VERSION ""

NS_ :

BS_:

BU_: IDCM ARC ARHUD WHUD VSP FSE_M CGW

BO_ 763 TBOX_FD_8: 32 CGW
 SG_ TBOX_FD_8_Checksum1 : 0|8@1+ (1,0) [0|255] ""  IDCM,ARC,WHUD
 SG_ TBOX_FD_8_RollingCounter1 : 8|4@1+ (1,0) [0|15] ""  IDCM,ARC,WHUD
 SG_ TBOX_V2XOutofControl_Distance : 16|8@1+ (1,0) [0|254] ""  IDCM,ARC,WHUD
 SG_ TBOX_V2XOutofControl_St : 24|2@1+ (1,0) [0|3] ""  IDCM,ARC,WHUD
 SG_ TBOX_V2XOutofControl_AlarmLevel : 26|2@1+ (1,0) [0|3] ""  IDCM,ARC,WHUD
 SG_ TBOX_V2XOutofControl_Angle : 28|10@1+ (1,0) [0|359] "°"  IDCM,ARC,WHUD
 SG_ TBOX_FD_8_Checksum2 : 64|8@1+ (1,0) [0|255] ""  IDCM,ARC,WHUD
 SG_ TBOX_FD_8_RollingCounter2 : 72|4@1+ (1,0) [0|15] ""  IDCM,ARC,WHUD
 SG_ TBOX_V2XBlindSpotorLaneChangeWarn_Type : 80|4@1+ (1,0) [0|15] ""  IDCM,ARC,WHUD
 SG_ TBOX_V2XBlindSpotorLaneChangeWarn_St : 84|2@1+ (1,0) [0|3] ""  IDCM,ARC,WHUD
 SG_ TBOX_V2XBlindSpotorLaneChangeWarn_AlarmLevel : 86|2@1+ (1,0) [0|3] ""  IDCM,ARC,WHUD
 SG_ TBOX_V2XBlindSpotorLaneChangeWarn_Distance : 88|8@1+ (1,0) [0|254] "m"  IDCM,ARC,WHUD
 SG_ TBOX_V2XBlindSpotorLaneChangeWarn_Direction : 96|4@1+ (1,0) [0|15] ""  IDCM,ARC,WHUD
 SG_ TBOX_FD_8_Checksum3 : 128|8@1+ (1,0) [0|255] ""  IDCM,ARC,WHUD
 SG_ TBOX_FD_8_RollingCounter3 : 136|4@1+ (1,0) [0|15] ""  IDCM,ARC,WHUD
 SG_ TBOX_V2XEmergencyVehicleWarn_Distance : 144|8@1+ (1,0) [0|254] "m"  IDCM,ARC,WHUD
 SG_ TBOX_V2XEmergencyVehicleWarn_St : 152|2@1+ (1,0) [0|3] ""  IDCM,ARC,WHUD
 SG_ TBOX_V2XEmergencyVehicleWarn_AlarmLevel : 154|2@1+ (1,0) [0|3] ""  IDCM,ARC,WHUD
 SG_ TBOX_V2XEmergencyVehicleWarn_Type : 156|3@1+ (1,0) [0|7] ""  IDCM,ARC,WHUD
 SG_ TBOX_V2XEmergencyVehicleWarn_Angle : 160|10@1+ (1,0) [0|359] "°"  IDCM,ARC,WHUD

BO_ 764 TBOX_FD_9: 32 CGW
 SG_ TBOX_FD_9_Checksum1 : 0|8@1+ (1,0) [0|255] ""  IDCM,ARC,WHUD
 SG_ TBOX_FD_9_RollingCounter1 : 8|4@1+ (1,0) [0|15] ""  IDCM,ARC,WHUD
 SG_ TBOX_V2XVulnerableTrafficParticipantsWarn_Distance : 16|8@1+ (1,0) [0|254] "m"  IDCM,ARC,WHUD
 SG_ TBOX_V2XVulnerableTrafficParticipantsWarn_St : 24|2@1+ (1,0) [0|3] ""  IDCM,ARC,WHUD
 SG_ TBOX_V2XVulnerableTrafficParticipantsWarn_AlarmLevel : 26|2@1+ (1,0) [0|3] ""  IDCM,ARC,WHUD
 SG_ TBOX_V2XVulnerableTrafficParticipantsWarn_Participant : 28|3@1+ (1,0) [0|7] ""  IDCM,ARC,WHUD
 SG_ TBOX_V2XVulnerableTrafficParticipantsWarn_Angle : 32|10@1+ (1,0) [0|359] "°"  IDCM,ARC,WHUD
 SG_ TBOX_FD_9_Checksum2 : 64|8@1+ (1,0) [0|255] ""  IDCM,ARC,WHUD
 SG_ TBOX_FD_9_RollingCounter2 : 72|4@1+ (1,0) [0|15] ""  IDCM,ARC,WHUD
 SG_ TBOX_V2XInVehicleSignage_Direction : 80|4@1+ (1,0) [0|15] ""  IDCM,ARC,WHUD
 SG_ TBOX_V2XInVehicleSignage_Type : 84|4@1+ (1,0) [0|15] ""  IDCM,ARC,WHUD
 SG_ TBOX_V2XInVehicleSignage_Distance : 88|8@1+ (1,0) [0|254] "m"  IDCM,ARC,WHUD
 SG_ TBOX_V2XInVehicleSignage_St : 96|2@1+ (1,0) [0|3] ""  IDCM,ARC,WHUD
 SG_ TBOX_V2XInVehicleSignage_AlarmLevel : 98|2@1+ (1,0) [0|3] ""  IDCM,ARC,WHUD
 SG_ TBOX_V2XRoadHazardWarn_St : 100|2@1+ (1,0) [0|3] ""  IDCM,ARC,WHUD
 SG_ TBOX_V2XRoadHazardWarn_AlarmLevel : 102|2@1+ (1,0) [0|3] ""  IDCM,ARC,WHUD
 SG_ TBOX_V2XRoadHazardWarn_Distance : 104|8@1+ (1,0) [0|254] "m"  IDCM,ARC,WHUD
 SG_ TBOX_V2XRoadHazardWarn_Direction : 112|4@1+ (1,0) [0|15] ""  IDCM,ARC,WHUD
 SG_ TBOX_V2XRoadHazardWarn_DangerTypes : 116|4@1+ (1,0) [0|15] ""  IDCM,ARC,WHUD
 SG_ TBOX_FD_9_Checksum3 : 128|8@1+ (1,0) [0|255] ""  IDCM,ARC,WHUD
 SG_ TBOX_FD_9_RollingCounter3 : 136|4@1+ (1,0) [0|15] ""  IDCM,ARC,WHUD
 SG_ TBOX_V2XGreenWaveSpeedGuidance_Distance : 144|8@1+ (1,0) [0|254] "m"  IDCM,ARC,WHUD
 SG_ TBOX_V2XGreenWaveSpeedGuidance_Countdown : 152|8@1+ (1,0) [0|254] "s"  IDCM,ARC,WHUD
 SG_ TBOX_V2XGreenWaveSpeedGuidance_MinSpeed : 160|8@1+ (1,0) [0|120] "km/h"  IDCM,ARC,WHUD
 SG_ TBOX_V2XGreenWaveSpeedGuidance_MaxSpeed : 168|8@1+ (1,0) [0|120] "km/h"  IDCM,ARC,WHUD
 SG_ TBOX_V2XGreenWaveSpeedGuidance_TrafficLightPoint : 176|4@1+ (1,0) [0|15] ""  IDCM,ARC,WHUD
 SG_ TBOX_V2XGreenWaveSpeedGuidance_TrafficLightSt : 180|3@1+ (1,0) [0|7] ""  IDCM,ARC,WHUD
 SG_ TBOX_V2XGreenWaveSpeedGuidance_St : 184|2@1+ (1,0) [0|3] ""  IDCM,ARC,WHUD

BO_ 765 TBOX_FD_10: 32 CGW
 SG_ TBOX_FD_10_Checksum1 : 0|8@1+ (1,0) [0|255] ""  IDCM,ARC,WHUD
 SG_ TBOX_FD_10_RollingCounter1 : 8|4@1+ (1,0) [0|15] ""  IDCM,ARC,WHUD
 SG_ TBOX_V2XRealtimeTrafficInformation_St : 16|2@1+ (1,0) [0|3] ""  IDCM,ARC,WHUD
 SG_ TBOX_V2XRealtimeTrafficInformation_Direction : 18|4@1+ (1,0) [0|15] ""  IDCM,ARC,WHUD
 SG_ TBOX_V2XRealtimeTrafficInformation_AlarmLevel : 22|2@1+ (1,0) [0|3] ""  IDCM,ARC,WHUD
 SG_ TBOX_V2XRealtimeTrafficInformation_Distance : 24|8@1+ (1,0) [0|254] "m"  IDCM,ARC,WHUD
 SG_ TBOX_V2XRealtimeTrafficInformation_Type : 32|4@1+ (1,0) [0|15] ""  IDCM,ARC,WHUD
 SG_ TBOX_V2XRealtimeTrafficInformation_Severity : 36|4@1+ (1,0) [0|15] ""  IDCM,ARC,WHUD
 SG_ TBOX_V2XRushRedLightWarn_Distance : 40|8@1+ (1,0) [0|254] "m"  IDCM,ARC,WHUD
 SG_ TBOX_V2XRushRedLightWarn_St : 48|2@1+ (1,0) [0|3] ""  IDCM,ARC,WHUD
 SG_ TBOX_V2XRushRedLightWarn_AlarmLevel : 50|2@1+ (1,0) [0|3] ""  IDCM,ARC,WHUD
 SG_ TBOX_V2XSpeedLimitWarn_St : 52|2@1+ (1,0) [0|3] ""  IDCM,ARC,WHUD
 SG_ TBOX_V2XSpeedLimitWarn_AlarmLevel : 54|2@1+ (1,0) [0|3] ""  IDCM,ARC,WHUD
 SG_ TBOX_V2XSpeedLimitWarn_Speed : 56|8@1+ (1,0) [0|120] "km/h"  IDCM,ARC,WHUD
 SG_ TBOX_FD_10_Checksum2 : 64|8@1+ (1,0) [0|255] ""  IDCM
 SG_ TBOX_FD_10_RollingCounter2 : 72|4@1+ (1,0) [0|15] ""  IDCM
 SG_ TBOX_V2X_St : 80|2@1+ (1,0) [0|3] ""  IDCM

BO_ 887 TBOX_FD_18: 32 CGW
 SG_ TBOX_AccountIDByte1 : 0|8@1+ (1,0) [0|255] ""  IDCM
 SG_ TBOX_AccountIDByte2 : 8|8@1+ (1,0) [0|255] ""  IDCM
 SG_ TBOX_AccountIDByte3 : 16|8@1+ (1,0) [0|255] ""  IDCM
 SG_ TBOX_AccountIDByte4 : 24|8@1+ (1,0) [0|255] ""  IDCM
 SG_ TBOX_AccountIDByte5 : 32|8@1+ (1,0) [0|255] ""  IDCM
 SG_ TBOX_AccountIDByte6 : 40|8@1+ (1,0) [0|255] ""  IDCM
 SG_ TBOX_AccountIDByte7 : 48|8@1+ (1,0) [0|255] ""  IDCM
 SG_ TBOX_AccountIDByte8 : 56|8@1+ (1,0) [0|255] ""  IDCM
 SG_ TBOX_AccountIDByte9 : 64|8@1+ (1,0) [0|255] ""  IDCM
 SG_ TBOX_AccountIDByte10 : 72|8@1+ (1,0) [0|255] ""  IDCM
 SG_ TBOX_AccountIDByte11 : 80|8@1+ (1,0) [0|255] ""  IDCM
 SG_ TBOX_AccountIDByte12 : 88|8@1+ (1,0) [0|255] ""  IDCM
 SG_ TBOX_AccountIDByte13 : 96|8@1+ (1,0) [0|255] ""  IDCM
 SG_ TBOX_AccountIDByte14 : 104|8@1+ (1,0) [0|255] ""  IDCM
 SG_ TBOX_AccountIDByte15 : 112|8@1+ (1,0) [0|255] ""  IDCM
 SG_ TBOX_AccountIDByte16 : 120|8@1+ (1,0) [0|255] ""  IDCM
 SG_ TBOX_AccountIDByte17 : 128|8@1+ (1,0) [0|255] ""  IDCM
 SG_ TBOX_AccountIDByte18 : 136|8@1+ (1,0) [0|255] ""  IDCM
 SG_ TBOX_AccountIDByte19 : 144|8@1+ (1,0) [0|255] ""  IDCM
 SG_ TBOX_AccountIDByte20 : 152|8@1+ (1,0) [0|255] ""  IDCM
 SG_ TBOX_AccountIDByte21 : 160|8@1+ (1,0) [0|255] ""  IDCM
 SG_ TBOX_AccountIDByte22 : 168|8@1+ (1,0) [0|255] ""  IDCM
 SG_ TBOX_AccountIDByte23 : 176|8@1+ (1,0) [0|255] ""  IDCM
 SG_ TBOX_AccountIDByte24 : 184|8@1+ (1,0) [0|255] ""  IDCM
 SG_ TBOX_AccountIDByte25 : 192|8@1+ (1,0) [0|255] ""  IDCM
 SG_ TBOX_AccountIDByte26 : 200|8@1+ (1,0) [0|255] ""  IDCM
 SG_ TBOX_AccountIDByte27 : 208|8@1+ (1,0) [0|255] ""  IDCM
 SG_ TBOX_AccountIDByte28 : 216|8@1+ (1,0) [0|255] ""  IDCM
 SG_ TBOX_AccountIDByte29 : 224|8@1+ (1,0) [0|255] ""  IDCM
 SG_ TBOX_AccountIDByte30 : 232|8@1+ (1,0) [0|255] ""  IDCM
 SG_ TBOX_AccountIDByte31 : 240|8@1+ (1,0) [0|255] ""  IDCM
 SG_ TBOX_AccountIDByte32 : 248|8@1+ (1,0) [0|255] ""  IDCM

BO_ 882 TBOX_FD_19: 32 CGW
 SG_ TBOX_XCALLIDByte0 : 0|8@1+ (1,0) [0|255] ""  IDCM
 SG_ TBOX_XCALLIDByte1 : 8|8@1+ (1,0) [0|255] ""  IDCM
 SG_ TBOX_XCALLIDByte2 : 16|8@1+ (1,0) [0|255] ""  IDCM
 SG_ TBOX_XCALLIDByte3 : 24|8@1+ (1,0) [0|255] ""  IDCM
 SG_ TBOX_XCALLIDByte4 : 32|8@1+ (1,0) [0|255] ""  IDCM
 SG_ TBOX_XCALLIDByte5 : 40|8@1+ (1,0) [0|255] ""  IDCM
 SG_ TBOX_XCALLIDByte6 : 48|8@1+ (1,0) [0|255] ""  IDCM
 SG_ TBOX_XCALLIDByte7 : 56|8@1+ (1,0) [0|255] ""  IDCM
 SG_ TBOX_XCALLIDByte8 : 64|8@1+ (1,0) [0|255] ""  IDCM
 SG_ TBOX_XCALLIDByte9 : 72|8@1+ (1,0) [0|255] ""  IDCM

BO_ 503 ADCM_FD_2: 32 CGW
 SG_ ADCM_FD2_Checksum1 : 0|8@1+ (1,0) [0|255] ""  IDCM,ARC,WHUD
 SG_ ADCM_FD2_RollingCounter1 : 8|4@1+ (1,0) [0|15] ""  IDCM,ARC,WHUD
 SG_ ADCM_LKS_TakeoverReq : 12|1@1+ (1,0) [0|1] ""  IDCM
 SG_ ADCM_LKS_St : 13|3@1+ (1,0) [0|7] ""  IDCM,ARC,WHUD
 SG_ ADCM_LKS_Type_Set : 16|2@1+ (1,0) [0|3] ""  IDCM,ARC,WHUD
 SG_ ADCM_LKS_Left_Active_St : 18|3@1+ (1,0) [0|7] ""  IDCM,ARC,WHUD
 SG_ ADCM_LKS_Right_Active_St : 21|3@1+ (1,0) [0|7] ""  IDCM,ARC,WHUD
 SG_ ADCM_LKS_Sensitivity_Set : 24|2@1+ (1,0) [0|3] ""  IDCM
 SG_ ADCM_ELK_St : 26|3@1+ (1,0) [0|7] ""  IDCM,ARC,WHUD
 SG_ ADCM_ELK_Left_Active_St : 29|3@1+ (1,0) [0|7] ""  IDCM,ARC,WHUD
 SG_ ADCM_ELK_Right_Active_St : 32|3@1+ (1,0) [0|7] ""  IDCM,ARC,WHUD
 SG_ ADCM_RCW_St : 35|3@1+ (1,0) [0|7] ""  IDCM,ARC,WHUD
 SG_ ADCM_RCW_Warn_St : 38|2@1+ (1,0) [0|3] ""  IDCM,ARC,WHUD
 SG_ ADCM_LCA_St : 40|3@1+ (1,0) [0|7] ""  IDCM,ARC,WHUD
 SG_ ADCM_LCA_Right_Warn_St : 43|2@1+ (1,0) [0|3] ""  IDCM,ARC,WHUD
 SG_ ADCM_LCA_Left_Warn_St : 45|2@1+ (1,0) [0|3] ""  IDCM,ARC,WHUD
 SG_ ADCM_RCTA_St : 48|3@1+ (1,0) [0|7] ""  IDCM
 SG_ ADCM_RCTA_Right_Warn_St : 51|2@1+ (1,0) [0|3] ""  IDCM
 SG_ ADCM_RCTA_Left_Warn_St : 53|2@1+ (1,0) [0|3] ""  IDCM
 SG_ ADCM_AHB_St : 56|3@1+ (1,0) [0|7] ""  IDCM
 SG_ ADCM_AHB_Ctrl_St : 59|2@1+ (1,0) [0|3] ""  IDCM
 SG_ ADCM_FD2_Checksum2 : 64|8@1+ (1,0) [0|255] ""  IDCM,ARC,WHUD
 SG_ ADCM_FD2_RollingCounter2 : 72|4@1+ (1,0) [0|15] ""  IDCM,ARC,WHUD
 SG_ ADCM_ACC_UnavailableReason : 76|4@1+ (1,0) [0|15] ""  IDCM
 SG_ ADCM_ACC_St : 80|3@1+ (1,0) [0|7] ""  IDCM,ARC,WHUD
 SG_ ADCM_ACC_Warn_St : 83|3@1+ (1,0) [0|7] ""  IDCM
 SG_ ADCM_ACC_TimeGap : 86|2@1+ (1,0) [0|3] ""  IDCM
 SG_ ADCM_ACC_TargetSpeed : 88|7@1+ (1,30) [30|150] "kph"  IDCM,ARC,WHUD
 SG_ ADCM_ACC_GoNotifier : 95|1@1+ (1,0) [0|1] ""  IDCM
 SG_ ADCM_ISA_St : 96|3@1+ (1,0) [0|7] ""  IDCM,ARC,WHUD
 SG_ ADCM_ISA_LimitSpeed : 99|5@1+ (1,0) [0|31] ""  IDCM,ARC,WHUD
 SG_ ADCM_ISA_Operating_St : 104|3@1+ (1,0) [0|7] ""  IDCM
 SG_ ADCM_ISA_Warn_St : 107|1@1+ (1,0) [0|1] "-"  IDCM,ARC,WHUD
 SG_ ADCM_ISA_SpeedLimitype : 108|2@1+ (1,0) [0|3] "-"  IDCM
 SG_ ADCM_ISA_SpeedLimitUnit : 110|2@1+ (1,0) [0|3] ""  IDCM
 SG_ ADCM_ISA_WarningOffset_Set : 112|3@1+ (1,0) [0|7] ""  IDCM
 SG_ ADCM_ValetMode_AccDisable_St : 115|2@1+ (1,0) [0|3] ""  IDCM
 SG_ ADCM_FD2_Checksum3 : 128|8@1+ (1,0) [0|255] ""  IDCM,ARC,WHUD
 SG_ ADCM_FD2_RollingCounter3 : 136|4@1+ (1,0) [0|15] ""  IDCM,ARC,WHUD
 SG_ ADCM_FCS_TargetType : 140|4@1+ (1,0) [0|15] ""  IDCM,ARC,WHUD
 SG_ ADCM_FCS_St : 144|3@1+ (1,0) [0|7] ""  IDCM,ARC,WHUD
 SG_ ADCM_FCS_Active_St : 147|3@1+ (1,0) [0|7] ""  IDCM,ARC,WHUD
 SG_ ADCM_FCTA_Left_TargetType : 152|4@1+ (1,0) [0|15] ""  IDCM
 SG_ ADCM_FCTA_Right_TargetType : 156|4@1+ (1,0) [0|15] ""  IDCM
 SG_ ADCM_FCTA_Left_Active_St : 160|3@1+ (1,0) [0|7] ""  IDCM,ARC,WHUD
 SG_ ADCM_FCTA_Right_Active_St : 163|3@1+ (1,0) [0|7] ""  IDCM,ARC,WHUD
 SG_ ADCM_FCTA_St : 168|3@1+ (1,0) [0|7] ""  IDCM,ARC,WHUD
 SG_ ADCM_DetecCloseObjectFunctionRsp : 171|2@1+ (1,0) [0|3] ""  IDCM
 SG_ ADCM_DOW_St : 173|3@1+ (1,0) [0|7] ""  IDCM
 SG_ ADCM_DOW_FL_Warn_St : 176|2@1+ (1,0) [0|3] ""  IDCM
 SG_ ADCM_DOW_RL_Warn_St : 178|2@1+ (1,0) [0|3] ""  IDCM
 SG_ ADCM_DOW_FR_Warn_St : 180|2@1+ (1,0) [0|3] ""  IDCM
 SG_ ADCM_DOW_RR_Warn_St : 182|2@1+ (1,0) [0|3] ""  IDCM
 SG_ ADCM_FRCloseObjectWarn : 184|2@1+ (1,0) [0|3] ""  IDCM
 SG_ ADCM_RLCloseObjectWarn : 186|2@1+ (1,0) [0|3] ""  IDCM
 SG_ ADCM_RRCloseObjectWarn : 188|2@1+ (1,0) [0|3] ""  IDCM
 SG_ ADCM_FLCloseObjectWarn : 190|2@1+ (1,0) [0|3] ""  IDCM

BO_ 505 ADCM_FD_3: 32 CGW
 SG_ ADCM_FD3_Checksum1 : 0|8@1+ (1,0) [0|255] ""  IDCM,ARC,WHUD
 SG_ ADCM_FD3_RollingCounter1 : 8|4@1+ (1,0) [0|15] ""  IDCM,ARC,WHUD
 SG_ ADCM_Pilot_Warn_St : 12|4@1+ (1,0) [0|15] ""  IDCM,ARC,WHUD
 SG_ ADCM_Pilot_Type : 16|3@1+ (1,0) [0|3] ""  IDCM,ARC,WHUD
 SG_ ADCM_Pilot_Available_St : 19|3@1+ (1,0) [0|3] ""  IDCM,ARC,WHUD
 SG_ ADCM_PilotLateral_St : 24|3@1+ (1,0) [0|7] ""  IDCM,ARC,WHUD
 SG_ ADCM_FD3_Checksum2 : 64|8@1+ (1,0) [0|255] ""  IDCM
 SG_ ADCM_FD3_RollingCounter2 : 72|4@1+ (1,0) [0|15] ""  IDCM
 SG_ ADCM_HWA_ILC_Left_St : 76|4@1+ (1,0) [0|15] ""  IDCM
 SG_ ADCM_HWA_ILC_Right_St : 80|4@1+ (1,0) [0|15] ""  IDCM
 SG_ ADCM_HWA_ILC_Set : 84|2@1+ (1,0) [0|3] ""  IDCM
 SG_ ADCM_HWA_ILC_TurnLampReq : 86|2@1+ (1,0) [0|3] ""  IDCM
 SG_ ADCM_HWA_ILC_AbortReason : 88|4@1+ (1,0) [0|15] ""  IDCM
 SG_ ADCM_HWA_ILC_Left_Warn : 92|1@1+ (1,0) [0|1] ""  IDCM
 SG_ ADCM_HWA_ILC_Right_Warn : 93|1@1+ (1,0) [0|1] ""  IDCM
 SG_ ADCM_HWA_ILC_HandsonReq : 94|1@1+ (1,0) [0|1] ""  IDCM,ARC,WHUD

BO_ 576 ADCM_FD_4: 32 CGW
 SG_ ADCM_ACC_TrackTarget0_LateralPosition : 0|10@1+ (0.1,-51.2) [-51.2|51] "m"  IDCM,ARC,WHUD
 SG_ ADCM_ACC_TrackTarget0_ObjectType : 10|4@1+ (1,0) [0|15] ""  IDCM,ARC,WHUD
 SG_ ADCM_ACC_TrackTarget0_St : 14|1@1+ (1,0) [0|1] ""  IDCM,ARC,WHUD
 SG_ ADCM_ACC_TrackTarget0_LongitudinalPosition : 16|8@1+ (1,0) [0|254] "m"  IDCM,ARC,WHUD
 SG_ ADCM_ACC_TrackTarget1_LateralPosition : 32|10@1+ (0.1,-51.2) [-51.2|51] "m"  IDCM,ARC,WHUD
 SG_ ADCM_ACC_TrackTarget1_ObjectType : 42|4@1+ (1,0) [0|15] ""  IDCM,ARC,WHUD
 SG_ ADCM_ACC_TrackTarget1_St : 46|1@1+ (1,0) [0|1] ""  IDCM,ARC,WHUD
 SG_ ADCM_ACC_TrackTarget1_LongitudinalPosition : 48|8@1+ (1,0) [0|254] "m"  IDCM,ARC,WHUD
 SG_ ADCM_ACC_TrackTarget2_LateralPosition : 64|10@1+ (0.1,-51.2) [-51.2|51] "m"  IDCM,ARC,WHUD
 SG_ ADCM_ACC_TrackTarget2_ObjectType : 74|4@1+ (1,0) [0|15] ""  IDCM,ARC,WHUD
 SG_ ADCM_ACC_TrackTarget2_St : 78|1@1+ (1,0) [0|1] ""  IDCM,ARC,WHUD
 SG_ ADCM_ACC_TrackTarget2_LongitudinalPosition : 80|8@1+ (1,0) [0|254] "m"  IDCM,ARC,WHUD
 SG_ ADCM_ACC_TrackTarget3_LateralPosition : 96|10@1+ (0.1,-51.2) [-51.2|51] "m"  IDCM,ARC,WHUD
 SG_ ADCM_ACC_TrackTarget3_ObjectType : 106|4@1+ (1,0) [0|15] ""  IDCM,ARC,WHUD
 SG_ ADCM_ACC_TrackTarget3_St : 110|1@1+ (1,0) [0|1] ""  IDCM,ARC,WHUD
 SG_ ADCM_ACC_TrackTarget3_LongitudinalPosition : 112|8@1+ (1,0) [0|254] "m"  IDCM,ARC,WHUD

BO_ 578 ADCM_FD_5: 32 CGW
 SG_ ADCM_Line_1_Display : 0|2@1+ (1,0) [0|3] ""  IDCM,ARC,WHUD
 SG_ ADCM_Line_1_Type : 2|4@1+ (1,0) [0|15] ""  IDCM,ARC,WHUD
 SG_ ADCM_Line_1_A0 : 8|11@1+ (0.01,-10.23) [-10.23|10.23] "m"  IDCM,ARC,WHUD
 SG_ ADCM_Line_1_A1 : 20|11@1+ (0.001,-1.023) [-1.023|1.023] "rad"  IDCM,ARC,WHUD
 SG_ ADCM_Line_1_A2 : 32|11@1+ (0.00001,-0.01023) [-0.01023|0.01023] "1/m"  IDCM,ARC,WHUD
 SG_ ADCM_Line_1_A3 : 48|16@1+ (0.00000001,-0.00032768) [-0.00032768|0.00032767] "1/m2"  IDCM,ARC,WHUD
 SG_ ADCM_Line_2_Display : 64|2@1+ (1,0) [0|3] ""  IDCM,ARC,WHUD
 SG_ ADCM_Line_2_Type : 66|4@1+ (1,0) [0|15] ""  IDCM,ARC,WHUD
 SG_ ADCM_Line_2_A0 : 72|11@1+ (0.01,-10.23) [-10.23|10.23] "m"  IDCM,ARC,WHUD
 SG_ ADCM_Line_2_A1 : 84|11@1+ (0.001,-1.023) [-1.023|1.023] "rad"  IDCM,ARC,WHUD
 SG_ ADCM_Line_2_A2 : 96|11@1+ (0.00001,-0.01023) [-0.01023|0.01023] "1/m"  IDCM,ARC,WHUD
 SG_ ADCM_FD5_Reserved8 : 107|5@1+ (1,0) [0|0] ""  IDCM,ARC,WHUD
 SG_ ADCM_Line_2_A3 : 112|16@1+ (0.00000001,-0.00032768) [-0.00032768|0.00032767] "1/m2"  IDCM,ARC,WHUD

BO_ 580 ADCM_FD_6: 32 CGW
 SG_ ADCM_Line_3_Display : 0|2@1+ (1,0) [0|3] ""  IDCM,ARC,WHUD
 SG_ ADCM_Line_3_Type : 2|4@1+ (1,0) [0|15] ""  IDCM,ARC,WHUD
 SG_ ADCM_Line_3_A0 : 8|11@1+ (0.01,-10.23) [-10.23|10.23] "m"  IDCM,ARC,WHUD
 SG_ ADCM_Line_3_A1 : 20|11@1+ (0.001,-1.023) [-1.023|1.023] "rad"  IDCM,ARC,WHUD
 SG_ ADCM_Line_3_A2 : 32|11@1+ (0.00001,-0.01023) [-0.01023|0.01023] "1/m"  IDCM,ARC,WHUD
 SG_ ADCM_Line_3_A3 : 48|16@1+ (0.00000001,-0.00032768) [-0.00032768|0.00032767] "1/m2"  IDCM,ARC,WHUD
 SG_ ADCM_Line_4_Display : 64|2@1+ (1,0) [0|3] ""  IDCM,ARC,WHUD
 SG_ ADCM_Line_4_Type : 66|4@1+ (1,0) [0|15] ""  IDCM,ARC,WHUD
 SG_ ADCM_Line_4_A0 : 72|11@1+ (0.01,-10.23) [-10.23|10.23] "m"  IDCM,ARC,WHUD
 SG_ ADCM_Line_4_A1 : 84|11@1+ (0.001,-1.023) [-1.023|1.023] "rad"  IDCM,ARC,WHUD
 SG_ ADCM_Line_4_A2 : 96|11@1+ (0.00001,-0.01023) [-0.01023|0.01023] "1/m"  IDCM,ARC,WHUD
 SG_ ADCM_Line_4_A3 : 112|16@1+ (0.00000001,-0.00032768) [-0.00032768|0.00032767] "1/m2"  IDCM,ARC,WHUD

BO_ 582 ADCM_FD_7: 32 CGW
 SG_ ADCM_SystemSt : 0|3@1+ (1,0) [0|7] ""  IDCM
 SG_ ADCM_FMRRSensorBloc_St : 64|1@1+ (1,0) [0|1] ""  IDCM
 SG_ ADCM_FCamSensorBloc_St : 65|1@1+ (1,0) [0|1] ""  IDCM
 SG_ ADCM_ReserveSensorBloc_St : 66|1@1+ (1,0) [0|1] ""  IDCM
 SG_ ADCM_LFSRRSensorBloc_St : 67|1@1+ (1,0) [0|1] ""  IDCM
 SG_ ADCM_LRSRRSensorBloc_St : 68|1@1+ (1,0) [0|1] ""  IDCM
 SG_ ADCM_RRSRRSensorBloc_St : 69|1@1+ (1,0) [0|1] ""  IDCM
 SG_ ADCM_RFSRRSensorBloc_St : 70|1@1+ (1,0) [0|1] ""  IDCM
 SG_ ADCM_FMRRSensorCali_St : 96|1@1+ (1,0) [0|1] ""  IDCM
 SG_ ADCM_FCamSensorCali_St : 97|1@1+ (1,0) [0|1] ""  IDCM
 SG_ ADCM_ReserveSensorCali_St : 98|1@1+ (1,0) [0|1] ""  IDCM
 SG_ ADCM_LFSRRSensorCali_St : 99|1@1+ (1,0) [0|1] ""  IDCM
 SG_ ADCM_LRSRRSensorCali_St : 100|1@1+ (1,0) [0|1] ""  IDCM
 SG_ ADCM_RRSRRSensorCali_St : 101|1@1+ (1,0) [0|1] ""  IDCM
 SG_ ADCM_RFSRRSensorCali_St : 102|1@1+ (1,0) [0|1] ""  IDCM
 SG_ ADCM_FMRRSensorFail_St : 128|1@1+ (1,0) [0|1] ""  IDCM
 SG_ ADCM_FCamSensorFail_St : 129|1@1+ (1,0) [0|1] ""  IDCM
 SG_ ADCM_ReserveSensorFail_St : 130|1@1+ (1,0) [0|1] ""  IDCM
 SG_ ADCM_LFSRRSensorFail_St : 131|1@1+ (1,0) [0|1] ""  IDCM
 SG_ ADCM_LRSRRSensorFail_St : 132|1@1+ (1,0) [0|1] ""  IDCM
 SG_ ADCM_RRSRRSensorFail_St : 133|1@1+ (1,0) [0|1] ""  IDCM
 SG_ ADCM_RFSRRSensorFail_St : 134|1@1+ (1,0) [0|1] ""  IDCM

BO_ 405 APA_FD_2: 32 CGW
 SG_ APA_FD2_Checksum1 : 0|8@1+ (1,0) [0|255] ""  IDCM
 SG_ APA_FD2_RollingCounter1 : 8|4@1+ (1,0) [0|15] ""  IDCM
 SG_ APA_ParkingState : 12|4@1+ (1,0) [0|15] ""  IDCM
 SG_ APA_ButtonPress_St_Reserved : 16|2@1+ (1,0) [0|3] ""  IDCM
 SG_ APA_QuitReason_Ind : 18|6@1+ (1,0) [0|63] ""  IDCM
 SG_ APA_Recover_Ind : 24|3@1+ (1,0) [0|7] ""  IDCM
 SG_ APA_DriverOperate_Ind : 27|5@1+ (1,0) [0|31] ""  IDCM
 SG_ APA_ActiveSubFun : 32|4@1+ (1,0) [0|15] ""  IDCM
 SG_ APA_SelectParkSide_Ind : 36|2@1+ (1,0) [0|3] ""  IDCM
 SG_ APA_SelectParkTypeInd_Reserved : 38|2@1+ (1,0) [0|3] ""  IDCM
 SG_ APA_Left1stParkSlotType : 40|3@1+ (1,0) [0|7] ""  IDCM
 SG_ APA_Left2cdParkSlotType : 43|3@1+ (1,0) [0|7] ""  IDCM
 SG_ APA_APAAvaliable : 46|1@1+ (1,0) [0|1] ""  IDCM
 SG_ APA_RPAAvaliable : 47|1@1+ (1,0) [0|1] ""  IDCM
 SG_ APA_Left3rdParkSlotType : 48|3@1+ (1,0) [0|7] ""  IDCM
 SG_ APA_Right1stParkSlotType : 51|3@1+ (1,0) [0|7] ""  IDCM
 SG_ APA_Right2cdParkSlotType : 56|3@1+ (1,0) [0|7] ""  IDCM
 SG_ APA_Right3rdParkSlotType : 59|3@1+ (1,0) [0|7] ""  IDCM
 SG_ APA_FD2_Checksum2 : 64|8@1+ (1,0) [0|255] ""  IDCM
 SG_ APA_FD2_RollingCounter2 : 72|4@1+ (1,0) [0|15] ""  IDCM
 SG_ APA_IDCM_SVSIntelligentViewChangeSwitch_St : 80|2@1+ (1,0) [0|3] ""  IDCM
 SG_ APA_IDCM_SVSdefaulttopviewSwitch_St : 82|2@1+ (1,0) [0|3] ""  IDCM
 SG_ APA_IDCM_SVSdefaultnormalviewSwitch_St : 84|2@1+ (1,0) [0|3] ""  IDCM
 SG_ APA_IDCM_SVSBootAnimationswitch_St : 86|2@1+ (1,0) [0|3] ""  IDCM
 SG_ APA_ParkingProgressBar_Ind : 88|7@1+ (1,0) [0|100] "%"  IDCM
 SG_ APA_SVC_FrontCamera_St : 96|2@1+ (1,0) [0|3] ""  IDCM
 SG_ APA_SVC_LeftCamera_St : 98|2@1+ (1,0) [0|3] ""  IDCM
 SG_ APA_SVC_RightCamera_St : 100|2@1+ (1,0) [0|3] ""  IDCM
 SG_ APA_SVC_RearCamera_St : 102|2@1+ (1,0) [0|3] ""  IDCM
 SG_ APA_SVS_System_St : 104|1@1+ (1,0) [0|1] ""  IDCM
 SG_ APA_SVS_Active_St : 105|1@1+ (1,0) [0|1] ""  IDCM
 SG_ APA_SVS_SystemUnavailableReson : 106|4@1+ (1,0) [0|15] ""  IDCM
 SG_ APA_IDCM_PASAcousticWarn_St : 110|2@1+ (1,0) [0|3] ""  IDCM
 SG_ APA_SVS_CurrentView : 112|5@1+ (1,0) [0|31] ""  IDCM
 SG_ APA_IDCM_ObjectOverlay_St : 117|2@1+ (1,0) [0|3] ""  IDCM
 SG_ APA_SVS_BasPlateTex_St : 120|2@1+ (1,0) [0|3] ""  IDCM
 SG_ APA_IDCM_SVSTrajectoryOverlay_St : 122|2@1+ (1,0) [0|3] ""  IDCM
 SG_ APA_SVSMODE_FD : 124|2@1+ (1,0) [0|3] ""  IDCM
 SG_ APA_FrontPMAEB_St : 140|4@1+ (1,0) [0|15] ""  IDCM
 SG_ APA_RearPMAEB_St : 144|4@1+ (1,0) [0|15] ""  IDCM
 SG_ APA_PMAEB_Setting_St : 148|3@1+ (1,0) [0|7] ""  IDCM

BO_ 584 APA_FD_3: 32 CGW
 SG_ APA_FD3_Checksum1 : 0|8@1+ (1,0) [0|255] ""  IDCM
 SG_ APA_FD3_RollingCounter1 : 8|4@1+ (1,0) [0|15] ""  IDCM
 SG_ APA_PAS_SwFdbkIDCMPAS_Reserved : 16|1@1+ (1,0) [0|1] ""  IDCM
 SG_ APA_PAS_WorkingMode : 17|4@1+ (1,0) [0|15] ""  IDCM
 SG_ APA_PAS_BuzzerWarning : 21|3@1+ (1,0) [0|7] ""  IDCM
 SG_ APA_DefaultAeraObstacleWarning_Reserved : 24|2@1+ (1,0) [0|3] ""  IDCM
 SG_ APA_PASFLDistance : 32|8@1+ (1,0) [0|250] "cm"  IDCM
 SG_ APA_PASFMLDistance : 40|8@1+ (1,0) [0|250] "cm"  IDCM
 SG_ APA_PASFMRDistance : 48|8@1+ (1,0) [0|250] "cm"  IDCM
 SG_ APA_PASFRDistance : 56|8@1+ (1,0) [0|250] "cm"  IDCM
 SG_ APA_FD3_Checksum2 : 64|8@1+ (1,0) [0|255] ""  IDCM
 SG_ APA_FD3_RollingCounter2 : 72|4@1+ (1,0) [0|15] ""  IDCM
 SG_ APA_PASRLDistance : 80|8@1+ (1,0) [0|250] "cm"  IDCM
 SG_ APA_PASRRDistance : 88|8@1+ (1,0) [0|250] "cm"  IDCM
 SG_ APA_PASRMLDistance : 96|8@1+ (1,0) [0|250] "cm"  IDCM
 SG_ APA_PASRMRDistance : 104|8@1+ (1,0) [0|250] "cm"  IDCM
 SG_ APA_FSideAreaScand : 112|1@1+ (1,0) [0|1] ""  IDCM
 SG_ APA_FMSideAreaScand : 113|1@1+ (1,0) [0|1] ""  IDCM
 SG_ APA_RSideAreaScand : 114|1@1+ (1,0) [0|1] ""  IDCM
 SG_ APA_RMSideAreaScand : 115|1@1+ (1,0) [0|1] ""  IDCM
 SG_ APA_FD3_Checksum3 : 128|8@1+ (1,0) [0|255] ""  IDCM
 SG_ APA_FD3_RollingCounter3 : 136|4@1+ (1,0) [0|15] ""  IDCM
 SG_ APA_SDW_FLSideDistance : 144|8@1+ (1,0) [0|250] "cm"  IDCM
 SG_ APA_SDW_FRSideDistance : 152|8@1+ (1,0) [0|250] "cm"  IDCM
 SG_ APA_SDW_RLSideDistance : 160|8@1+ (1,0) [0|250] "cm"  IDCM
 SG_ APA_SDW_RRSideDistance : 168|8@1+ (1,0) [0|250] "cm"  IDCM
 SG_ APA_SDW_FMLSideDistance : 176|8@1+ (1,0) [0|250] "cm"  IDCM
 SG_ APA_SDW_FMRSideDistance : 184|8@1+ (1,0) [0|250] "cm"  IDCM
 SG_ APA_FD3_Checksum4 : 192|8@1+ (1,0) [0|255] ""  IDCM
 SG_ APA_FD3_RollingCounter4 : 200|4@1+ (1,0) [0|15] ""  IDCM
 SG_ APA_SDW_RMLSideDistance : 208|8@1+ (1,0) [0|250] "cm"  IDCM
 SG_ APA_SDW_RMRSideDistance : 216|8@1+ (1,0) [0|250] "cm"  IDCM

BO_ 586 APA_FD_4: 32 CGW
 SG_ APA_L1SlotEdge1LateralPosition : 0|16@1+ (0.01,-327.67) [-327.67|327.67] "m"  IDCM
 SG_ APA_L1SlotEdge1LongitudinalPosition : 16|16@1+ (0.01,-327.67) [-327.67|327.67] "m"  IDCM
 SG_ APA_L1SlotEdge2LateralPosition : 32|16@1+ (0.01,-327.67) [-327.67|327.67] "m"  IDCM
 SG_ APA_L1SlotEdge2LongitudinalPosition : 48|16@1+ (0.01,-327.67) [-327.67|327.67] "m"  IDCM
 SG_ APA_L1SlotEdge3LateralPosition_Reserved : 64|16@1+ (0.01,-327.67) [-327.67|327.67] "m"  IDCM
 SG_ APA_L1SlotEdge3LongitudinalPosition_Reserved : 80|16@1+ (0.01,-327.67) [-327.67|327.67] "m"  IDCM
 SG_ APA_L1SlotEdge4LateralPosition_Reserved : 96|16@1+ (0.01,-327.67) [-327.67|327.67] "m"  IDCM
 SG_ APA_L1SlotEdge4LongitudinalPosition_Reserved : 112|16@1+ (0.01,-327.67) [-327.67|327.67] "m"  IDCM
 SG_ APA_L2SlotEdge1LateralPosition : 128|16@1+ (0.01,-327.67) [-327.67|327.67] "m"  IDCM
 SG_ APA_L2SlotEdge1LongitudinalPosition : 144|16@1+ (0.01,-327.67) [-327.67|327.67] "m"  IDCM
 SG_ APA_L2SlotEdge2LateralPosition : 160|16@1+ (0.01,-327.67) [-327.67|327.67] "m"  IDCM
 SG_ APA_L2SlotEdge2LongitudinalPosition : 176|16@1+ (0.01,-327.67) [-327.67|327.67] "m"  IDCM
 SG_ APA_L2SlotEdge3LateralPosition_Reserved : 192|16@1+ (0.01,-327.67) [-327.67|327.67] "m"  IDCM
 SG_ APA_L2SlotEdge3LongitudinalPosition_Reserved : 208|16@1+ (0.01,-327.67) [-327.67|327.67] "m"  IDCM
 SG_ APA_L2SlotEdge4LateralPosition_Reserved : 224|16@1+ (0.01,-327.67) [-327.67|327.67] "m"  IDCM
 SG_ APA_L2SlotEdge4LongitudinalPosition_Reserved : 240|16@1+ (0.01,-327.67) [-327.67|327.67] "m"  IDCM

BO_ 588 APA_FD_5: 32 CGW
 SG_ APA_L3SlotEdge1LateralPosition : 0|16@1+ (0.01,-327.67) [-327.67|327.67] "m"  IDCM
 SG_ APA_L3SlotEdge1LongitudinalPosition : 16|16@1+ (0.01,-327.67) [-327.67|327.67] "m"  IDCM
 SG_ APA_L3SlotEdge2LateralPosition : 32|16@1+ (0.01,-327.67) [-327.67|327.67] "m"  IDCM
 SG_ APA_L3SlotEdge2LongitudinalPosition : 48|16@1+ (0.01,-327.67) [-327.67|327.67] "m"  IDCM
 SG_ APA_L3SlotEdge3LateralPosition_Reserved : 64|16@1+ (0.01,-327.67) [-327.67|327.67] "m"  IDCM
 SG_ APA_L3SlotEdge3LongitudinalPosition_Reserved : 80|16@1+ (0.01,-327.67) [-327.67|327.67] "m"  IDCM
 SG_ APA_L3SlotEdge4LateralPosition_Reserved : 96|16@1+ (0.01,-327.67) [-327.67|327.67] "m"  IDCM
 SG_ APA_L3SlotEdge4LongitudinalPosition_Reserved : 112|16@1+ (0.01,-327.67) [-327.67|327.67] "m"  IDCM
 SG_ APA_R1SlotEdge1LateralPosition : 128|16@1+ (0.01,-327.67) [-327.67|327.67] "m"  IDCM
 SG_ APA_R1SlotEdge1LongitudinalPosition : 144|16@1+ (0.01,-327.67) [-327.67|327.67] "m"  IDCM
 SG_ APA_R1SlotEdge2LateralPosition : 160|16@1+ (0.01,-327.67) [-327.67|327.67] "m"  IDCM
 SG_ APA_R1SlotEdge2LongitudinalPosition : 176|16@1+ (0.01,-327.67) [-327.67|327.67] "m"  IDCM
 SG_ APA_R1SlotEdge3LateralPosition_Reserved : 192|16@1+ (0.01,-327.67) [-327.67|327.67] "m"  IDCM
 SG_ APA_R1SlotEdge3LongitudinalPosition_Reserved : 208|16@1+ (0.01,-327.67) [-327.67|327.67] "m"  IDCM
 SG_ APA_R1SlotEdge4LateralPosition_Reserved : 224|16@1+ (0.01,-327.67) [-327.67|327.67] "m"  IDCM
 SG_ APA_R1SlotEdge4LongitudinalPosition_Reserved : 240|16@1+ (0.01,-327.67) [-327.67|327.67] "m"  IDCM

BO_ 590 APA_FD_6: 32 CGW
 SG_ APA_R2SlotEdge1LateralPosition : 0|16@1+ (0.01,-327.67) [-327.67|327.67] "m"  IDCM
 SG_ APA_R2SlotEdge1LongitudinalPosition : 16|16@1+ (0.01,-327.67) [-327.67|327.67] "m"  IDCM
 SG_ APA_R2SlotEdge2LateralPosition : 32|16@1+ (0.01,-327.67) [-327.67|327.67] "m"  IDCM
 SG_ APA_R2SlotEdge2LongitudinalPosition : 48|16@1+ (0.01,-327.67) [-327.67|327.67] "m"  IDCM
 SG_ APA_R2SlotEdge3LateralPosition_Reserved : 64|16@1+ (0.01,-327.67) [-327.67|327.67] "m"  IDCM
 SG_ APA_R2SlotEdge3LongitudinalPosition_Reserved : 80|16@1+ (0.01,-327.67) [-327.67|327.67] "m"  IDCM
 SG_ APA_R2SlotEdge4LateralPosition_Reserved : 96|16@1+ (0.01,-327.67) [-327.67|327.67] "m"  IDCM
 SG_ APA_R2SlotEdge4LongitudinalPosition_Reserved : 112|16@1+ (0.01,-327.67) [-327.67|327.67] "m"  IDCM
 SG_ APA_R3SlotEdge1LateralPosition : 128|16@1+ (0.01,-327.67) [-327.67|327.67] "m"  IDCM
 SG_ APA_R3SlotEdge1LongitudinalPosition : 144|16@1+ (0.01,-327.67) [-327.67|327.67] "m"  IDCM
 SG_ APA_R3SlotEdge2LateralPosition : 160|16@1+ (0.01,-327.67) [-327.67|327.67] "m"  IDCM
 SG_ APA_R3SlotEdge2LongitudinalPosition : 176|16@1+ (0.01,-327.67) [-327.67|327.67] "m"  IDCM
 SG_ APA_R3SlotEdge3LateralPosition_Reserved : 192|16@1+ (0.01,-327.67) [-327.67|327.67] "m"  IDCM
 SG_ APA_R3SlotEdge3LongitudinalPosition_Reserved : 208|16@1+ (0.01,-327.67) [-327.67|327.67] "m"  IDCM
 SG_ APA_R3SlotEdge4LateralPosition_Reserved : 224|16@1+ (0.01,-327.67) [-327.67|327.67] "m"  IDCM
 SG_ APA_R3SlotEdge4LongitudinalPosition_Reserved : 240|16@1+ (0.01,-327.67) [-327.67|327.67] "m"  IDCM

BO_ 596 DSM_FD_1: 32 CGW
 SG_ DSM_FD2_Checksum1 : 0|8@1+ (1,0) [0|255] ""  IDCM,ARC
 SG_ DSM_FD2_RollingCounter1 : 8|4@1+ (1,0) [0|15] ""  IDCM,ARC
 SG_ DSM_DriverWatchRegion : 12|4@1+ (1,0) [0|15] ""  IDCM
 SG_ DSM_SystemError_St : 16|3@1+ (1,0) [0|7] ""  IDCM
 SG_ DSM_DriverDetect_St : 19|3@1+ (1,0) [0|7] ""  IDCM
 SG_ DSM_FatigueFunction_St : 22|2@1+ (1,0) [0|3] ""  IDCM
 SG_ DSM_FatigueWarn_St : 24|3@1+ (1,0) [0|7] ""  IDCM
 SG_ DSM_L3DriverFatigue_St : 27|3@1+ (1,0) [0|7] ""  IDCM
 SG_ DSM_L3DriverDistraction_St : 32|3@1+ (1,0) [0|7] ""  IDCM
 SG_ DSM_FD2_Checksum2 : 64|8@1+ (1,0) [0|255] ""  IDCM
 SG_ DSM_FD2_RollingCounter2 : 72|4@1+ (1,0) [0|15] ""  IDCM
 SG_ DSM_Response_RecognitionFaceStatus : 76|3@1+ (1,0) [0|7] ""  IDCM
 SG_ DSM_Response_UserID : 80|8@1+ (1,0) [0|255] ""  IDCM
 SG_ DSM_UserID_SourceCode : 96|32@1+ (1,0) [0|0] ""  IDCM
 SG_ DSM_HeadPositionX : 128|16@1+ (0.0305,-1000) [-1000|998.8175] "mm"  IDCM,ARC
 SG_ DSM_HeadPositionY : 144|16@1+ (0.0305,-1000) [-1000|998.8175] "mm"  IDCM,ARC
 SG_ DSM_HeadPositionZ : 160|16@1+ (0.0305,-1000) [-1000|998.8175] "mm"  IDCM,ARC
 SG_ DSM_HeadAngleX : 176|16@1+ (0.0031,-100) [-100|103.1585] "degree"  IDCM,ARC
 SG_ DSM_HeadAngleY : 192|16@1+ (0.0031,-100) [-100|103.1585] "degree"  IDCM,ARC

BO_ 385 ACU_FD_1: 32 CGW
 SG_ ACU_1_Checksum1 : 0|8@1+ (1,0) [0|255] ""  IDCM
 SG_ ACU_1_RollingCounter1 : 8|4@1+ (1,0) [0|15] ""  IDCM
 SG_ ACU_FrontCrashOutput_St : 16|1@1+ (1,0) [0|1] ""  IDCM
 SG_ ACU_DriverSideCrashOutput_St : 17|1@1+ (1,0) [0|1] ""  IDCM
 SG_ ACU_PassengerSideCrashOutput_St : 18|1@1+ (1,0) [0|1] ""  IDCM
 SG_ ACU_RearSideCrashOutput_St : 19|1@1+ (1,0) [0|1] ""  IDCM
 SG_ ACU_WarnLampSt : 20|2@1+ (1,0) [0|3] ""  IDCM
 SG_ ACU_PassengerAirbagSt : 22|1@1+ (1,0) [0|1] ""  IDCM
 SG_ ACU_1_Checksum2 : 64|8@1+ (1,0) [0|255] ""  IDCM,VSP
 SG_ ACU_1_RollingCounter2 : 72|4@1+ (1,0) [0|15] ""  IDCM,VSP
 SG_ ACU_DriverSeatBelt_St : 80|1@1+ (1,0) [0|1] ""  IDCM,VSP
 SG_ ACU_DriverSeatBelt_Valid : 81|1@1+ (1,0) [0|1] ""  IDCM,VSP
 SG_ ACU_DriverSBR_St : 82|2@1+ (1,0) [0|3] ""  IDCM
 SG_ ACU_PassengerSBR_St : 84|2@1+ (1,0) [0|3] ""  IDCM
 SG_ ACU_SRLSBR_St : 86|2@1+ (1,0) [0|3] ""  IDCM
 SG_ ACU_SRRSBR_St : 88|2@1+ (1,0) [0|3] ""  IDCM
 SG_ ACU_SeatBeltSoundReminder_St : 90|1@1+ (1,0) [0|1] ""  IDCM

BO_ 386 ACU_FD_2: 32 CGW
 SG_ ACU_2_Checksum1 : 0|8@1+ (1,0) [0|255] ""  IDCM,ARC
 SG_ ACU_2_RollingCounter1 : 8|4@1+ (1,0) [0|15] ""  IDCM,ARC
 SG_ ACU_LongitudeAcceleration : 16|16@1+ (0.0002,-6) [-6|6] "g"  IDCM,ARC
 SG_ ACU_LongitudeAccelerationSensor_St : 48|1@1+ (1,0) [0|1] ""  IDCM,ARC
 SG_ ACU_2_Checksum2 : 64|8@1+ (1,0) [0|255] ""  IDCM,ARC
 SG_ ACU_2_RollingCounter2 : 72|4@1+ (1,0) [0|15] ""  IDCM,ARC
 SG_ ACU_LateralAcceleration : 80|16@1+ (0.0002,-6) [-6|6] "g"  IDCM,ARC
 SG_ ACU_LateralAccelerationSensor_St : 112|1@1+ (1,0) [0|1] ""  IDCM,ARC

BO_ 417 ESC_FD_2: 32 CGW
 SG_ ESC_FD2_Checksum3 : 96|8@1+ (1,0) [0|255] ""  IDCM
 SG_ ESC_FD2_RollingCounter3 : 104|4@1+ (1,0) [0|15] ""  IDCM
 SG_ ESC_Intervention : 108|1@1+ (1,0) [0|1] ""  IDCM
 SG_ ESC_ESCError : 109|1@1+ (1,0) [0|1] ""  IDCM
 SG_ ESC_TCSIntervention : 110|1@1+ (1,0) [0|1] ""  IDCM
 SG_ ESC_VDCIntervention : 112|1@1+ (1,0) [0|1] ""  IDCM
 SG_ ESC_ABSIntervention : 114|1@1+ (1,0) [0|1] ""  IDCM
 SG_ ESC_ABSError : 115|1@1+ (1,0) [0|1] ""  IDCM
 SG_ ESC_EBDIntervention : 116|1@1+ (1,0) [0|1] ""  IDCM
 SG_ ESC_EBDError : 117|1@1+ (1,0) [0|1] ""  IDCM
 SG_ ESC_FD2_Checksum4 : 120|8@1+ (1,0) [0|255] ""  IDCM
 SG_ ESC_FD2_RollingCounter4 : 128|4@1+ (1,0) [0|15] ""  IDCM
 SG_ ESC_BraBoostwarning : 132|2@1+ (1,0) [0|3] ""  IDCM
 SG_ ESC_VehicleStandstill_St : 136|1@1+ (1,0) [0|1] ""  IDCM
 SG_ ESC_VehicleStandstillSt_Valid : 137|1@1+ (1,0) [0|1] ""  IDCM
 SG_ ESC_AVHSt : 138|2@1+ (1,0) [0|3] ""  IDCM
 SG_ ESC_AVHAvailable : 140|1@1+ (1,0) [0|1] ""  IDCM
 SG_ ESC_HHCSt : 141|1@1+ (1,0) [0|1] ""  IDCM
 SG_ ESC_HHCAvailable : 142|1@1+ (1,0) [0|1] ""  IDCM
 SG_ ESC_HDCAvailable : 143|1@1+ (1,0) [0|1] ""  IDCM
 SG_ ESC_HDC_St : 144|2@1+ (1,0) [0|3] ""  IDCM
 SG_ ESC_HBB_St : 146|2@1+ (1,0) [0|3] ""  IDCM
 SG_ ESC_HBBActive : 148|1@1+ (1,0) [0|1] ""  IDCM
 SG_ ESC_CDP_St : 149|1@1+ (1,0) [0|1] ""  IDCM
 SG_ ESC_CDPAvailable : 150|1@1+ (1,0) [0|1] ""  IDCM
 SG_ ESC_CruiseControlShutDown : 151|1@1+ (1,0) [0|1] ""  IDCM
 SG_ ESC_PataLamp : 152|1@1+ (1,0) [0|1] ""  IDCM
 SG_ ESC_BrakeLight_Req : 153|1@1+ (1,0) [0|1] ""  IDCM
 SG_ ESC_EmergencyBrakeLight_Req : 154|1@1+ (1,0) [0|1] ""  IDCM
 SG_ ESC_EPB_St : 155|3@1+ (1,0) [0|7] ""  IDCM
 SG_ ESC_EPBFunctionLamp : 158|2@1+ (1,0) [0|3] ""  IDCM
 SG_ ESC_EPBFailLamp : 160|2@1+ (1,0) [0|3] ""  IDCM
 SG_ ESC_EPBWarnMessage : 162|2@1+ (1,0) [0|3] ""  IDCM
 SG_ ESC_EPBSwitch_St : 164|2@1+ (1,0) [0|3] ""  IDCM
 SG_ ESC_EPBTipInfo : 166|2@1+ (1,0) [0|3] ""  IDCM
 SG_ ESC_EPBError : 168|1@1+ (1,0) [0|1] ""  IDCM
 SG_ ESC_HBAActive : 169|1@1+ (1,0) [0|1] ""  IDCM
 SG_ ESC_HBAAvailable : 170|1@1+ (1,0) [0|1] ""  IDCM
 SG_ ESC_EPBSwitchSt_Valid : 171|1@1+ (1,0) [0|1] ""  IDCM
 SG_ ESC_BrakePedalApplied_OnlyForIV2 : 172|1@1+ (1,0) [0|1] ""  IDCM
 SG_ ESC_BrakePedalApplied_St_OnlyForIV2 : 173|2@1+ (1,0) [0|3] ""  IDCM
 SG_ ESC_AVH_DriverAbsentWarn : 175|1@1+ (1,0) [0|1] ""  IDCM
 SG_ ESC_FD2_Checksum5 : 176|8@1+ (1,0) [0|255] ""  IDCM,ARC,ARHUD,WHUD,VSP
 SG_ ESC_FD2_RollingCounter5 : 184|4@1+ (1,0) [0|15] ""  IDCM,ARC,ARHUD,WHUD,VSP
 SG_ ESC_VehicleSpeed : 192|13@1+ (0.05625,0) [0|300] "km/h"  IDCM,ARC,ARHUD,WHUD,VSP
 SG_ ESC_VehicleSpeed_Valid : 205|1@1+ (1,0) [0|1] ""  IDCM,ARC,ARHUD,WHUD,VSP

BO_ 199 ESC_FD_6: 32 CGW
 SG_ ESC_FD6_Checksum1 : 0|8@1+ (1,0) [0|255] ""  IDCM
 SG_ ESC_FD6_RollingCounter1 : 8|4@1+ (1,0) [0|15] ""  IDCM
 SG_ ESC_CampingMode_Rsp : 12|1@1+ (1,0) [0|1] ""  IDCM
 SG_ ESC_CampingModeWarning : 13|1@1+ (1,0) [0|1] ""  IDCM
 SG_ ESC_WorkMode : 16|4@1+ (1,0) [0|15] ""  IDCM
 SG_ ESC_ModeChangeEnable : 20|1@1+ (1,0) [0|1] ""  IDCM

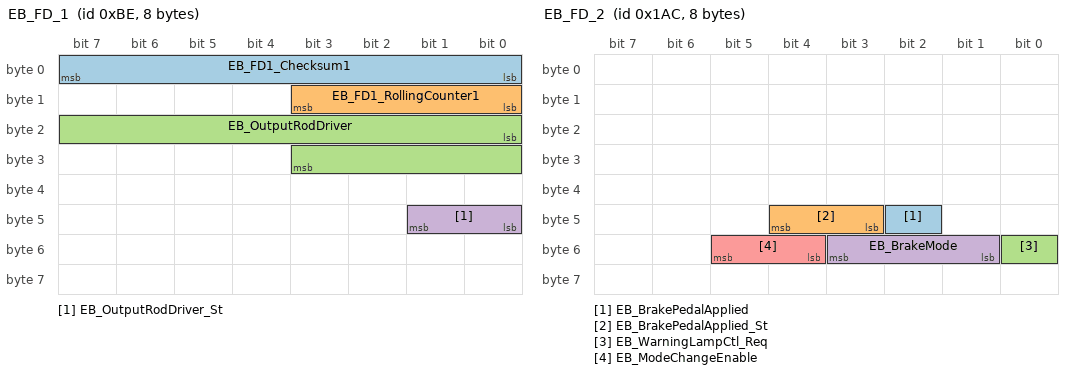
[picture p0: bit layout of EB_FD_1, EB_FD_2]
BO_ 190 EB_FD_1: 8 CGW
 SG_ EB_FD1_Checksum1 : 0|8@1+ (1,0) [0|255] ""  IDCM
 SG_ EB_FD1_RollingCounter1 : 8|4@1+ (1,0) [0|15] ""  IDCM
 SG_ EB_OutputRodDriver : 16|12@1+ (0.015625,-5) [-5|47] "mm"  IDCM,ARC
 SG_ EB_OutputRodDriver_St : 40|2@1+ (1,0) [0|3] ""  IDCM,ARC

BO_ 428 EB_FD_2: 8 CGW
 SG_ EB_BrakePedalApplied : 42|1@1+ (1,0) [0|1] ""  IDCM
 SG_ EB_BrakePedalApplied_St : 43|2@1+ (1,0) [0|3] ""  IDCM
 SG_ EB_WarningLampCtl_Req : 48|1@1+ (1,0) [0|1] ""  IDCM
 SG_ EB_BrakeMode : 49|3@1+ (1,0) [0|7] ""  IDCM
 SG_ EB_ModeChangeEnable : 52|2@1+ (1,0) [0|3] ""  IDCM

BO_ 429 EPS_FD_2: 32 CGW
 SG_ EPS_FD2_Checksum1 : 0|8@1+ (1,0) [0|255] ""  IDCM
 SG_ EPS_FD2_RollingCounter1 : 8|4@1+ (1,0) [0|15] ""  IDCM
 SG_ EPS_Failure_St : 22|2@1+ (1,0) [0|3] ""  IDCM
 SG_ EPS_WorkMode : 64|3@1+ (1,0) [0|7] ""  IDCM
 SG_ EPS_ModeChangeEnable : 67|1@1+ (1,0) [0|1] ""  IDCM
 SG_ EPS_HADError_RequestHADState : 72|1@1+ (1,0) [0|1] ""  IDCM
 SG_ EPS_HADError_RequestRackPosition : 73|1@1+ (1,0) [0|1] ""  IDCM
 SG_ EPS_HADError_ExternalMasterReq : 74|1@1+ (1,0) [0|1] ""  IDCM
 SG_ EPS_HADError_ECUState : 75|1@1+ (1,0) [0|1] ""  IDCM
 SG_ EPS_HADError_ErrorFlagFromRemoteECU : 76|1@1+ (1,0) [0|1] ""  IDCM
 SG_ EPS_HADError_HADStateMachineMonitorFault : 77|1@1+ (1,0) [0|1] ""  IDCM
 SG_ EPS_HADError_Reserved : 78|10@1+ (1,0) [0|0] ""  IDCM
 SG_ EPS_HADOff_RackPositionSync : 88|1@1+ (1,0) [0|1] ""  IDCM
 SG_ EPS_HADOff_VehicleSpeedLimitation : 89|1@1+ (1,0) [0|1] ""  IDCM
 SG_ EPS_HADOff_ErrorFromRemote : 90|1@1+ (1,0) [0|1] ""  IDCM
 SG_ EPS_HADOff_EmergencyTakeOver : 91|1@1+ (1,0) [0|1] ""  IDCM
 SG_ EPS_HADOff_SafetyDriver_TBT : 92|1@1+ (1,0) [0|1] ""  IDCM
 SG_ EPS_HADOff_SafetyDriver_RackSpeed : 93|1@1+ (1,0) [0|1] ""  IDCM
 SG_ EPS_HADOff_IPCStatus : 94|1@1+ (1,0) [0|1] ""  IDCM
 SG_ EPS_HADOff_StayInInitialState : 95|1@1+ (1,0) [0|1] ""  IDCM
 SG_ EPS_HADOff_TorqueReduction : 96|1@1+ (1,0) [0|1] ""  IDCM
 SG_ EPS_HADOff_WaterSensor : 97|1@1+ (1,0) [0|1] ""  IDCM
 SG_ EPS_HADOff_MinVehicleSpeed : 98|1@1+ (1,0) [0|1] ""  IDCM
 SG_ EPS_HADOff_GroundConnection : 99|1@1+ (1,0) [0|1] ""  IDCM
 SG_ EPS_HADOff_FunctionCoordinator : 100|1@1+ (1,0) [0|1] ""  IDCM
 SG_ EPS_HADOff_StickSlipWarning : 101|1@1+ (1,0) [0|1] ""  IDCM
 SG_ EPS_HADOff_TBTStatus : 102|1@1+ (1,0) [0|1] ""  IDCM
 SG_ EPS_HADOff_RPCTorqueValue : 103|1@1+ (1,0) [0|1] ""  IDCM
 SG_ EPS_HADOff_DoubleDiagnosisState : 104|1@1+ (1,0) [0|1] ""  IDCM
 SG_ EPS_HADOff_FADERMonitor : 105|1@1+ (1,0) [0|1] ""  IDCM
 SG_ EPS_HADOff_SupplyVoltageReduce : 106|1@1+ (1,0) [0|1] ""  IDCM
 SG_ EPS_HADOff_Reserved : 107|13@1+ (1,0) [0|0] ""  IDCM

BO_ 184 RWS_FD_1: 32 CGW
 SG_ RWS_FD1_Checksum1 : 0|8@1+ (1,0) [0|255] ""  IDCM
 SG_ RWS_FD1_RollingCounter1 : 8|4@1+ (1,0) [0|15] ""  IDCM
 SG_ RWS_Status : 12|2@1+ (1,0) [0|3] ""  IDCM
 SG_ RWS_Travel_valid : 14|1@1+ (1,0) [0|1] ""  IDCM
 SG_ RWS_Travel : 16|16@1+ (0.001,-23) [-23|23] "mm"  IDCM
 SG_ RWS_WarningLamp : 32|2@1+ (1,0) [0|3] ""  IDCM

BO_ 425 AIRS_FD_1: 32 CGW
 SG_ AIRS_FD1_Checksum1 : 0|8@1+ (1,0) [0|255] ""  IDCM
 SG_ AIRS_FD1_RollingCounter1 : 8|4@1+ (1,0) [0|15] ""  IDCM
 SG_ AIRS_WorkMode : 12|3@1+ (1,0) [0|7] ""  IDCM
 SG_ AIRS_ModeChangeEnable : 15|1@1+ (1,0) [0|1] ""  IDCM
 SG_ AIRS_CDCWorkMode : 16|3@1+ (1,0) [0|7] ""  IDCM
 SG_ AIRS_CDCModeChangeEnable : 19|1@1+ (1,0) [0|1] ""  IDCM
 SG_ AIRS_EasyloadModeIndicated : 20|1@1+ (1,0) [0|1] ""  IDCM
 SG_ AIRS_EasyloadAvailability : 21|1@1+ (1,0) [0|1] ""  IDCM
 SG_ AIRS_VehicleSpeedDependentLevelSwitchSt : 22|1@1+ (1,0) [0|1] ""  IDCM
 SG_ AIRS_VehicleSpeedDependentLevelSwitchAvaliability : 23|1@1+ (1,0) [0|1] ""  IDCM
 SG_ AIRS_LiftModeAvailability : 24|1@1+ (1,0) [0|1] ""  IDCM
 SG_ AIRS_LiftModeIndicated : 25|1@1+ (1,0) [0|1] ""  IDCM
 SG_ AIRS_LevelCalibrationComplete : 26|1@1+ (1,0) [0|1] ""  IDCM
 SG_ AIRS_ErrorLampRequest : 27|2@1+ (1,0) [0|3] ""  IDCM
 SG_ AIRS_DampingError : 29|1@1+ (1,0) [0|1] ""  IDCM
 SG_ AIRS_ErrorStatus : 30|1@1+ (1,0) [0|1] ""  IDCM
 SG_ AIRS_SystemTemporaryNotAvailable : 32|8@1+ (1,0) [0|255] ""  IDCM
 SG_ AIRS_ActionState : 40|8@1+ (1,0) [0|255] ""  IDCM
 SG_ AirS_OffRoadAvaliability : 48|1@1+ (1,0) [0|1] ""  IDCM
 SG_ AirS_OffRoadExitCommand : 49|1@1+ (1,0) [0|1] ""  IDCM
 SG_ AIRS_FD1_Checksum2 : 56|8@1+ (1,0) [0|255] ""  IDCM
 SG_ AIRS_FD1_RollingCounter2 : 64|4@1+ (1,0) [0|15] ""  IDCM
 SG_ AIRS_FD1_Checksum3 : 104|8@1+ (1,0) [0|255] ""  IDCM
 SG_ AIRS_FD1_RollingCounter3 : 112|4@1+ (1,0) [0|15] ""  IDCM
 SG_ AIRS_TargetHeightIndication : 117|3@1+ (1,0) [0|7] ""  IDCM
 SG_ AIRS_Height_FL : 120|8@1+ (1,-127) [-127|127] "mm"  IDCM,ARC
 SG_ AIRS_Height_FR : 128|8@1+ (1,-127) [-127|127] "mm"  IDCM,ARC
 SG_ AIRS_Height_RL : 136|8@1+ (1,-127) [-127|127] "mm"  IDCM,ARC
 SG_ AIRS_Height_RR : 144|8@1+ (1,-127) [-127|127] "mm"  IDCM,ARC

CM_ BO_ 763 "V2X信号";
CM_ BO_ 764 "V2X信号";
CM_ BO_ 765 "V2X信号";
CM_ BO_ 887 "Account ID";
CM_ BO_ 882 "XCALL ID";
CM_ BO_ 503 "LKS/ELKRCW/LCA/RCTA/AHB/ACC/ISA/FCS/FCTA/DOW功能";
CM_ BO_ 505 "Pilot功能状态及HWA拨杆变道功能状态";
CM_ BO_ 576 "跟踪目标类型及位置";
CM_ BO_ 578 "车道线类型及相关参数";
CM_ BO_ 580 "车道线类型及相关参数";
CM_ BO_ 582 "ADCM系统及传感器故障/标定/遮挡状态";
CM_ BO_ 405 "泊车提示/全景显示/PMAEB功能";
CM_ BO_ 584 "12区雷达距离信号";
CM_ BO_ 586 "车位角点坐标";
CM_ BO_ 588 "车位角点坐标";
CM_ BO_ 590 "车位角点坐标";
CM_ BO_ 596 "疲劳侦测/人脸识别/驾驶员头部位置";
CM_ BO_ 385 "ACU碰撞及安全带信号";
CM_ BO_ 386 "ACU六轴加速度信号";
CM_ BO_ 417 "扭矩控制、ESC子功能及车速信号";
CM_ BO_ 199 "驾驶模式及VMC扭矩接口";
CM_ BO_ 190 "EBtoESC_Information_10ms";
CM_ BO_ 428 "EBtoESC_Information_20ms";
CM_ BO_ 429 "APA转向扭矩信号及驾驶模式信号";
CM_ BO_ 184 "RWS状态信号";
CM_ BO_ 425 "Airs状态信号";
CM_ SG_ 763 TBOX_FD_8_Checksum1 "E2E Signal Group Checksum
Checksum is the actual value after calculation. See the 'ChecksumAlgorithm' sheet for the specific algorithm.
E2E信号组校验和
Checksum为计算后实际值，具体算法参见“ChecksumAlgorithm”页";
CM_ SG_ 763 TBOX_FD_8_RollingCounter1 "E2E Signal Group Counter
Counter value is automatically accumulated, added from 0 to 14 and then looped to the initial value of 0. Every time a message is sent, counter adds 1.
E2E信号组计数器
Counter值为自动累加，从0加到14，然后循环至初始值0，每次报文发送，Counter加1";
CM_ SG_ 763 TBOX_V2XOutofControl_Distance "V2X Out of Control Distance
V2X-车辆失控预警－距离";
CM_ SG_ 763 TBOX_V2XOutofControl_St "V2X Out of Control Status
V2X-车辆失控预警－状态";
CM_ SG_ 763 TBOX_V2XOutofControl_AlarmLevel "V2X Out of Control Alarm Level
V2X-车辆失控预警－告警等级";
CM_ SG_ 763 TBOX_V2XOutofControl_Angle "V2X Out of Control Angle
V2X-车辆失控预警－角度";
CM_ SG_ 763 TBOX_FD_8_Checksum2 "E2E Signal Group Checksum
Checksum is the actual value after calculation. See the 'ChecksumAlgorithm' sheet for the specific algorithm.
E2E信号组校验和
Checksum为计算后实际值，具体算法参见“ChecksumAlgorithm”页";
CM_ SG_ 763 TBOX_FD_8_RollingCounter2 "E2E Signal Group Counter
Counter value is automatically accumulated, added from 0 to 14 and then looped to the initial value of 0. Every time a message is sent, counter adds 1.
E2E信号组计数器
Counter值为自动累加，从0加到14，然后循环至初始值0，每次报文发送，Counter加1";
CM_ SG_ 763 TBOX_V2XBlindSpotorLaneChangeWarn_Type "V2X Blind Spot or Lane Change Warn Type
V2X-盲区/变道预警－类型";
CM_ SG_ 763 TBOX_V2XBlindSpotorLaneChangeWarn_St "V2X Blind Spot or Lane Change Warn Status
V2X-盲区/变道预警－状态";
CM_ SG_ 763 TBOX_V2XBlindSpotorLaneChangeWarn_AlarmLevel "V2X Blind Spot or Lane Change Warn Alarm Level
V2X-盲区/变道预警－告警等级";
CM_ SG_ 763 TBOX_V2XBlindSpotorLaneChangeWarn_Distance "V2X Blind Spot or Lane Change Warn Distance
V2X--盲区/变道预警－距离";
CM_ SG_ 763 TBOX_V2XBlindSpotorLaneChangeWarn_Direction "V2X Blind Spot or Lane Change Warn Direction
V2X-盲区/变道预警－方位";
CM_ SG_ 763 TBOX_FD_8_Checksum3 "E2E Signal Group Checksum
Checksum is the actual value after calculation. See the 'ChecksumAlgorithm' sheet for the specific algorithm.
E2E信号组校验和
Checksum为计算后实际值，具体算法参见“ChecksumAlgorithm”页";
CM_ SG_ 763 TBOX_FD_8_RollingCounter3 "E2E Signal Group Counter
Counter value is automatically accumulated, added from 0 to 14 and then looped to the initial value of 0. Every time a message is sent, counter adds 1.
E2E信号组计数器
Counter值为自动累加，从0加到14，然后循环至初始值0，每次报文发送，Counter加1";
CM_ SG_ 763 TBOX_V2XEmergencyVehicleWarn_Distance "V2X Emergency Vehicle Warn Distance
V2X-紧急车辆提醒－距离";
CM_ SG_ 763 TBOX_V2XEmergencyVehicleWarn_St "V2X Emergency Vehicle Warn Status
V2X-紧急车辆提醒－状态";
CM_ SG_ 763 TBOX_V2XEmergencyVehicleWarn_AlarmLevel "V2X Emergency Vehicle Warn Alarm Level
V2X-紧急车辆提醒－告警等级";
CM_ SG_ 763 TBOX_V2XEmergencyVehicleWarn_Type "V2X Emergency Vehicle Warn Type
V2X-紧急车辆提醒－紧急车辆类型";
CM_ SG_ 763 TBOX_V2XEmergencyVehicleWarn_Angle "V2X Emergency Vehicle Warn Angle
V2X-紧急车辆提醒－角度";
CM_ SG_ 764 TBOX_FD_9_Checksum1 "E2E Signal Group Checksum
Checksum is the actual value after calculation. See the 'ChecksumAlgorithm' sheet for the specific algorithm.
E2E信号组校验和
Checksum为计算后实际值，具体算法参见“ChecksumAlgorithm”页";
CM_ SG_ 764 TBOX_FD_9_RollingCounter1 "E2E Signal Group Counter
Counter value is automatically accumulated, added from 0 to 14 and then looped to the initial value of 0. Every time a message is sent, counter adds 1.
E2E信号组计数器
Counter值为自动累加，从0加到14，然后循环至初始值0，每次报文发送，Counter加1";
CM_ SG_ 764 TBOX_V2XVulnerableTrafficParticipantsWarn_Distance "V2X Vulnerable Traffic Participants Warn Distance
V2X-弱势交通参与者预警－距离";
CM_ SG_ 764 TBOX_V2XVulnerableTrafficParticipantsWarn_St "V2X Vulnerable Traffic Participants Warn Status
V2X-弱势交通参与者预警－状态";
CM_ SG_ 764 TBOX_V2XVulnerableTrafficParticipantsWarn_AlarmLevel "V2X Vulnerable Traffic Participants Warn Alarm Level
V2X-弱势交通参与者预警－告警等级";
CM_ SG_ 764 TBOX_V2XVulnerableTrafficParticipantsWarn_Participant "V2X Vulnerable Traffic Participants Warn Participant
V2X-弱势交通参与者预警－参与者";
CM_ SG_ 764 TBOX_V2XVulnerableTrafficParticipantsWarn_Angle "V2X Vulnerable Traffic Participants Warn Angle
V2X-弱势交通参与者预警－角度";
CM_ SG_ 764 TBOX_FD_9_Checksum2 "E2E Signal Group Checksum
Checksum is the actual value after calculation. See the 'ChecksumAlgorithm' sheet for the specific algorithm.
E2E信号组校验和
Checksum为计算后实际值，具体算法参见“ChecksumAlgorithm”页";
CM_ SG_ 764 TBOX_FD_9_RollingCounter2 "E2E Signal Group Counter
Counter value is automatically accumulated, added from 0 to 14 and then looped to the initial value of 0. Every time a message is sent, counter adds 1.
E2E信号组计数器
Counter值为自动累加，从0加到14，然后循环至初始值0，每次报文发送，Counter加1";
CM_ SG_ 764 TBOX_V2XInVehicleSignage_Direction "V2X In Vehicle Signage Direction
V2X-车内标牌－方位";
CM_ SG_ 764 TBOX_V2XInVehicleSignage_Type "V2X In Vehicle Signage Type
V2X-车内标牌－标牌类型";
CM_ SG_ 764 TBOX_V2XInVehicleSignage_Distance "V2X In Vehicle Signage Distance
V2X-车内标牌－距离";
CM_ SG_ 764 TBOX_V2XInVehicleSignage_St "V2X In Vehicle Signage Status
V2X-车内标牌－状态";
CM_ SG_ 764 TBOX_V2XInVehicleSignage_AlarmLevel "V2X In Vehicle Signage Alarm Level
V2X-车内标牌－告警等级";
CM_ SG_ 764 TBOX_V2XRoadHazardWarn_St "V2X Road Hazard Warn Status
V2X-道路危险状况提示－状态";
CM_ SG_ 764 TBOX_V2XRoadHazardWarn_AlarmLevel "V2X Road Hazard Warn Alarm Level
V2X-道路危险状况提示－告警等级";
CM_ SG_ 764 TBOX_V2XRoadHazardWarn_Distance "V2X Road Hazard Warn Distance
V2X-道路危险状况提示－距离";
CM_ SG_ 764 TBOX_V2XRoadHazardWarn_Direction "V2X Road Hazard Warn Direction
V2X-道路危险状况提示－方位";
CM_ SG_ 764 TBOX_V2XRoadHazardWarn_DangerTypes "V2X Road Hazard Warn Danger Types
V2X-道路危险状况提示－危险类型";
CM_ SG_ 764 TBOX_FD_9_Checksum3 "E2E Signal Group Checksum
Checksum is the actual value after calculation. See the 'ChecksumAlgorithm' sheet for the specific algorithm.
E2E信号组校验和
Checksum为计算后实际值，具体算法参见“ChecksumAlgorithm”页";
CM_ SG_ 764 TBOX_FD_9_RollingCounter3 "E2E Signal Group Counter
Counter value is automatically accumulated, added from 0 to 14 and then looped to the initial value of 0. Every time a message is sent, counter adds 1.
E2E信号组计数器
Counter值为自动累加，从0加到14，然后循环至初始值0，每次报文发送，Counter加1";
CM_ SG_ 764 TBOX_V2XGreenWaveSpeedGuidance_Distance "V2X Green Wave Speed Guidance Distance
V2X-绿波车速引导－距离";
CM_ SG_ 764 TBOX_V2XGreenWaveSpeedGuidance_Countdown "V2X Green Wave Speed Guidance Countdown
V2X-绿波车速引导－倒计时";
CM_ SG_ 764 TBOX_V2XGreenWaveSpeedGuidance_MinSpeed "V2X Green Wave Speed Guidance Min Speed
V2X-绿波车速引导－最小车速";
CM_ SG_ 764 TBOX_V2XGreenWaveSpeedGuidance_MaxSpeed "V2X Green Wave Speed Guidance Max Speed
V2X-绿波车速引导－最大车速";
CM_ SG_ 764 TBOX_V2XGreenWaveSpeedGuidance_TrafficLightPoint "V2X Green Wave Speed Guidance Traffic Light Point
V2X-绿波车速引导－信号灯指向";
CM_ SG_ 764 TBOX_V2XGreenWaveSpeedGuidance_TrafficLightSt "V2X Green Wave Speed Guidance Traffic Light Status
V2X-绿波车速引导－信号灯状态";
CM_ SG_ 764 TBOX_V2XGreenWaveSpeedGuidance_St "V2X Green Wave Speed Guidance Status
V2X-绿波车速引导－状态";
CM_ SG_ 765 TBOX_FD_10_Checksum1 "E2E Signal Group Checksum
Checksum is the actual value after calculation. See the 'ChecksumAlgorithm' sheet for the specific algorithm.
E2E信号组校验和
Checksum为计算后实际值，具体算法参见“ChecksumAlgorithm”页";
CM_ SG_ 765 TBOX_FD_10_RollingCounter1 "E2E Signal Group Counter
Counter value is automatically accumulated, added from 0 to 14 and then looped to the initial value of 0. Every time a message is sent, counter adds 1.
E2E信号组计数器
Counter值为自动累加，从0加到14，然后循环至初始值0，每次报文发送，Counter加1";
CM_ SG_ 765 TBOX_V2XRealtimeTrafficInformation_St "V2X Realtime Traffic Information Status
V2X-前方道路实时交通信息－状态";
CM_ SG_ 765 TBOX_V2XRealtimeTrafficInformation_Direction "V2X Realtime Traffic Information Direction
V2X-前方道路实时交通信息－方位";
CM_ SG_ 765 TBOX_V2XRealtimeTrafficInformation_AlarmLevel "V2X Realtime Traffic Information Alarm Level
V2X-前方道路实时交通信息－告警等级";
CM_ SG_ 765 TBOX_V2XRealtimeTrafficInformation_Distance "V2X Realtime Traffic Information Distance
V2X-前方道路实时交通信息－距离";
CM_ SG_ 765 TBOX_V2XRealtimeTrafficInformation_Type "V2X Realtime Traffic Information Type
V2X-前方道路实时交通信息－信息类型";
CM_ SG_ 765 TBOX_V2XRealtimeTrafficInformation_Severity "V2X Realtime Traffic Information Severity
V2X-前方道路实时交通信息－严重程度";
CM_ SG_ 765 TBOX_V2XRushRedLightWarn_Distance "V2X Rush Red Light Warn Distance
V2X-闯红灯预警－距离";
CM_ SG_ 765 TBOX_V2XRushRedLightWarn_St "V2X Rush Red Light Warn Status
V2X-闯红灯预警－状态";
CM_ SG_ 765 TBOX_V2XRushRedLightWarn_AlarmLevel "V2X Rush Red Light Warn Alarm Level
V2X-闯红灯预警－告警等级";
CM_ SG_ 765 TBOX_V2XSpeedLimitWarn_St "V2X Speed Limit Warn Status
V2X-限速预警－状态";
CM_ SG_ 765 TBOX_V2XSpeedLimitWarn_AlarmLevel "V2X Speed Limit Warn Alarm Level
V2X-限速预警－告警等级";
CM_ SG_ 765 TBOX_V2XSpeedLimitWarn_Speed "V2X Speed Limit Warn Alarm Speed
V2X-限速预警－车速";
CM_ SG_ 765 TBOX_FD_10_Checksum2 "E2E Signal Group Checksum
Checksum is the actual value after calculation. See the 'ChecksumAlgorithm' sheet for the specific algorithm.
E2E信号组校验和
Checksum为计算后实际值，具体算法参见“ChecksumAlgorithm”页";
CM_ SG_ 765 TBOX_FD_10_RollingCounter2 "E2E Signal Group Counter
Counter value is automatically accumulated, added from 0 to 14 and then looped to the initial value of 0. Every time a message is sent, counter adds 1.
E2E信号组计数器
Counter值为自动累加，从0加到14，然后循环至初始值0，每次报文发送，Counter加1";
CM_ SG_ 765 TBOX_V2X_St "TBOX V2X Status
V2X功能状态信号";
CM_ SG_ 887 TBOX_AccountIDByte1 "Account ID - Byte1
账户ID - Byte1";
CM_ SG_ 887 TBOX_AccountIDByte2 "Account ID - Byte2
账户ID - Byte2";
CM_ SG_ 887 TBOX_AccountIDByte3 "Account ID - Byte3
账户ID - Byte3";
CM_ SG_ 887 TBOX_AccountIDByte4 "Account ID - Byte4
账户ID - Byte4";
CM_ SG_ 887 TBOX_AccountIDByte5 "Account ID - Byte5
账户ID - Byte5";
CM_ SG_ 887 TBOX_AccountIDByte6 "Account ID - Byte6
账户ID - Byte6";
CM_ SG_ 887 TBOX_AccountIDByte7 "Account ID - Byte7
账户ID - Byte7";
CM_ SG_ 887 TBOX_AccountIDByte8 "Account ID - Byte8
账户ID - Byte8";
CM_ SG_ 887 TBOX_AccountIDByte9 "Account ID - Byte9
账户ID - Byte9";
CM_ SG_ 887 TBOX_AccountIDByte10 "Account ID - Byte10
账户ID - Byte10";
CM_ SG_ 887 TBOX_AccountIDByte11 "Account ID - Byte11
账户ID - Byte11";
CM_ SG_ 887 TBOX_AccountIDByte12 "Account ID - Byte12
账户ID - Byte12";
CM_ SG_ 887 TBOX_AccountIDByte13 "Account ID - Byte13
账户ID - Byte13";
CM_ SG_ 887 TBOX_AccountIDByte14 "Account ID - Byte14
账户ID - Byte14";
CM_ SG_ 887 TBOX_AccountIDByte15 "Account ID - Byte15
账户ID - Byte15";
CM_ SG_ 887 TBOX_AccountIDByte16 "Account ID - Byte16
账户ID - Byte16";
CM_ SG_ 887 TBOX_AccountIDByte17 "Account ID - Byte17
账户ID - Byte17";
CM_ SG_ 887 TBOX_AccountIDByte18 "Account ID - Byte18
账户ID - Byte18";
CM_ SG_ 887 TBOX_AccountIDByte19 "Account ID - Byte19
账户ID - Byte19";
CM_ SG_ 887 TBOX_AccountIDByte20 "Account ID - Byte20
账户ID - Byte20";
CM_ SG_ 887 TBOX_AccountIDByte21 "Account ID - Byte21
账户ID - Byte21";
CM_ SG_ 887 TBOX_AccountIDByte22 "Account ID - Byte22
账户ID - Byte22";
CM_ SG_ 887 TBOX_AccountIDByte23 "Account ID - Byte23
账户ID - Byte23";
CM_ SG_ 887 TBOX_AccountIDByte24 "Account ID - Byte24
账户ID - Byte24";
CM_ SG_ 887 TBOX_AccountIDByte25 "Account ID - Byte25
账户ID - Byte25";
CM_ SG_ 887 TBOX_AccountIDByte26 "Account ID - Byte26
账户ID - Byte26";
CM_ SG_ 887 TBOX_AccountIDByte27 "Account ID - Byte27
账户ID - Byte27";
CM_ SG_ 887 TBOX_AccountIDByte28 "Account ID - Byte28
账户ID - Byte28";
CM_ SG_ 887 TBOX_AccountIDByte29 "Account ID - Byte29
账户ID - Byte29";
CM_ SG_ 887 TBOX_AccountIDByte30 "Account ID - Byte30
账户ID - Byte30";
CM_ SG_ 887 TBOX_AccountIDByte31 "Account ID - Byte31
账户ID - Byte31";
CM_ SG_ 887 TBOX_AccountIDByte32 "Account ID - Byte32
账户ID - Byte32";
CM_ SG_ 882 TBOX_XCALLIDByte0 "XCALL ID-Byte0
XCALL ID - 字节0";
CM_ SG_ 882 TBOX_XCALLIDByte1 "XCALL ID-Byte1
XCALL ID - 字节1";
CM_ SG_ 882 TBOX_XCALLIDByte2 "XCALL ID-Byte2
XCALL ID - 字节2";
CM_ SG_ 882 TBOX_XCALLIDByte3 "XCALL ID-Byte3
XCALL ID - 字节3";
CM_ SG_ 882 TBOX_XCALLIDByte4 "XCALL ID-Byte4
XCALL ID - 字节4";
CM_ SG_ 882 TBOX_XCALLIDByte5 "XCALL ID-Byte5
XCALL ID - 字节5";
CM_ SG_ 882 TBOX_XCALLIDByte6 "XCALL ID-Byte6
XCALL ID - 字节6";
CM_ SG_ 882 TBOX_XCALLIDByte7 "XCALL ID-Byte7
XCALL ID - 字节7";
CM_ SG_ 882 TBOX_XCALLIDByte8 "XCALL ID-Byte8
XCALL ID - 字节8";
CM_ SG_ 882 TBOX_XCALLIDByte9 "XCALL ID-Byte9
XCALL ID - 字节9";
CM_ SG_ 503 ADCM_FD2_Checksum1 "E2E Signal Group Checksum
Checksum is the actual value after calculation. See the 'ChecksumAlgorithm' sheet for the specific algorithm.
E2E信号组校验和Checksum为计算后实际值，具体算法参见“ChecksumAlgorithm”页";
CM_ SG_ 503 ADCM_FD2_RollingCounter1 "E2E Signal Group Counter
Counter value is automatically accumulated, added from 0 to 14 and then looped to the initial value of 0. Every time a message is sent, counter adds 1.
E2E信号组计数器Counter值为自动累加，从0加到14，然后循环至初始值0，每次报文发送，Counter加1";
CM_ SG_ 503 ADCM_LKS_TakeoverReq "Take over request to driver
驾驶员接管报警请求";
CM_ SG_ 503 ADCM_LKS_St "LKS（LDW and LKA） status
LKS(车道偏离预警和车道保持辅助)状态
LDW(Lane Departure Warning )
LKS(Lane Keeping Assist)";
CM_ SG_ 503 ADCM_LKS_Type_Set "LKS operate mode set feedback
LKS操作模式反馈";
CM_ SG_ 503 ADCM_LKS_Left_Active_St "LKS Left Active Status 
LKS左侧激活报警干预状态";
CM_ SG_ 503 ADCM_LKS_Right_Active_St "LKS Right Active Status 
LKS右侧激活报警干预状态";
CM_ SG_ 503 ADCM_LKS_Sensitivity_Set "LKS Sensitivity set feedback
LKS(LDW and LKA)敏感度反馈";
CM_ SG_ 503 ADCM_ELK_St "ELK (Emergency Lane Keeping )feature status
ELK(紧急车道保持)功能状态";
CM_ SG_ 503 ADCM_ELK_Left_Active_St "ELK Left Active Status 
ELK左侧报警干预状态";
CM_ SG_ 503 ADCM_ELK_Right_Active_St "ELK Right Active Status 
ELK右侧报警干预状态";
CM_ SG_ 503 ADCM_RCW_St "RCW(rear collision warning ) feature status
RCW（后碰撞预警）功能状态";
CM_ SG_ 503 ADCM_RCW_Warn_St "RCW warning  level
RCW报警等级";
CM_ SG_ 503 ADCM_LCA_St "LCA (Lane Change Assist) Function status
LCA (变道辅助) 功能状态";
CM_ SG_ 503 ADCM_LCA_Right_Warn_St "LCA right warning level
LCA右侧报警等级";
CM_ SG_ 503 ADCM_LCA_Left_Warn_St "LCA left warning level
LCA左侧报警等级";
CM_ SG_ 503 ADCM_RCTA_St "RCTA(Rear Crossing Traffic Assist) Function status
RCTA（倒车横向辅助）功能状态";
CM_ SG_ 503 ADCM_RCTA_Right_Warn_St "RCTA right warning Level
RCTA右侧报警等级";
CM_ SG_ 503 ADCM_RCTA_Left_Warn_St "RCTA left warning Level
RCTA左侧报警等级";
CM_ SG_ 503 ADCM_AHB_St "AHB (Automatic High Beam) status
AHB (自动远近光灯切换) 功能状态";
CM_ SG_ 503 ADCM_AHB_Ctrl_St "AHB Control status
AHB控制状态";
CM_ SG_ 503 ADCM_FD2_Checksum2 "E2E Signal Group Checksum
Checksum is the actual value after calculation. See the 'ChecksumAlgorithm' sheet for the specific algorithm.
E2E信号组校验和Checksum为计算后实际值，具体算法参见“ChecksumAlgorithm”页";
CM_ SG_ 503 ADCM_FD2_RollingCounter2 "E2E Signal Group Counter
Counter value is automatically accumulated, added from 0 to 14 and then looped to the initial value of 0. Every time a message is sent, counter adds 1.
E2E信号组计数器Counter值为自动累加，从0加到14，然后循环至初始值0，每次报文发送，Counter加1";
CM_ SG_ 503 ADCM_ACC_UnavailableReason "ACC unavailable reason for driver
ACC不可用原因";
CM_ SG_ 503 ADCM_ACC_St "This signal indicates ACC(Adaptive cruise control )status
ACC （自适应巡航）状态信号";
CM_ SG_ 503 ADCM_ACC_Warn_St "ACC Warning Status
ACC报警状态";
CM_ SG_ 503 ADCM_ACC_TimeGap "ACC function set timeGap.
ACC功能设定跟车时距";
CM_ SG_ 503 ADCM_ACC_TargetSpeed "ACC target set speed
ACC功能设定车速";
CM_ SG_ 503 ADCM_ACC_GoNotifier "ACC stop to go notifier
ACC起步提醒";
CM_ SG_ 503 ADCM_ISA_St "ISA (Intelligent Speed Alert) function status
ISA (智能限速提醒) 功能状态";
CM_ SG_ 503 ADCM_ISA_LimitSpeed "ISA limit speed
ISA限制车速";
CM_ SG_ 503 ADCM_ISA_Operating_St "Operation status of traffic sign functions
交通标识功能的模式状态";
CM_ SG_ 503 ADCM_ISA_Warn_St "ISA warning status
ISA报警状态";
CM_ SG_ 503 ADCM_ISA_SpeedLimitype "ISA specific speed limit type
ISA限速类型";
CM_ SG_ 503 ADCM_ISA_SpeedLimitUnit "ISA(intelligent speed assist) speed limit unit
ISA限速单位";
CM_ SG_ 503 ADCM_ISA_WarningOffset_Set "ISA warning offset set feedback
ISA报警偏差值反馈";
CM_ SG_ 503 ADCM_ValetMode_AccDisable_St "Valet Mode disable ACC status
代驾模式禁用ACC状态信号";
CM_ SG_ 503 ADCM_FD2_Checksum3 "E2E Signal Group Checksum
Checksum is the actual value after calculation. See the 'ChecksumAlgorithm' sheet for the specific algorithm.
E2E信号组校验和Checksum为计算后实际值，具体算法参见“ChecksumAlgorithm”页";
CM_ SG_ 503 ADCM_FD2_RollingCounter3 "E2E Signal Group Counter
Counter value is automatically accumulated, added from 0 to 14 and then looped to the initial value of 0. Every time a message is sent, counter adds 1.
E2E信号组计数器Counter值为自动累加，从0加到14，然后循环至初始值0，每次报文发送，Counter加1";
CM_ SG_ 503 ADCM_FCS_TargetType "FCS（FCW and AEB）warning target type（CIPV_MPC）
FCS报警目标类型
(最可能碰撞的车和最可能碰撞的人)";
CM_ SG_ 503 ADCM_FCS_St "FCS（FCW and AEB）function status
FCS (前碰撞预警和主动紧急制动)功能状态
FCW(Forward Collision Warning)
AEB(Automatic Emergency Braking)";
CM_ SG_ 503 ADCM_FCS_Active_St "FCS（FCW and AEB） Active Braking Status 
FCS激活报警制动状态";
CM_ SG_ 503 ADCM_FCTA_Left_TargetType "FCTA Left warning target type（CIPV_MPC）
FCTA左侧报警目标类型";
CM_ SG_ 503 ADCM_FCTA_Right_TargetType "FCTA Right warning target type（CIPV_MPC）
FCTA右侧报警目标类型";
CM_ SG_ 503 ADCM_FCTA_Left_Active_St "FCTA Left Active Braking Status 
FCTA左侧激活报警制动状态";
CM_ SG_ 503 ADCM_FCTA_Right_Active_St "FCTA Right Active Braking Status 
FCTA右侧激活报警制动状态";
CM_ SG_ 503 ADCM_FCTA_St "FCTA (Front Crossing Traffic Assist)  function status
FCTA (前向目标横穿辅助）功能状态";
CM_ SG_ 503 ADCM_DetecCloseObjectFunctionRsp "Dectec Closing Object Function Response
探测接近车辆四角物体报警功能反馈";
CM_ SG_ 503 ADCM_DOW_St "DOW (Door Open Warning) Function status
开门预警功能状态";
CM_ SG_ 503 ADCM_DOW_FL_Warn_St "Front Left door warning status
左前门开门报警状态";
CM_ SG_ 503 ADCM_DOW_RL_Warn_St "Rear Left door warning status
左后门开门报警状态";
CM_ SG_ 503 ADCM_DOW_FR_Warn_St "Front right door warning status
右前门开门报警状态";
CM_ SG_ 503 ADCM_DOW_RR_Warn_St "Rear right door warning status
右后门开门报警状态";
CM_ SG_ 503 ADCM_FRCloseObjectWarn "FrontRight Close Object Warning
右前方靠近目标报警";
CM_ SG_ 503 ADCM_RLCloseObjectWarn "RearLeft Close Object Warning
左后方靠近目标报警";
CM_ SG_ 503 ADCM_RRCloseObjectWarn "RearRight Close Object Warning
右后方靠近目标报警";
CM_ SG_ 503 ADCM_FLCloseObjectWarn "FrontLeft Close Object Warning
左前方靠近目标报警";
CM_ SG_ 505 ADCM_FD3_Checksum1 "E2E Signal Group Checksum
Checksum is the actual value after calculation. See the 'ChecksumAlgorithm' sheet for the specific algorithm.
E2E信号组校验和Checksum为计算后实际值，具体算法参见“ChecksumAlgorithm”页";
CM_ SG_ 505 ADCM_FD3_RollingCounter1 "E2E Signal Group Counter
Counter value is automatically accumulated, added from 0 to 14 and then looped to the initial value of 0. Every time a message is sent, counter adds 1.
E2E信号组计数器Counter值为自动累加，从0加到14，然后循环至初始值0，每次报文发送，Counter加1";
CM_ SG_ 505 ADCM_Pilot_Warn_St "Pilot warning status
Pilot功能报警状态";
CM_ SG_ 505 ADCM_Pilot_Type "Pilot Type
Pilot功能类型";
CM_ SG_ 505 ADCM_Pilot_Available_St "Pilot Available status
Pilot功能可用状态";
CM_ SG_ 505 ADCM_PilotLateral_St "Pilot Lateral function status
Pilot功能横向功能状态";
CM_ SG_ 505 ADCM_FD3_Checksum2 "E2E Signal Group Checksum
Checksum is the actual value after calculation. See the 'ChecksumAlgorithm' sheet for the specific algorithm.
E2E信号组校验和Checksum为计算后实际值，具体算法参见“ChecksumAlgorithm”页";
CM_ SG_ 505 ADCM_FD3_RollingCounter2 "E2E Signal Group Counter
Counter value is automatically accumulated, added from 0 to 14 and then looped to the initial value of 0. Every time a message is sent, counter adds 1.
E2E信号组计数器Counter值为自动累加，从0加到14，然后循环至初始值0，每次报文发送，Counter加1";
CM_ SG_ 505 ADCM_HWA_ILC_Left_St "HWA indication lane change left side status
HWA拨杆变道左侧状态";
CM_ SG_ 505 ADCM_HWA_ILC_Right_St "HWA indication lane change right side status
HWA拨杆变道右侧状态";
CM_ SG_ 505 ADCM_HWA_ILC_Set "HWA indicator lane change on/off status
HWA表明拨杆变道开关状态";
CM_ SG_ 505 ADCM_HWA_ILC_TurnLampReq "HWA  indication lane change turn lamp request
HWA拨杆变道转向灯点亮请求";
CM_ SG_ 505 ADCM_HWA_ILC_AbortReason "HWA  indication lane change abort reason
HWA拨杆变道退出原因";
CM_ SG_ 505 ADCM_HWA_ILC_Left_Warn "HWA indication lane change left side warning status
HWA拨杆变道左侧报警状态";
CM_ SG_ 505 ADCM_HWA_ILC_Right_Warn "HWA  indication lane change right side warning status
HWA拨杆变道右侧报警状态";
CM_ SG_ 505 ADCM_HWA_ILC_HandsonReq "HWA indicator lane change hands on request
HWA拨杆变道手握方向盘请求";
CM_ SG_ 576 ADCM_ACC_TrackTarget0_LateralPosition "Track Target 0（Closest Same Lane）Lateral Position
Positive value means target is on the left
跟踪目标0（自车道前方最近）横向位置，正值表示目标在左侧";
CM_ SG_ 576 ADCM_ACC_TrackTarget0_ObjectType "Track Target 0（Closest Same Lane）Object type
跟踪目标0（自车道前方最近）目标类型";
CM_ SG_ 576 ADCM_ACC_TrackTarget0_St "Track Target 0（Closest Same Lane）detection state
跟踪目标0（自车道前方最近）探测状态";
CM_ SG_ 576 ADCM_ACC_TrackTarget0_LongitudinalPosition "Track Target 0（Closest Same Lane）Longitudinal Position
跟踪目标0（自车道前方最近）纵向位置";
CM_ SG_ 576 ADCM_ACC_TrackTarget1_LateralPosition "Track Target 1（Before Tarcet 0, The Second Closest Same Lane） Lateral Position
Positive value means target is on the left
跟踪目标1（目标0前面，自车前方第二近）横向位置，正值表示目标在左侧";
CM_ SG_ 576 ADCM_ACC_TrackTarget1_ObjectType "Track Target 1（Before Tarcet 0, The Second Closest Same Lane）Object Type
跟踪目标1（目标0前面，自车前方第二近）目标类型";
CM_ SG_ 576 ADCM_ACC_TrackTarget1_St "Track Target 1（Before Tarcet 0, The Second Closest Same Lane）detection state
跟踪目标1（目标0前面，自车前方第二近）探测状态";
CM_ SG_ 576 ADCM_ACC_TrackTarget1_LongitudinalPosition "Track Target 1（Before Tarcet 0, The Second Closest Same Lane） Longitudinal Position
跟踪目标1（目标0前面，自车前方第二近）纵向位置";
CM_ SG_ 576 ADCM_ACC_TrackTarget2_LateralPosition "Track Target 2（Closest Left Lane）Lateral Position
Positive value means target is on the left
跟踪目标2（左侧车道前方最近）横向位置，正值表示目标在左侧";
CM_ SG_ 576 ADCM_ACC_TrackTarget2_ObjectType "Track Target 2（Closest Left Lane）Object class
跟踪目标2（左侧车道前方最近）目标类型";
CM_ SG_ 576 ADCM_ACC_TrackTarget2_St "Track Target 2（Closest Left Lane）detection state
跟踪目标2（左侧车道前方最近）探测状态";
CM_ SG_ 576 ADCM_ACC_TrackTarget2_LongitudinalPosition "Track Target 2（Closest Left Lane）Longitudinal Position
跟踪目标2（左侧车道前方最近）纵向位置";
CM_ SG_ 576 ADCM_ACC_TrackTarget3_LateralPosition "Track Target 3（Closest Right Lane）Lateral Position
Positive value means target is on the left
跟踪目标3（右侧车道前方最近）横向位置，正值表示目标在左侧";
CM_ SG_ 576 ADCM_ACC_TrackTarget3_ObjectType "Track Target 3（Closest Right Lane）Object Type
跟踪目标3（右侧车道前方最近）目标类型";
CM_ SG_ 576 ADCM_ACC_TrackTarget3_St "Track Target 3（Closest Right Lane）detection state
跟踪目标3（右侧车道前方最近）探测状态";
CM_ SG_ 576 ADCM_ACC_TrackTarget3_LongitudinalPosition "Track Target 3（Closest Right Lane）Longitudinal Position
跟踪目标3（右侧车道前方最近）纵向位置";
CM_ SG_ 578 ADCM_Line_1_Display "Display state of the left lane marking
自车道左侧车道线显示状态";
CM_ SG_ 578 ADCM_Line_1_Type "Left side of lane marking indication type
自车道左侧车道线类型";
CM_ SG_ 578 ADCM_Line_1_A0 "Left Lane Marking Polynomial Coefficient A0, which stands for the lateral distance between lane marking and the middle of the eog vehicle.
Positive value means lane marking on the left side of the ego vehicle.
自车道左侧车道线多项式系数A0, 表示自车中心到车道线的横向距离，正值表示车道线在左边。";
CM_ SG_ 578 ADCM_Line_1_A1 "Left Lane Marking Polynomial Coefficient A1, which stands for the heading angle between the lane marking and the ego vehicle.
Positive value means counter clockwise
自车道左侧车道线多项式系数A1, 表示自车相对车道线的航向角，正值表示车道线逆时针。";
CM_ SG_ 578 ADCM_Line_1_A2 "Left Lane Marking Polynomial Coefficient A2, which stands for the curvature of the lane marking.
Positive value means left bending
自车道左侧车道线多项式系数A2, 表示车道线曲率，正值表示车道线向左弯曲。";
CM_ SG_ 578 ADCM_Line_1_A3 "Left Lane Marking Polynomial Coefficient A3, which stands for the curvature rate of the lane marking.
Positive value means left bending rate
自车道左侧车道线多项式系数A3, 表示车道线曲率变化率，正值表示车道线向左弯曲。";
CM_ SG_ 578 ADCM_Line_2_Display "Display state of the right lane marking
自车道右侧车道线显示状态";
CM_ SG_ 578 ADCM_Line_2_Type "Right side of lane marking indication type
自车道右侧车道线类型";
CM_ SG_ 578 ADCM_Line_2_A0 "Right Lane Marking Polynomial Coefficient A0, which stands for the lateral distance between the lane marking and the middle of the eog vehicle.
Positive value means lane marking on the left side of the ego vehicle.
自车道右侧车道线多项式系数A0, 表示自车中心到车道线的横向距离，正值表示车道线在左边。";
CM_ SG_ 578 ADCM_Line_2_A1 "Right Lane Marking Polynomial Coefficient A1, which stands for the heading angle between the lane marking and the ego vehicle.
Positive value means counter clockwise
自车道右侧车道线多项式系数A1, 表示自车相对车道线的航向角，正值表示车道线逆时针。";
CM_ SG_ 578 ADCM_Line_2_A2 "Right Lane Marking Polynomial Coefficient A2, which stands for the curvature of the lane marking.
Positive value means left bending
自车道右侧车道线多项式系数A2, 表示车道线曲率，正值表示车道线向左弯曲。";
CM_ SG_ 578 ADCM_FD5_Reserved8 "Reserved for future extensions
信号扩展预留位";
CM_ SG_ 578 ADCM_Line_2_A3 "Right Lane Marking Polynomial Coefficient A3, which stands for the curvature rate of the lane marking.
Positive value means right bending rate
自车道右侧车道线多项式系数A3, 表示车道线曲率变化率，正值表示车道线向左弯曲。";
CM_ SG_ 580 ADCM_Line_3_Display "Display state of Left adjacent Lane's Left Lane Marking
相邻左车道左侧车道线显示状态";
CM_ SG_ 580 ADCM_Line_3_Type "Adj Left side of lane marking indication type
相邻左车道左侧车道线类型";
CM_ SG_ 580 ADCM_Line_3_A0 "AdjLeft Lane Marking Polynomial Coefficient A0, which stands for the lateral distance between the lane marking and the middle of the eog vehicle.
Positive value means lane marking on the left side of the ego vehicle.
相邻左车道左侧车道线多项式系数A0, 表示自车中心到车道线的横向距离，正值表示车道线在左边。";
CM_ SG_ 580 ADCM_Line_3_A1 "AdjLeft Lane Marking Polynomial Coefficient A1, which stands for the heading angle between the lane
marking and the ego vehicle.
Positive value means counter clockwise
相邻左车道左侧车道线多项式系数A1, 表示自车相对车道线的航向角，正值表示车道线逆时针。";
CM_ SG_ 580 ADCM_Line_3_A2 "AdjLeft Lane Marking Polynomial Coefficient A2, which stands for the curvature of the lane marking.
Positive value means left bending
相邻左车道左侧车道线多项式系数A2, 表示车道线曲率，正值表示车道线向左弯曲。";
CM_ SG_ 580 ADCM_Line_3_A3 "AdjLeft Lane Marking Polynomial Coefficient A3, which stands for the curvature rate of the lane marking.
Positive value means adjleft bending rate
相邻左车道左侧车道线多项式系数A3, 表示车道线曲率变化率，正值表示车道线向左弯曲。";
CM_ SG_ 580 ADCM_Line_4_Display "Display state of Right adjacent Lane's Right Lane Marking
相邻右车道右侧车道线显示状态";
CM_ SG_ 580 ADCM_Line_4_Type "Adj Right side of lane marking indication type
相邻右车道右侧车道线类型";
CM_ SG_ 580 ADCM_Line_4_A0 "AdjRight Lane Marking Polynomial Coefficient A0, which stands for the lateral distance between the lane marking and the middle of the eog vehicle.
Positive value means lane marking on the left side of the ego vehicle.
相邻右车道右侧车道线多项式系数A0, 表示自车中心到车道线的横向距离，正值表示车道线在左边。";
CM_ SG_ 580 ADCM_Line_4_A1 "AdjRight Lane Marking Polynomial Coefficient A1, which stands for the heading angle between the lane
marking and the ego vehicle.
Positive value means counter clockwise
相邻右车道右侧车道线多项式系数A1, 表示自车相对车道线的航向角，正值表示车道线逆时针。";
CM_ SG_ 580 ADCM_Line_4_A2 "AdjRight Lane Marking Polynomial Coefficient A2, which stands for the curvature of the lane marking.
Positive value means left bending
相邻右车道右侧车道线多项式系数A2, 表示车道线曲率，正值表示车道线向左弯曲。";
CM_ SG_ 580 ADCM_Line_4_A3 "AdjRight Lane Marking Polynomial
Coefficient A3, which stands for the curvature rate of the lane marking.
Positive value means Adjright bending rate
相邻右车道右侧车道线多项式系数A3, 表示车道线曲率变化率，正值表示车道线向左弯曲。";
CM_ SG_ 582 ADCM_SystemSt "ADCM System Status
ADCM系统状态";
CM_ SG_ 582 ADCM_FMRRSensorBloc_St "Front MRR Blocked Status
前方毫米波雷达遮挡状态";
CM_ SG_ 582 ADCM_FCamSensorBloc_St "Front Camera 1 Blocked Status
前方摄像头遮挡状态";
CM_ SG_ 582 ADCM_ReserveSensorBloc_St "Reserved Sensor Blocked Status
预留传感器遮挡状态";
CM_ SG_ 582 ADCM_LFSRRSensorBloc_St "LeftFront SRR Blocked Status
左前毫米波雷达遮挡状态";
CM_ SG_ 582 ADCM_LRSRRSensorBloc_St "LeftRear SRR Blocked Status
左后毫米波雷达遮挡状态";
CM_ SG_ 582 ADCM_RRSRRSensorBloc_St "RightRear SRR Blocked Status
右后毫米波雷达遮挡状态";
CM_ SG_ 582 ADCM_RFSRRSensorBloc_St "RightFront SRR Blocked Status
右前毫米波雷达遮挡状态";
CM_ SG_ 582 ADCM_FMRRSensorCali_St "Front MRR Calibration Status
前方毫米波雷达标定状态";
CM_ SG_ 582 ADCM_FCamSensorCali_St "Front Camera 1 Calibration Status
前方摄像头标定状态";
CM_ SG_ 582 ADCM_ReserveSensorCali_St "Reserved Sensor Calibration Status
预留传感器标定状态";
CM_ SG_ 582 ADCM_LFSRRSensorCali_St "LeftFront SRR Calibration Status
左前毫米波雷达标定状态";
CM_ SG_ 582 ADCM_LRSRRSensorCali_St "LeftRear SRR Calibration Status
左后毫米波雷达标定状态";
CM_ SG_ 582 ADCM_RRSRRSensorCali_St "RightRear SRR Calibration Status
右后毫米波雷达标定状态";
CM_ SG_ 582 ADCM_RFSRRSensorCali_St "RightFront SRR Calibration Status
右前毫米波雷达标定状态";
CM_ SG_ 582 ADCM_FMRRSensorFail_St "Front MRR Failure Status
前方毫米波雷达故障状态";
CM_ SG_ 582 ADCM_FCamSensorFail_St "Front Camera 1 Failure Status
前方摄像头故障状态";
CM_ SG_ 582 ADCM_ReserveSensorFail_St "Reserved Sensor Failure Status
预留传感器故障状态";
CM_ SG_ 582 ADCM_LFSRRSensorFail_St "LeftFront SRR Failure Status
左前毫米波雷达故障状态";
CM_ SG_ 582 ADCM_LRSRRSensorFail_St "LeftRear SRR Failure Status
左后毫米波雷达故障状态";
CM_ SG_ 582 ADCM_RRSRRSensorFail_St "RightRear SRR Failure Status
右后毫米波雷达故障状态";
CM_ SG_ 582 ADCM_RFSRRSensorFail_St "RightFront SRR Failure Status
右前毫米波雷达故障状态";
CM_ SG_ 405 APA_FD2_Checksum1 "E2E Signal Group Checksum
Checksum is the actual value after calculation. See the 'ChecksumAlgorithm' sheet for the specific algorithm.
E2E信号组校验和Checksum为计算后实际值，具体算法参见“ChecksumAlgorithm”页";
CM_ SG_ 405 APA_FD2_RollingCounter1 "E2E Signal Group Counter
Counter value is automatically accumulated, added from 0 to 14 and then looped to the initial value of 0. Every time a message is sent, counter adds 1.
E2E信号组计数器Counter值为自动累加，从0加到14，然后循环至初始值0，每次报文发送，Counter加1";
CM_ SG_ 405 APA_ParkingState "Parking process
自动泊车进程（自动泊车系统状态机）,用于HMI显示";
CM_ SG_ 405 APA_ButtonPress_St_Reserved "APA button status_Reserved
APA开关动作状态（预留）";
CM_ SG_ 405 APA_QuitReason_Ind "APA quit reason indication
APA完全退出原因提示";
CM_ SG_ 405 APA_Recover_Ind "APA recovery interrupt indication
APA恢复中断提示";
CM_ SG_ 405 APA_DriverOperate_Ind "Driver operating indication
驾驶员操作提示信号";
CM_ SG_ 405 APA_ActiveSubFun "Activated function
自动泊车被激活的功能";
CM_ SG_ 405 APA_SelectParkSide_Ind "Selected parking position indication
指示当前选中的位置";
CM_ SG_ 405 APA_SelectParkTypeInd_Reserved "Selected parking type（reserved）
指示当前选中的泊车类型(预留)";
CM_ SG_ 405 APA_Left1stParkSlotType "The first parking slot type on the left
左侧第1个泊车位类型";
CM_ SG_ 405 APA_Left2cdParkSlotType "The second parking slot type on the left
左侧第2个泊车位类型";
CM_ SG_ 405 APA_APAAvaliable "APA functional available
APA功能可用状态";
CM_ SG_ 405 APA_RPAAvaliable "RPA functional available
RPA功能可用状态";
CM_ SG_ 405 APA_Left3rdParkSlotType "The third parking slot type on the left
左侧第3个泊车位类型";
CM_ SG_ 405 APA_Right1stParkSlotType "The first parking slot type on the right
右侧第1个泊车位类型";
CM_ SG_ 405 APA_Right2cdParkSlotType "The second parking slot type on the right
右侧第2个泊车位类型";
CM_ SG_ 405 APA_Right3rdParkSlotType "The third parking slot type on the right
右侧第3个泊车位类型";
CM_ SG_ 405 APA_FD2_Checksum2 "E2E Signal Group Checksum
Checksum is the actual value after calculation. See the 'ChecksumAlgorithm' sheet for the specific algorithm.
E2E信号组校验和Checksum为计算后实际值，具体算法参见“ChecksumAlgorithm”页";
CM_ SG_ 405 APA_FD2_RollingCounter2 "E2E Signal Group Counter
Counter value is automatically accumulated, added from 0 to 14 and then looped to the initial value of 0. Every time a message is sent, counter adds 1.
E2E信号组计数器Counter值为自动累加，从0加到14，然后循环至初始值0，每次报文发送，Counter加1";
CM_ SG_ 405 APA_IDCM_SVSIntelligentViewChangeSwitch_St "Intelligent view change switch status
智能视角切换开关状态";
CM_ SG_ 405 APA_IDCM_SVSdefaulttopviewSwitch_St "Select the SVS switch feedback by default
默认选择全景开关状态";
CM_ SG_ 405 APA_IDCM_SVSdefaultnormalviewSwitch_St "Select the normal view (wide Angle off) switch feedback by default
默认选择正常视角(广角关闭)开关状态";
CM_ SG_ 405 APA_IDCM_SVSBootAnimationswitch_St "Surround view animation request feedback
环视开机动画开关状态";
CM_ SG_ 405 APA_ParkingProgressBar_Ind "Parking progress bar indication
APA泊车进度条";
CM_ SG_ 405 APA_SVC_FrontCamera_St "Front camera status
前摄像头状态";
CM_ SG_ 405 APA_SVC_LeftCamera_St "Left camera status
左摄像头状态";
CM_ SG_ 405 APA_SVC_RightCamera_St "Right camera status
右摄像头状态";
CM_ SG_ 405 APA_SVC_RearCamera_St "Rear camera status
后摄像头状态";
CM_ SG_ 405 APA_SVS_System_St "Surround view system status
全景系统状态";
CM_ SG_ 405 APA_SVS_Active_St "Surround view funciton on  and off status
全景功能开启关闭状态";
CM_ SG_ 405 APA_SVS_SystemUnavailableReson "Surround view unavailable reason
全景不可用原因";
CM_ SG_ 405 APA_IDCM_PASAcousticWarn_St "Radar acoustic alarm status
泊车雷达声音报警开启状态";
CM_ SG_ 405 APA_SVS_CurrentView "Current display view status
当前显示视角状态";
CM_ SG_ 405 APA_IDCM_ObjectOverlay_St "Object overlay on and off status
车辆障碍物辅助线开启状态";
CM_ SG_ 405 APA_SVS_BasPlateTex_St "Transparent chassis on and off status
车底纹理化（透明底盘）开启状态";
CM_ SG_ 405 APA_IDCM_SVSTrajectoryOverlay_St "Vehicle trajectoy on and off status
车辆行进轨迹开启状态";
CM_ SG_ 405 APA_SVSMODE_FD "Surround view mode setting feedback
全景模式设置反馈";
CM_ SG_ 405 APA_FrontPMAEB_St "Front PMAEB function status
前低速辅助制动系统状态信号";
CM_ SG_ 405 APA_RearPMAEB_St "Rear PMAEB function status
后低速辅助制动系统状态信号";
CM_ SG_ 405 APA_PMAEB_Setting_St "PMAEB function setting status
低速辅助制动开启状态信号";
CM_ SG_ 584 APA_FD3_Checksum1 "E2E Signal Group Checksum
Checksum is the actual value after calculation. See the 'ChecksumAlgorithm' sheet for the specific algorithm.
E2E信号组校验和Checksum为计算后实际值，具体算法参见“ChecksumAlgorithm”页";
CM_ SG_ 584 APA_FD3_RollingCounter1 "E2E Signal Group Counter
Counter value is automatically accumulated, added from 0 to 14 and then looped to the initial value of 0. Every time a message is sent, counter adds 1.
E2E信号组计数器Counter值为自动累加，从0加到14，然后循环至初始值0，每次报文发送，Counter加1";
CM_ SG_ 584 APA_PAS_SwFdbkIDCMPAS_Reserved "PAS Switch Feedback (Reserved)
泊车辅助功能开关反馈（预留）";
CM_ SG_ 584 APA_PAS_WorkingMode "Working mode of reversing radar
倒车雷达的工作模式";
CM_ SG_ 584 APA_PAS_BuzzerWarning "Buzzer alarm level
蜂鸣器报警信号";
CM_ SG_ 584 APA_DefaultAeraObstacleWarning_Reserved "Default aera obstacle warning (reserved)
预设区是否有障碍物（预留）
预设区：左中后和右中后交集区";
CM_ SG_ 584 APA_PASFLDistance "Front Left area distance display
倒车雷达左前区距离显示";
CM_ SG_ 584 APA_PASFMLDistance "Front middle Left area distance display
倒车雷达左中前区距离显示";
CM_ SG_ 584 APA_PASFMRDistance "Front Middle Right area distance display
倒车雷达右中前区距离显示";
CM_ SG_ 584 APA_PASFRDistance "Front Right area distance display
倒车雷达右前区距离显示";
CM_ SG_ 584 APA_FD3_Checksum2 "E2E Signal Group Checksum
Checksum is the actual value after calculation. See the 'ChecksumAlgorithm' sheet for the specific algorithm.
E2E信号组校验和Checksum为计算后实际值，具体算法参见“ChecksumAlgorithm”页";
CM_ SG_ 584 APA_FD3_RollingCounter2 "E2E Signal Group Counter
Counter value is automatically accumulated, added from 0 to 14 and then looped to the initial value of 0. Every time a message is sent, counter adds 1.
E2E信号组计数器Counter值为自动累加，从0加到14，然后循环至初始值0，每次报文发送，Counter加1";
CM_ SG_ 584 APA_PASRLDistance "Rear Left area distance display
倒车雷达左后区距离显示";
CM_ SG_ 584 APA_PASRRDistance "Rear Right area distance display
倒车雷达右后区距离显示";
CM_ SG_ 584 APA_PASRMLDistance "Rear Middle Left area distance display
倒车雷达左中后区距离显示";
CM_ SG_ 584 APA_PASRMRDistance "Rear Middle Right area distance display 
倒车雷达右中后区距离显示";
CM_ SG_ 584 APA_FSideAreaScand "The front side area is scanned
前侧边区域被扫瞄";
CM_ SG_ 584 APA_FMSideAreaScand "The front middle side area is scanned
前中侧边区域被扫瞄";
CM_ SG_ 584 APA_RSideAreaScand "The rear side area is scanned
后侧边区域被扫瞄";
CM_ SG_ 584 APA_RMSideAreaScand "The rear middle side area is scanned
后中侧边区域被扫瞄";
CM_ SG_ 584 APA_FD3_Checksum3 "E2E Signal Group Checksum
Checksum is the actual value after calculation. See the 'ChecksumAlgorithm' sheet for the specific algorithm.
E2E信号组校验和Checksum为计算后实际值，具体算法参见“ChecksumAlgorithm”页";
CM_ SG_ 584 APA_FD3_RollingCounter3 "E2E Signal Group Counter
Counter value is automatically accumulated, added from 0 to 14 and then looped to the initial value of 0. Every time a message is sent, counter adds 1.
E2E信号组计数器Counter值为自动累加，从0加到14，然后循环至初始值0，每次报文发送，Counter加1";
CM_ SG_ 584 APA_SDW_FLSideDistance "Front Left side area distance display
左前侧边障碍物距离";
CM_ SG_ 584 APA_SDW_FRSideDistance "Front Right side area distance display
右前侧边障碍物距离";
CM_ SG_ 584 APA_SDW_RLSideDistance "Rear Left side area distance display
左后侧边障碍物距离";
CM_ SG_ 584 APA_SDW_RRSideDistance "Rear Right side area distance display
右后侧边障碍物距离";
CM_ SG_ 584 APA_SDW_FMLSideDistance "Front Middle Left side area distance display
左中前障碍物距离";
CM_ SG_ 584 APA_SDW_FMRSideDistance "Front Middle Right side area distance display
右中前障碍物距离";
CM_ SG_ 584 APA_FD3_Checksum4 "E2E Signal Group Checksum
Checksum is the actual value after calculation. See the 'ChecksumAlgorithm' sheet for the specific algorithm.
E2E信号组校验和Checksum为计算后实际值，具体算法参见“ChecksumAlgorithm”页";
CM_ SG_ 584 APA_FD3_RollingCounter4 "E2E Signal Group Counter
Counter value is automatically accumulated, added from 0 to 14 and then looped to the initial value of 0. Every time a message is sent, counter adds 1.
E2E信号组计数器Counter值为自动累加，从0加到14，然后循环至初始值0，每次报文发送，Counter加1";
CM_ SG_ 584 APA_SDW_RMLSideDistance "Rear Middle Left side area distance display
左中后障碍物距离";
CM_ SG_ 584 APA_SDW_RMRSideDistance "Rear Middle Right side area distance display
右中后障碍物距离";
CM_ SG_ 586 APA_L1SlotEdge1LateralPosition "The x coordinate of the first point  on left slot 1
左侧第1个车位角点1横坐标位置";
CM_ SG_ 586 APA_L1SlotEdge1LongitudinalPosition "The y coordinate of the first point  on left slot 1
左侧第1个车位角点1纵坐标位置";
CM_ SG_ 586 APA_L1SlotEdge2LateralPosition "The x coordinate of the second point on left  slot 1
左侧第1个车位角点2横坐标位置";
CM_ SG_ 586 APA_L1SlotEdge2LongitudinalPosition "The y coordinate of the second point on left slot 1
左侧第1个车位角点2纵坐标位置";
CM_ SG_ 586 APA_L1SlotEdge3LateralPosition_Reserved "The x coordinate of the third point  on left slot 1_Reserved
左侧第1个车位角点3横坐标位置（预留）";
CM_ SG_ 586 APA_L1SlotEdge3LongitudinalPosition_Reserved "The y coordinate of the third point on left slot 1_Reserved
左侧第1个车位角点3纵坐标位置（预留）";
CM_ SG_ 586 APA_L1SlotEdge4LateralPosition_Reserved "The x coordinate of the fourth point on left slot 1_Reserved
左侧第1个车位角点4横坐标位置（预留）";
CM_ SG_ 586 APA_L1SlotEdge4LongitudinalPosition_Reserved "The y coordinate of the fourth point on left slot 1_Reserved
左侧第1个车位角点4纵坐标位置（预留）";
CM_ SG_ 586 APA_L2SlotEdge1LateralPosition "The x coordinate of the first point  on left slot 2
左侧第2个车位角点1横坐标位置";
CM_ SG_ 586 APA_L2SlotEdge1LongitudinalPosition "The y coordinate of the first point  on left slot 2
左侧第2个车位角点1纵坐标位置";
CM_ SG_ 586 APA_L2SlotEdge2LateralPosition "The x coordinate of the second point on left  slot 2
左侧第2个车位角点2横坐标位置";
CM_ SG_ 586 APA_L2SlotEdge2LongitudinalPosition "The y coordinate of the second point on left slot 2
左侧第2个车位角点2纵坐标位置";
CM_ SG_ 586 APA_L2SlotEdge3LateralPosition_Reserved "The x coordinate of the third point  on left slot 2_Reserved
左侧第2个车位角点3横坐标位置（预留）";
CM_ SG_ 586 APA_L2SlotEdge3LongitudinalPosition_Reserved "The y coordinate of the third point on left slot 2_Reserved
左侧第2个车位角点3纵坐标位置（预留）";
CM_ SG_ 586 APA_L2SlotEdge4LateralPosition_Reserved "The x coordinate of the fourth point on left slot 2_Reserved
左侧第2个车位角点4横坐标位置（预留）";
CM_ SG_ 586 APA_L2SlotEdge4LongitudinalPosition_Reserved "The y coordinate of the fourth point on left slot 2_Reserved
左侧第2个车位角点4纵坐标位置（预留）";
CM_ SG_ 588 APA_L3SlotEdge1LateralPosition "The x coordinate of the first point  on left slot 3
左侧第3个车位角点1横坐标位置";
CM_ SG_ 588 APA_L3SlotEdge1LongitudinalPosition "The y coordinate of the first point  on left slot 3
左侧第3个车位角点1纵坐标位置";
CM_ SG_ 588 APA_L3SlotEdge2LateralPosition "The x coordinate of the second point on left  slot 3
左侧第3个车位角点2横坐标位置";
CM_ SG_ 588 APA_L3SlotEdge2LongitudinalPosition "The y coordinate of the second point on left slot 3
左侧第3个车位角点2纵坐标位置";
CM_ SG_ 588 APA_L3SlotEdge3LateralPosition_Reserved "The x coordinate of the third point  on left slot 3_Reserved
左侧第3个车位角点3横坐标位置（预留）";
CM_ SG_ 588 APA_L3SlotEdge3LongitudinalPosition_Reserved "The y coordinate of the third point on left slot 3_Reserved
左侧第3个车位角点3纵坐标位置（预留）";
CM_ SG_ 588 APA_L3SlotEdge4LateralPosition_Reserved "The x coordinate of the fourth point on left slot 3_Reserved
左侧第3个车位角点4横坐标位置（预留）";
CM_ SG_ 588 APA_L3SlotEdge4LongitudinalPosition_Reserved "The y coordinate of the fourth point on left slot 3_Reserved
左侧第3个车位角点4纵坐标位置（预留）";
CM_ SG_ 588 APA_R1SlotEdge1LateralPosition "The x coordinate of the first point  on right slot 1
右侧第1个车位角点1横坐标位置";
CM_ SG_ 588 APA_R1SlotEdge1LongitudinalPosition "The y coordinate of the first point  on right slot 1
右侧第1个车位角点1纵坐标位置";
CM_ SG_ 588 APA_R1SlotEdge2LateralPosition "The x coordinate of the second point on right  slot 1
右侧第1个车位角点2横坐标位置";
CM_ SG_ 588 APA_R1SlotEdge2LongitudinalPosition "The y coordinate of the second point on right slot 1
右侧第1个车位角点2纵坐标位置";
CM_ SG_ 588 APA_R1SlotEdge3LateralPosition_Reserved "The x coordinate of the third point  on right slot 1_Reserved
右侧第1个车位角点3横坐标位置（预留）";
CM_ SG_ 588 APA_R1SlotEdge3LongitudinalPosition_Reserved "The y coordinate of the third point on right slot 1_Reserved
右侧第1个车位角点3纵坐标位置（预留）";
CM_ SG_ 588 APA_R1SlotEdge4LateralPosition_Reserved "The x coordinate of the fourth point on right slot 1_Reserved
右侧第1个车位角点4横坐标位置（预留）";
CM_ SG_ 588 APA_R1SlotEdge4LongitudinalPosition_Reserved "The y coordinate of the fourth point on right slot 1_Reserved
右侧第1个车位角点4纵坐标位置（预留）";
CM_ SG_ 590 APA_R2SlotEdge1LateralPosition "The x coordinate of the first point  on right slot 2
右侧第2个车位角点1横坐标位置";
CM_ SG_ 590 APA_R2SlotEdge1LongitudinalPosition "The y coordinate of the first point  on right slot 2
右侧第2个车位角点1纵坐标位置";
CM_ SG_ 590 APA_R2SlotEdge2LateralPosition "The x coordinate of the second point on right  slot 2
右侧第2个车位角点2横坐标位置";
CM_ SG_ 590 APA_R2SlotEdge2LongitudinalPosition "The y coordinate of the second point on right slot 2
右侧第2个车位角点2纵坐标位置";
CM_ SG_ 590 APA_R2SlotEdge3LateralPosition_Reserved "The x coordinate of the third point  on right slot 2_Reserved
右侧第2个车位角点3横坐标位置（预留）";
CM_ SG_ 590 APA_R2SlotEdge3LongitudinalPosition_Reserved "The y coordinate of the third point on right slot 2_Reserved
右侧第2个车位角点3纵坐标位置（预留）";
CM_ SG_ 590 APA_R2SlotEdge4LateralPosition_Reserved "The x coordinate of the fourth point on right slot 2_Reserved
右侧第2个车位角点4横坐标位置（预留）";
CM_ SG_ 590 APA_R2SlotEdge4LongitudinalPosition_Reserved "The y coordinate of the fourth point on right slot 2_Reserved
右侧第2个车位角点4纵坐标位置（预留）";
CM_ SG_ 590 APA_R3SlotEdge1LateralPosition "The x coordinate of the first point  on right slot 3
右侧第3个车位角点1横坐标位置";
CM_ SG_ 590 APA_R3SlotEdge1LongitudinalPosition "The y coordinate of the first point  on right slot 3
右侧第3个车位角点1纵坐标位置";
CM_ SG_ 590 APA_R3SlotEdge2LateralPosition "The x coordinate of the second point on right  slot 3
右侧第3个车位角点2横坐标位置";
CM_ SG_ 590 APA_R3SlotEdge2LongitudinalPosition "The y coordinate of the second point on right slot 3
右侧第3个车位角点2纵坐标位置";
CM_ SG_ 590 APA_R3SlotEdge3LateralPosition_Reserved "The x coordinate of the third point  on right slot 3_Reserved
右侧第3个车位角点3横坐标位置（预留）";
CM_ SG_ 590 APA_R3SlotEdge3LongitudinalPosition_Reserved "The y coordinate of the third point on right slot 3_Reserved
右侧第3个车位角点3纵坐标位置（预留）";
CM_ SG_ 590 APA_R3SlotEdge4LateralPosition_Reserved "The x coordinate of the fourth point on right slot 3_Reserved
右侧第3个车位角点4横坐标位置（预留）";
CM_ SG_ 590 APA_R3SlotEdge4LongitudinalPosition_Reserved "The y coordinate of the fourth point on right slot 3_Reserved
右侧第3个车位角点4纵坐标位置（预留）";
CM_ SG_ 596 DSM_FD2_Checksum1 "E2E Signal Group Checksum
Checksum is the actual value after calculation. See the 'ChecksumAlgorithm' sheet for the specific algorithm.
E2E信号组校验和Checksum为计算后实际值，具体算法参见“ChecksumAlgorithm”页";
CM_ SG_ 596 DSM_FD2_RollingCounter1 "E2E Signal Group Counter
Counter value is automatically accumulated, added from 0 to 14 and then looped to the initial value of 0. Every time a message is sent, counter adds 1.
E2E信号组计数器Counter值为自动累加，从0加到14，然后循环至初始值0，每次报文发送，Counter加1";
CM_ SG_ 596 DSM_DriverWatchRegion "Region of driver are watching
驾驶员注视区域";
CM_ SG_ 596 DSM_SystemError_St "Driver monitoring system error status
DSM系统故障状态";
CM_ SG_ 596 DSM_DriverDetect_St "States whether the driver facing camera has detected the presence of a driver
是否探测到驾驶员存在状态";
CM_ SG_ 596 DSM_FatigueFunction_St "Driver fatigue warning function State
驾驶员疲劳报警功能状态";
CM_ SG_ 596 DSM_FatigueWarn_St "Indicates the fatigue warning level of the driver
驾驶员疲劳等级";
CM_ SG_ 596 DSM_L3DriverFatigue_St "driver fatigue state for L3
用于L3系统的驾驶员疲劳等级";
CM_ SG_ 596 DSM_L3DriverDistraction_St "driver distraction state for L3
用于L3系统的驾驶员分心等级";
CM_ SG_ 596 DSM_FD2_Checksum2 "E2E Signal Group Checksum
Checksum is the actual value after calculation. See the 'ChecksumAlgorithm' sheet for the specific algorithm.
E2E信号组校验和Checksum为计算后实际值，具体算法参见“ChecksumAlgorithm”页";
CM_ SG_ 596 DSM_FD2_RollingCounter2 "E2E Signal Group Counter
Counter value is automatically accumulated, added from 0 to 14 and then looped to the initial value of 0. Every time a message is sent, counter adds 1.
E2E信号组计数器Counter值为自动累加，从0加到14，然后循环至初始值0，每次报文发送，Counter加1";
CM_ SG_ 596 DSM_Response_RecognitionFaceStatus "Status whether the user recognize FaceID successfully
DSM识别人脸状态反馈";
CM_ SG_ 596 DSM_Response_UserID "UserID
用户ID反馈";
CM_ SG_ 596 DSM_UserID_SourceCode "UserID Source Code
用户ID原码";
CM_ SG_ 596 DSM_HeadPositionX "Driver Head Position dataX
驾驶员头部位置X方向";
CM_ SG_ 596 DSM_HeadPositionY "Driver Head Position dataY
驾驶员头部位置Y方向";
CM_ SG_ 596 DSM_HeadPositionZ "Driver Head Position dataZ
驾驶员头部位置Z方向";
CM_ SG_ 596 DSM_HeadAngleX "Driver Head Rotation Angle X
驾驶员头部X方向旋转角度";
CM_ SG_ 596 DSM_HeadAngleY "Driver Head Rotation Angle Y
驾驶员头部Y方向旋转角度";
CM_ SG_ 385 ACU_1_Checksum1 "E2E Signal Group Checksum
Checksum is the actual value after calculation. See the 'ChecksumAlgorithm' sheet for the specific algorithm.
E2E信号组校验和
Checksum为计算后实际值，具体算法参见“ChecksumAlgorithm”页";
CM_ SG_ 385 ACU_1_RollingCounter1 "E2E Signal Group Counter
Counter value is automatically accumulated, added from 0 to 14 and then looped to the initial value of 0. Every time a message is sent, counter adds 1.
E2E信号组计数器
Counter值为自动累加，从0加到14，然后循环至初始值0，每次报文发送，Counter加1";
CM_ SG_ 385 ACU_FrontCrashOutput_St "Front Crash(including BT,AB) 正面碰撞输出";
CM_ SG_ 385 ACU_DriverSideCrashOutput_St "Driver Side Crash 驾驶员侧面碰撞输出";
CM_ SG_ 385 ACU_PassengerSideCrashOutput_St "Passenger Side Crash 副驾驶侧面碰撞输出";
CM_ SG_ 385 ACU_RearSideCrashOutput_St "Rear Side Crash 后侧碰撞输出";
CM_ SG_ 385 ACU_WarnLampSt "Warning Lamp State
ACU故障信号（警告灯信 号）";
CM_ SG_ 385 ACU_PassengerAirbagSt "Passenger Airbag State 副驾气囊状态";
CM_ SG_ 385 ACU_1_Checksum2 "E2E Signal Group Checksum
Checksum is the actual value after calculation. See the 'ChecksumAlgorithm' sheet for the specific algorithm.
E2E信号组校验和
Checksum为计算后实际值，具体算法参见“ChecksumAlgorithm”页";
CM_ SG_ 385 ACU_1_RollingCounter2 "E2E Signal Group Counter
Counter value is automatically accumulated, added from 0 to 14 and then looped to the initial value of 0. Every time a message is sent, counter adds 1.
E2E信号组计数器
Counter值为自动累加，从0加到14，然后循环至初始值0，每次报文发送，Counter加1";
CM_ SG_ 385 ACU_DriverSeatBelt_St "Driver buckle switch status
主驾安全带状态";
CM_ SG_ 385 ACU_DriverSeatBelt_Valid "Driver buckle switch status valid
主驾安全带状态有效位";
CM_ SG_ 385 ACU_DriverSBR_St "Driver side SBR status
主驶安全带未系提醒状态";
CM_ SG_ 385 ACU_PassengerSBR_St "Passenger Side SBR status
副驶安全带未系提醒状态";
CM_ SG_ 385 ACU_SRLSBR_St "Driver side 2nd row SBR status
主驶2排安全带未系提醒 状态(OPSR2D in Series)";
CM_ SG_ 385 ACU_SRRSBR_St "Passenger Side 2nd row SBR status
副驾2排安全带未系提醒 状态(OPSR2P in series)";
CM_ SG_ 385 ACU_SeatBeltSoundReminder_St "Seat belt remind sound signal status
安全带声音信号提醒状态";
CM_ SG_ 386 ACU_2_Checksum1 "E2E Signal Group Checksum
Checksum is the actual value after calculation. See the 'ChecksumAlgorithm' sheet for the specific algorithm.
E2E信号组校验和
Checksum为计算后实际值，具体算法参见“ChecksumAlgorithm”页";
CM_ SG_ 386 ACU_2_RollingCounter1 "E2E Signal Group Counter
Counter value is automatically accumulated, added from 0 to 14 and then looped to the initial value of 0. Every time a message is sent, counter adds 1.
E2E信号组计数器
Counter值为自动累加，从0加到14，然后循环至初始值0，每次报文发送，Counter加1";
CM_ SG_ 386 ACU_LongitudeAcceleration "Longitude Acceleration
X方向加速度";
CM_ SG_ 386 ACU_LongitudeAccelerationSensor_St "Longitude Acceleration Sensor State
X方向加速度状态";
CM_ SG_ 386 ACU_2_Checksum2 "E2E Signal Group Checksum
Checksum is the actual value after calculation. See the 'ChecksumAlgorithm' sheet for the specific algorithm.
E2E信号组校验和
Checksum为计算后实际值，具体算法参见“ChecksumAlgorithm”页";
CM_ SG_ 386 ACU_2_RollingCounter2 "E2E Signal Group Counter
Counter value is automatically accumulated, added from 0 to 14 and then looped to the initial value of 0. Every time a message is sent, counter adds 1.
E2E信号组计数器
Counter值为自动累加，从0加到14，然后循环至初始值0，每次报文发送，Counter加1";
CM_ SG_ 386 ACU_LateralAcceleration "Lateral Acceleration
Y方向加速度";
CM_ SG_ 386 ACU_LateralAccelerationSensor_St "Lateral Accelaration Sensor State
Y方向加速度状态";
CM_ SG_ 417 ESC_FD2_Checksum3 "E2E Signal Group Checksum
Checksum is the actual value after calculation. See the 'ChecksumAlgorithm' sheet for the specific algorithm.
E2E信号组校验和
Checksum为计算后实际值，具体算法参见“ChecksumAlgorithm”页";
CM_ SG_ 417 ESC_FD2_RollingCounter3 "E2E Signal Group Counter
Counter value is automatically accumulated, added from 0 to 14 and then looped to the initial value of 0. Every time a message is sent, counter adds 1.
E2E信号组计数器
Counter值为自动累加，从0加到14，然后循环至初始值0，每次报文发送，Counter加1";
CM_ SG_ 417 ESC_Intervention "Info lamp - Indication that VDC/TCS(engine torque control or brake torque control) system currently performs a brake/engine intervention
指示VDC/TCS(发动机扭矩控制或制动扭矩控制)系统当前执行制动/发动机干预";
CM_ SG_ 417 ESC_ESCError "ESC_Fault: VDC/TCS is switched off due to detected failure
ESC_Fault:由于检测到故障，VDC/TCS被关闭";
CM_ SG_ 417 ESC_TCSIntervention "TCS controller active: Brake intervention or Engine torque reduction intervention
主动TCS控制器:制动干预或发动机转矩降低干预";
CM_ SG_ 417 ESC_VDCIntervention "VDC controller active: Oversteering brake intervention or Understeering brake intervention
主动VDC控制器:转向过度或转向不足制动干预";
CM_ SG_ 417 ESC_ABSIntervention "ABS control active - Indication that ESP system (especially ABS module) currently performs a brake intervention
主动ABS控制-指示ESP系统(特别是ABS模块)当前执行制动干预";
CM_ SG_ 417 ESC_ABSError "ABS_Fault: ESP system has detected a failure which does not allow a reliable ABS regulation and is therefore switched off
ABS_Fault: ESP系统检测到一个故障，不允许可靠的ABS调节，因此被关闭";
CM_ SG_ 417 ESC_EBDIntervention "EBD control active - Indication that ESP system (especially EBD module) currently performs a brake intervention
EBD控制激活-指示ESP系统(特别是EBD模块)当前执行制动干预";
CM_ SG_ 417 ESC_EBDError "EBD_Fault: ESP system has detected a heavy fault, which does not even allow a reliable electronic brake distribution and is therefore completely shut down
EBD_Fault: ESP系统检测到严重故障，甚至不允许可靠的电子制动分布，因此完全关闭";
CM_ SG_ 417 ESC_FD2_Checksum4 "E2E Signal Group Checksum
Checksum is the actual value after calculation. See the 'ChecksumAlgorithm' sheet for the specific algorithm.
E2E信号组校验和
Checksum为计算后实际值，具体算法参见“ChecksumAlgorithm”页";
CM_ SG_ 417 ESC_FD2_RollingCounter4 "E2E Signal Group Counter
Counter value is automatically accumulated, added from 0 to 14 and then looped to the initial value of 0. Every time a message is sent, counter adds 1.
E2E信号组计数器
Counter值为自动累加，从0加到14，然后循环至初始值0，每次报文发送，Counter加1";
CM_ SG_ 417 ESC_BraBoostwarning "Both Eb and ESC（HBC） brake boost fail, dash board light the red brake warnning lamp
If Only EB fails，light the yellow brake warnning lamp，same as EB_WarningLampCtl_Req()

If Only ESC fails，light the ESC error lamp，not this brake warnning lamp
EB和ESC助力都失效，仪表量红灯，
仅EB失效，仪表亮黄灯,仅ESC失效，亮ESC自己的报警灯";
CM_ SG_ 417 ESC_VehicleStandstill_St "Indicate whether the vehicle is standstill or not (if two wheels are standstill).
Set to a desired state when standstill is surely reached.
指示车辆是否停止(是否两个轮子停止)。
设置到所需的状态时，一定达到停顿。";
CM_ SG_ 417 ESC_VehicleStandstillSt_Valid "Check the validity of the signal of Vehicle Standstill St.
检查Vehicle Standstill St信号的有效性。";
CM_ SG_ 417 ESC_AVHSt "Indicates AVH Status
表明AVH状态";
CM_ SG_ 417 ESC_AVHAvailable "AVH Available
AVH可用";
CM_ SG_ 417 ESC_HHCSt "Indicate HHC active signal
表明HHC激活信号";
CM_ SG_ 417 ESC_HHCAvailable "HHC Available
HHC可用";
CM_ SG_ 417 ESC_HDCAvailable "HDC Available
HDC可用";
CM_ SG_ 417 ESC_HDC_St "HDC control(Off/On, not active braking/On, active braking)
HDC控制(关/开，非主动制动/开，主动制动)";
CM_ SG_ 417 ESC_HBB_St "Signal description: This signal indicates the status of HBB.
CAN-PR get the degrade system inforamtion from DSW directly.
信号说明:此信号表示HBB状态。
可以直接从DSW中得到降级系统的信息。";
CM_ SG_ 417 ESC_HBBActive "This signal indicates if HBB is active or not.
Application 13.1 is already available CNMS7. In Application 11.1 and Application 12.1 should adapte in ASCET database.
此信号指示HBB是否处于活动状态。
申请13.1已提供CNMS7。在应用程序11.1和应用程序12.1中应该适应ASCET数据库。";
CM_ SG_ 417 ESC_CDP_St "Indicates CDP control active
表明CDP控制激活";
CM_ SG_ 417 ESC_CDPAvailable "Controller Deceleration Parking Avaliable
CDP可用";
CM_ SG_ 417 ESC_CruiseControlShutDown "Switch off of the Cruise control(on/off)(if there is cruise control function)
Cruise control with ACC/CC
the status for HdcCtrlStatus = 1:On active braking || 2:On not active braking
->Shutdown the Cruise control (if the speed threshold is conflict with HDC)
巡航控制开关(开/关)(如有巡航控制功能)
巡航控制与ACC/CC
HdcCtrlStatus = 1:主动制动|| 2:非主动制动
->关闭巡航控制(如果速度阈值与HDC冲突)";
CM_ SG_ 417 ESC_PataLamp "ESP is diabled by pata
(Only include TCS function,VDC always ON)
ESC开启开关(只有TCS功能的开关，VDC功能一直开启)";
CM_ SG_ 417 ESC_BrakeLight_Req "Request brake light
刹车灯请求";
CM_ SG_ 417 ESC_EmergencyBrakeLight_Req "Request emergency brake light
紧急制动灯请求";
CM_ SG_ 417 ESC_EPB_St "Status of EPB system
EPB系统状态";
CM_ SG_ 417 ESC_EPBFunctionLamp "EPB functon lamp status, dashboard receive this signal to illuminate the function lamp
EPB功能指示灯状态，仪表接收到该信号后需点亮功能灯";
CM_ SG_ 417 ESC_EPBFailLamp "EPB failure lamp status, dashboard receive this signal to illuminate the failure lamp
EPB故障指示灯，仪表接收到该信号后需点亮故障灯";
CM_ SG_ 417 ESC_EPBWarnMessage "Additional warning message to inform the driver how to do the next step.
EPB报警信息";
CM_ SG_ 417 ESC_EPBSwitch_St "EPB switch status
EPB开关状态";
CM_ SG_ 417 ESC_EPBTipInfo "EPB Tip Information
EPB提醒信息";
CM_ SG_ 417 ESC_EPBError "EPB Error Status
EPB故障状态";
CM_ SG_ 417 ESC_HBAActive "HBA Active
HBA激活";
CM_ SG_ 417 ESC_HBAAvailable "HBA Available
HBA 可用";
CM_ SG_ 417 ESC_EPBSwitchSt_Valid "EPB switch status validity
EPB开关状态有效位";
CM_ SG_ 417 ESC_BrakePedalApplied_OnlyForIV2 "information about the driver attendance
驾驶员参与信息";
CM_ SG_ 417 ESC_BrakePedalApplied_St_OnlyForIV2 "Qualifier for BrakePedalApplied
限定符对BrakePedalApplied";
CM_ SG_ 417 ESC_AVH_DriverAbsentWarn "warning signal when AVH button is pressed and driver isn't pressent.
按下AVH按钮但驾驶员不在的报警信号";
CM_ SG_ 417 ESC_FD2_Checksum5 "E2E Signal Group Checksum
Checksum is the actual value after calculation. See the 'ChecksumAlgorithm' sheet for the specific algorithm.
E2E信号组校验和
Checksum为计算后实际值，具体算法参见“ChecksumAlgorithm”页";
CM_ SG_ 417 ESC_FD2_RollingCounter5 "E2E Signal Group Counter
Counter value is automatically accumulated, added from 0 to 14 and then looped to the initial value of 0. Every time a message is sent, counter adds 1.
E2E信号组计数器
Counter值为自动累加，从0加到14，然后循环至初始值0，每次报文发送，Counter加1";
CM_ SG_ 417 ESC_VehicleSpeed "Vehicle speed out
车速";
CM_ SG_ 417 ESC_VehicleSpeed_Valid "Vehicle speed out status
车速有效";
CM_ SG_ 199 ESC_FD6_Checksum1 "E2E Signal Group Checksum
Checksum is the actual value after calculation. See the 'ChecksumAlgorithm' sheet for the specific algorithm.
E2E信号组校验和
Checksum为计算后实际值，具体算法参见“ChecksumAlgorithm”页";
CM_ SG_ 199 ESC_FD6_RollingCounter1 "E2E Signal Group Counter
Counter value is automatically accumulated, added from 0 to 14 and then looped to the initial value of 0. Every time a message is sent, counter adds 1.
E2E信号组计数器
Counter值为自动累加，从0加到14，然后循环至初始值0，每次报文发送，Counter加1";
CM_ SG_ 199 ESC_CampingMode_Rsp "Camping Mode Response
展厅模式状态反馈";
CM_ SG_ 199 ESC_CampingModeWarning "Camping Mode can't release EPB Warning
展厅模式无法释放EPB报警信号";
CM_ SG_ 199 ESC_WorkMode "ESC Working Mode
ESC当前模式";
CM_ SG_ 199 ESC_ModeChangeEnable "ESC Mode Change Enable
ESC模式接口可用";
CM_ SG_ 190 EB_FD1_Checksum1 "E2E Signal Group Checksum
Checksum is the actual value after calculation. See the 'ChecksumAlgorithm' sheet for the specific algorithm.
E2E信号组校验和
Checksum为计算后实际值，具体算法参见“ChecksumAlgorithm”页";
CM_ SG_ 190 EB_FD1_RollingCounter1 "E2E Signal Group Counter
Counter value is automatically accumulated, added from 0 to 14 and then looped to the initial value of 0. Every time a message is sent, counter adds 1.
E2E信号组计数器
Counter值为自动累加，从0加到14，然后循环至初始值0，每次报文发送，Counter加1";
CM_ SG_ 190 EB_OutputRodDriver "inputrod of driver brake request.
输入司机制动请求。";
CM_ SG_ 190 EB_OutputRodDriver_St "Information about the signal quality of EB_OutputRodDriver
关于EB_OutputRodDriver信号质量的信息";
CM_ SG_ 428 EB_BrakePedalApplied "information about the driver attendance
驾驶员参与信息";
CM_ SG_ 428 EB_BrakePedalApplied_St "Qualifier for BrakePedalApplied
限定符对BrakePedalApplied";
CM_ SG_ 428 EB_WarningLampCtl_Req "With this signal eBooster requests the warning lamp in the dashboard
使用这个信号，eBooster请求仪表板上的警告灯";
CM_ SG_ 428 EB_BrakeMode "dashboard request iBooster mode(sport mode or default mode or comfort mode)
踏板感觉模式";
CM_ SG_ 428 EB_ModeChangeEnable "Brake Mode state
踏板感觉模式切换接口可用";
CM_ SG_ 429 EPS_FD2_Checksum1 "E2E Signal Group Checksum
Checksum is the actual value after calculation. See the 'ChecksumAlgorithm' sheet for the specific algorithm.
E2E信号组校验和
Checksum为计算后实际值，具体算法参见“ChecksumAlgorithm”页";
CM_ SG_ 429 EPS_FD2_RollingCounter1 "E2E Signal Group Counter
Counter value is automatically accumulated, added from 0 to 14 and then looped to the initial value of 0. Every time a message is sent, counter adds 1.
E2E信号组计数器
Counter值为自动累加，从0加到14，然后循环至初始值0，每次报文发送，Counter加1";
CM_ SG_ 429 EPS_Failure_St "EPS failure status 
EPS失效状态";
CM_ SG_ 429 EPS_WorkMode "EPS working mode
EPS当前驾驶模式";
CM_ SG_ 429 EPS_ModeChangeEnable "EPS working mode change enable
EPS驾驶模式切换接口可用";
CM_ SG_ 429 EPS_HADError_RequestHADState "Requested HAD(L3) state validity status
HAD(L3)请求状态有效性";
CM_ SG_ 429 EPS_HADError_RequestRackPosition "Requested rack position validity status
请求的齿条位置状态有效性";
CM_ SG_ 429 EPS_HADError_ExternalMasterReq "External HAD controller requests to exit
外部HAD控制器请求退出HAD功能";
CM_ SG_ 429 EPS_HADError_ECUState "Local ECU error state
本地ECU故障状态";
CM_ SG_ 429 EPS_HADError_ErrorFlagFromRemoteECU "Remote ECU error flag
远程ECU故障标志位";
CM_ SG_ 429 EPS_HADError_HADStateMachineMonitorFault "Error found by HAD state machine monitoring component
HAD状态机监控模块发现故障";
CM_ SG_ 429 EPS_HADError_Reserved "EPS HAD enter error state reason (reserved)
EPS HAD(L3)进入错误状态的原因(预留)";
CM_ SG_ 429 EPS_HADOff_RackPositionSync "Synchronization status of rack position between two ECUs
两ECU间的齿条位置同步状态";
CM_ SG_ 429 EPS_HADOff_VehicleSpeedLimitation "Vehicle speed is over limitation
车速超过限值";
CM_ SG_ 429 EPS_HADOff_ErrorFromRemote "Off or abort error occurred from remote ECU
远程ECU发生了关闭或者退出故障";
CM_ SG_ 429 EPS_HADOff_EmergencyTakeOver "Emergency take over requested
紧急接管请求";
CM_ SG_ 429 EPS_HADOff_SafetyDriver_TBT "Torsion bar torque is over limitation by safety driver monitor
安全驾驶员功能监控到扭杆力矩超过限值";
CM_ SG_ 429 EPS_HADOff_SafetyDriver_RackSpeed "Rack speed is over limitation by safety driver monitor
安全驾驶员功能监控到齿条移动速度超过限值";
CM_ SG_ 429 EPS_HADOff_IPCStatus "IPC communication status between both ECUs
两ECU间IPC通信状态";
CM_ SG_ 429 EPS_HADOff_StayInInitialState "HAD is staying in initial state
HAD正停留在初始状态";
CM_ SG_ 429 EPS_HADOff_TorqueReduction "Torque reduction level is lower than limitation
助力力矩低于限值";
CM_ SG_ 429 EPS_HADOff_WaterSensor "Water in connector is detected by sensor
传感器检测到接插件有水";
CM_ SG_ 429 EPS_HADOff_MinVehicleSpeed "Minimize vehicle speed validity status
最小车速有效性状态";
CM_ SG_ 429 EPS_HADOff_GroundConnection "ECU ground connection status
ECU对地连接状态";
CM_ SG_ 429 EPS_HADOff_FunctionCoordinator "FunctionCoordinator activity status.
功能协调器使能状态";
CM_ SG_ 429 EPS_HADOff_StickSlipWarning "Stick slip activity status
EPS内部卡滞状态";
CM_ SG_ 429 EPS_HADOff_TBTStatus "Torsion bar torque error status
扭杆力矩值错误状态";
CM_ SG_ 429 EPS_HADOff_RPCTorqueValue "Requested motor torque from RPC compared to current EPS capability
齿条位置控制所需助力力矩是否超过EPS当前能提供的力矩";
CM_ SG_ 429 EPS_HADOff_DoubleDiagnosisState "Double diagnosis state
双重诊断状态";
CM_ SG_ 429 EPS_HADOff_FADERMonitor "Whether error found by FADER monitor component
FADER检测模块是否发现故障";
CM_ SG_ 429 EPS_HADOff_SupplyVoltageReduce "Supply voltage is reduced to low level
供电电压低于限值";
CM_ SG_ 429 EPS_HADOff_Reserved "what cause to EPS HAD enter off state (Reserved)
EPS HAD(L3)进入退出状态的原因(预留)";
CM_ SG_ 184 RWS_FD1_Checksum1 "E2E Signal Group Checksum
Checksum is the actual value after calculation. See the 'ChecksumAlgorithm' sheet for the specific algorithm.
E2E信号组校验和
Checksum为计算后实际值，具体算法参见“ChecksumAlgorithm”页";
CM_ SG_ 184 RWS_FD1_RollingCounter1 "E2E Signal Group Counter
Counter value is automatically accumulated, added from 0 to 14 and then looped to the initial value of 0. Every time a message is sent, counter adds 1.
E2E信号组计数器
Counter值为自动累加，从0加到14，然后循环至初始值0，每次报文发送，Counter加1";
CM_ SG_ 184 RWS_Status "Current status of RWS
RWS状态";
CM_ SG_ 184 RWS_Travel_valid "Rear wheel Steering status including IVC Rear steering control status.
后轮转向行程有效位";
CM_ SG_ 184 RWS_Travel "Rear Wheel Steering Travel
The travel should be positive when turn left and negative when turn right.The physical travel limit range is between -17.6 to 17.6mm.
后轮转向行程，行程往左为正，行程往右为负.物理行程极限范围为±17.6mm";
CM_ SG_ 184 RWS_WarningLamp "Indicated the failure state of RWS
后轮转向故障状态的警示灯信号";
CM_ SG_ 425 AIRS_FD1_Checksum1 "E2E Signal Group Checksum
Checksum is the actual value after calculation. See the 'ChecksumAlgorithm' sheet for the specific algorithm.
E2E信号组校验和
Checksum为计算后实际值，具体算法参见“ChecksumAlgorithm”页";
CM_ SG_ 425 AIRS_FD1_RollingCounter1 "E2E Signal Group Counter
Counter value is automatically accumulated, added from 0 to 14 and then looped to the initial value of 0. Every time a message is sent, counter adds 1.
E2E信号组计数器
Counter值为自动累加，从0加到14，然后循环至初始值0，每次报文发送，Counter加1";
CM_ SG_ 425 AIRS_WorkMode "Current Level control mode
当前随速调节模式";
CM_ SG_ 425 AIRS_ModeChangeEnable "When AirS has some special error and it can't respond to drive mode change request.
悬架由于特殊故障，不能响应驾驶模式变更请求";
CM_ SG_ 425 AIRS_CDCWorkMode "Current damping control mode    
阻尼控制模式";
CM_ SG_ 425 AIRS_CDCModeChangeEnable "Current damping control mode   enable
由于CDC故障，不能响应驾驶模式请求。";
CM_ SG_ 425 AIRS_EasyloadModeIndicated "Easy Loading Request Status
易装载模式激活状态";
CM_ SG_ 425 AIRS_EasyloadAvailability "Easy Loading Avaliability
易装载模式可用标志位";
CM_ SG_ 425 AIRS_VehicleSpeedDependentLevelSwitchSt "Vehicle Speed Dependent Level Switch Status
随速调节功能开关状态";
CM_ SG_ 425 AIRS_VehicleSpeedDependentLevelSwitchAvaliability "Vehicle Speed Dependent Level Switch Status Avaliability
随速调节功能开关状态标志位";
CM_ SG_ 425 AIRS_LiftModeAvailability "Lift Mode Avaliability
千斤顶模式可用标志位";
CM_ SG_ 425 AIRS_LiftModeIndicated "Level Control deactivation request status (Jack Mode)
禁用高度调节（千斤顶模式）的状态";
CM_ SG_ 425 AIRS_LevelCalibrationComplete "Level calibration completed    
高度传感器标定成功标志位";
CM_ SG_ 425 AIRS_ErrorLampRequest "Level adjust lamp request and DampingControlLamp Request
故障灯状态";
CM_ SG_ 425 AIRS_DampingError "Damping control Error Status
阻尼控制故障状态";
CM_ SG_ 425 AIRS_ErrorStatus "Level adjustment error
高度调节故障";
CM_ SG_ 425 AIRS_SystemTemporaryNotAvailable "Level Control Restriction Reason(Every bit of this signal represent one warning)
高度调节临时不可用（每一个位表示一种临时不可用的原因）";
CM_ SG_ 425 AIRS_ActionState "Every bit of this signal represent one adjustment activity
Bit0 Lowering
Bit1 Lifting
Bit2 Pending
Bit3 EasyLoadingActiveSwitching
Bit4 Readjustment
Bit5 Level change request by driver
Bit6 Automatic level change
Bit7 Reserved";
CM_ SG_ 425 AirS_OffRoadAvaliability "indicate to VDCM that off road available or not due to speed reason 
由于速度原因不可切换至off road标志位";
CM_ SG_ 425 AirS_OffRoadExitCommand "Indicate that AirS quites Off Road due to speed reason and command VDCM quite Off road .
空气悬架由于速度原因退出off Road并且要求VDCM改变驾驶模式";
CM_ SG_ 425 AIRS_FD1_Checksum2 "E2E Signal Group Checksum
Checksum is the actual value after calculation. See the 'ChecksumAlgorithm' sheet for the specific algorithm.
E2E信号组校验和
Checksum为计算后实际值，具体算法参见“ChecksumAlgorithm”页";
CM_ SG_ 425 AIRS_FD1_RollingCounter2 "E2E Signal Group Counter
Counter value is automatically accumulated, added from 0 to 14 and then looped to the initial value of 0. Every time a message is sent, counter adds 1.
E2E信号组计数器
Counter值为自动累加，从0加到14，然后循环至初始值0，每次报文发送，Counter加1";
CM_ SG_ 425 AIRS_FD1_Checksum3 "E2E Signal Group Checksum
Checksum is the actual value after calculation. See the 'ChecksumAlgorithm' sheet for the specific algorithm.
E2E信号组校验和
Checksum为计算后实际值，具体算法参见“ChecksumAlgorithm”页";
CM_ SG_ 425 AIRS_FD1_RollingCounter3 "E2E Signal Group Counter
Counter value is automatically accumulated, added from 0 to 14 and then looped to the initial value of 0. Every time a message is sent, counter adds 1.
E2E信号组计数器
Counter值为自动累加，从0加到14，然后循环至初始值0，每次报文发送，Counter加1";
CM_ SG_ 425 AIRS_TargetHeightIndication "Target height
目标高度";
CM_ SG_ 425 AIRS_Height_FL "Current Heights
左前高度";
CM_ SG_ 425 AIRS_Height_FR "Current Heights
右前高度";
CM_ SG_ 425 AIRS_Height_RL "Current Heights
左后高度";
CM_ SG_ 425 AIRS_Height_RR "Current Heights
右后高度";

BA_DEF_ BO_  "NmMessage" ENUM "No","Yes";
BA_DEF_ BO_  "GenMsgSendType" ENUM  "cyclic","Event","IfActive","CE","CA","NoMsgSendType";
BA_DEF_ BO_  "GenMsgCycleTime" INT 0 0;
BA_DEF_ SG_  "GenSigSendType" ENUM  "cyclic","OnChange","OnWrite","IfActive","OnChangeWithRepetition","OnWriteWithRepetition","IfActiveWithRepetition","NoSigSendType","OnChangeAndIfActive","OnChangeAndIfActiveWithRepetition","CA","CE","Event";
BA_DEF_ SG_  "GenSigStartValue" INT 0 0;
BA_DEF_ BO_  "GenMsgCycleTimeFast" INT 0 0;
BA_DEF_ BO_  "GenMsgNrOfRepetition" INT 0 0;
BA_DEF_ BO_  "CANFD_BRS" ENUM  "0","1";
BA_DEF_ BO_  "VFrameFormat" ENUM  "StandardCAN","ExtendedCAN","reserved","reserved","reserved","reserved","reserved","reserved","reserved","reserved","reserved","reserved","reserved","reserved","StandardCAN_FD","ExtendedCAN_FD";
BA_DEF_ BO_  "GenMsgILSupport" ENUM  "No","Yes";
BA_DEF_DEF_  "NmMessage" "No";
BA_DEF_DEF_  "GenMsgSendType" "cyclic";
BA_DEF_DEF_  "GenMsgCycleTime" 0;
BA_DEF_DEF_  "GenSigSendType" "cyclic";
BA_DEF_DEF_  "GenSigStartValue" 0;
BA_DEF_DEF_  "GenMsgCycleTimeFast" 0;
BA_DEF_DEF_  "GenMsgNrOfRepetition" 0;
BA_DEF_DEF_  "CANFD_BRS" "1";
BA_DEF_DEF_  "VFrameFormat" "StandardCAN_FD";
BA_DEF_DEF_  "GenMsgILSupport" "Yes";
BA_ "GenMsgSendType" BO_ 763 3;
BA_ "GenMsgCycleTime" BO_ 763 100;
BA_ "GenSigSendType" SG_ 763 TBOX_FD_8_Checksum1 2;
BA_ "GenSigSendType" SG_ 763 TBOX_FD_8_RollingCounter1 2;
BA_ "GenSigSendType" SG_ 763 TBOX_V2XOutofControl_Distance 2;
BA_ "GenSigSendType" SG_ 763 TBOX_V2XOutofControl_St 2;
BA_ "GenSigSendType" SG_ 763 TBOX_V2XOutofControl_AlarmLevel 2;
BA_ "GenSigSendType" SG_ 763 TBOX_V2XOutofControl_Angle 2;
BA_ "GenSigSendType" SG_ 763 TBOX_FD_8_Checksum2 2;
BA_ "GenSigSendType" SG_ 763 TBOX_FD_8_RollingCounter2 2;
BA_ "GenSigSendType" SG_ 763 TBOX_V2XBlindSpotorLaneChangeWarn_Type 2;
BA_ "GenSigSendType" SG_ 763 TBOX_V2XBlindSpotorLaneChangeWarn_St 2;
BA_ "GenSigSendType" SG_ 763 TBOX_V2XBlindSpotorLaneChangeWarn_AlarmLevel 2;
BA_ "GenSigSendType" SG_ 763 TBOX_V2XBlindSpotorLaneChangeWarn_Distance 2;
BA_ "GenSigSendType" SG_ 763 TBOX_V2XBlindSpotorLaneChangeWarn_Direction 2;
BA_ "GenSigSendType" SG_ 763 TBOX_FD_8_Checksum3 2;
BA_ "GenSigSendType" SG_ 763 TBOX_FD_8_RollingCounter3 2;
BA_ "GenSigSendType" SG_ 763 TBOX_V2XEmergencyVehicleWarn_Distance 2;
BA_ "GenSigSendType" SG_ 763 TBOX_V2XEmergencyVehicleWarn_St 2;
BA_ "GenSigSendType" SG_ 763 TBOX_V2XEmergencyVehicleWarn_AlarmLevel 2;
BA_ "GenSigSendType" SG_ 763 TBOX_V2XEmergencyVehicleWarn_Type 2;
BA_ "GenSigSendType" SG_ 763 TBOX_V2XEmergencyVehicleWarn_Angle 2;
BA_ "GenMsgSendType" BO_ 764 3;
BA_ "GenMsgCycleTime" BO_ 764 100;
BA_ "GenSigSendType" SG_ 764 TBOX_FD_9_Checksum1 2;
BA_ "GenSigSendType" SG_ 764 TBOX_FD_9_RollingCounter1 2;
BA_ "GenSigSendType" SG_ 764 TBOX_V2XVulnerableTrafficParticipantsWarn_Distance 2;
BA_ "GenSigSendType" SG_ 764 TBOX_V2XVulnerableTrafficParticipantsWarn_St 2;
BA_ "GenSigSendType" SG_ 764 TBOX_V2XVulnerableTrafficParticipantsWarn_AlarmLevel 2;
BA_ "GenSigSendType" SG_ 764 TBOX_V2XVulnerableTrafficParticipantsWarn_Participant 2;
BA_ "GenSigSendType" SG_ 764 TBOX_V2XVulnerableTrafficParticipantsWarn_Angle 2;
BA_ "GenSigSendType" SG_ 764 TBOX_FD_9_Checksum2 2;
BA_ "GenSigSendType" SG_ 764 TBOX_FD_9_RollingCounter2 2;
BA_ "GenSigSendType" SG_ 764 TBOX_V2XInVehicleSignage_Direction 2;
BA_ "GenSigSendType" SG_ 764 TBOX_V2XInVehicleSignage_Type 2;
BA_ "GenSigSendType" SG_ 764 TBOX_V2XInVehicleSignage_Distance 2;
BA_ "GenSigSendType" SG_ 764 TBOX_V2XInVehicleSignage_St 2;
BA_ "GenSigSendType" SG_ 764 TBOX_V2XInVehicleSignage_AlarmLevel 2;
BA_ "GenSigSendType" SG_ 764 TBOX_V2XRoadHazardWarn_St 2;
BA_ "GenSigSendType" SG_ 764 TBOX_V2XRoadHazardWarn_AlarmLevel 2;
BA_ "GenSigSendType" SG_ 764 TBOX_V2XRoadHazardWarn_Distance 2;
BA_ "GenSigSendType" SG_ 764 TBOX_V2XRoadHazardWarn_Direction 2;
BA_ "GenSigSendType" SG_ 764 TBOX_V2XRoadHazardWarn_DangerTypes 2;
BA_ "GenSigSendType" SG_ 764 TBOX_FD_9_Checksum3 2;
BA_ "GenSigSendType" SG_ 764 TBOX_FD_9_RollingCounter3 2;
BA_ "GenSigSendType" SG_ 764 TBOX_V2XGreenWaveSpeedGuidance_Distance 2;
BA_ "GenSigSendType" SG_ 764 TBOX_V2XGreenWaveSpeedGuidance_Countdown 2;
BA_ "GenSigSendType" SG_ 764 TBOX_V2XGreenWaveSpeedGuidance_MinSpeed 2;
BA_ "GenSigSendType" SG_ 764 TBOX_V2XGreenWaveSpeedGuidance_MaxSpeed 2;
BA_ "GenSigSendType" SG_ 764 TBOX_V2XGreenWaveSpeedGuidance_TrafficLightPoint 2;
BA_ "GenSigSendType" SG_ 764 TBOX_V2XGreenWaveSpeedGuidance_TrafficLightSt 2;
BA_ "GenSigSendType" SG_ 764 TBOX_V2XGreenWaveSpeedGuidance_St 2;
BA_ "GenMsgSendType" BO_ 765 3;
BA_ "GenMsgCycleTime" BO_ 765 100;
BA_ "GenSigSendType" SG_ 765 TBOX_FD_10_Checksum1 2;
BA_ "GenSigSendType" SG_ 765 TBOX_FD_10_RollingCounter1 2;
BA_ "GenSigSendType" SG_ 765 TBOX_V2XRealtimeTrafficInformation_St 2;
BA_ "GenSigSendType" SG_ 765 TBOX_V2XRealtimeTrafficInformation_Direction 2;
BA_ "GenSigSendType" SG_ 765 TBOX_V2XRealtimeTrafficInformation_AlarmLevel 2;
BA_ "GenSigSendType" SG_ 765 TBOX_V2XRealtimeTrafficInformation_Distance 2;
BA_ "GenSigSendType" SG_ 765 TBOX_V2XRealtimeTrafficInformation_Type 2;
BA_ "GenSigSendType" SG_ 765 TBOX_V2XRealtimeTrafficInformation_Severity 2;
BA_ "GenSigSendType" SG_ 765 TBOX_V2XRushRedLightWarn_Distance 2;
BA_ "GenSigSendType" SG_ 765 TBOX_V2XRushRedLightWarn_St 2;
BA_ "GenSigSendType" SG_ 765 TBOX_V2XRushRedLightWarn_AlarmLevel 2;
BA_ "GenSigSendType" SG_ 765 TBOX_V2XSpeedLimitWarn_St 2;
BA_ "GenSigSendType" SG_ 765 TBOX_V2XSpeedLimitWarn_AlarmLevel 2;
BA_ "GenSigSendType" SG_ 765 TBOX_V2XSpeedLimitWarn_Speed 2;
BA_ "GenSigSendType" SG_ 765 TBOX_FD_10_Checksum2 2;
BA_ "GenSigSendType" SG_ 765 TBOX_FD_10_RollingCounter2 2;
BA_ "GenMsgCycleTime" BO_ 887 500;
BA_ "GenMsgSendType" BO_ 882 1;
BA_ "GenMsgCycleTimeFast" BO_ 882 100;
BA_ "GenMsgNrOfRepetition" BO_ 882 5;
BA_ "GenSigSendType" SG_ 882 TBOX_XCALLIDByte0 5;
BA_ "GenSigSendType" SG_ 882 TBOX_XCALLIDByte1 5;
BA_ "GenSigSendType" SG_ 882 TBOX_XCALLIDByte2 5;
BA_ "GenSigSendType" SG_ 882 TBOX_XCALLIDByte3 5;
BA_ "GenSigSendType" SG_ 882 TBOX_XCALLIDByte4 5;
BA_ "GenSigSendType" SG_ 882 TBOX_XCALLIDByte5 5;
BA_ "GenSigSendType" SG_ 882 TBOX_XCALLIDByte6 5;
BA_ "GenSigSendType" SG_ 882 TBOX_XCALLIDByte7 5;
BA_ "GenSigSendType" SG_ 882 TBOX_XCALLIDByte8 5;
BA_ "GenSigSendType" SG_ 882 TBOX_XCALLIDByte9 5;
BA_ "GenMsgCycleTime" BO_ 503 50;
BA_ "GenSigStartValue" SG_ 503 ADCM_ISA_WarningOffset_Set 2;
BA_ "GenMsgCycleTime" BO_ 505 50;
BA_ "GenMsgCycleTime" BO_ 576 100;
BA_ "GenSigStartValue" SG_ 576 ADCM_ACC_TrackTarget0_LateralPosition 512;
BA_ "GenSigStartValue" SG_ 576 ADCM_ACC_TrackTarget1_LateralPosition 512;
BA_ "GenSigStartValue" SG_ 576 ADCM_ACC_TrackTarget2_LateralPosition 512;
BA_ "GenSigStartValue" SG_ 576 ADCM_ACC_TrackTarget3_LateralPosition 512;
BA_ "GenMsgCycleTime" BO_ 578 100;
BA_ "GenSigStartValue" SG_ 578 ADCM_Line_1_A0 1023;
BA_ "GenSigStartValue" SG_ 578 ADCM_Line_1_A1 1023;
BA_ "GenSigStartValue" SG_ 578 ADCM_Line_1_A2 1023;
BA_ "GenSigStartValue" SG_ 578 ADCM_Line_1_A3 32786;
BA_ "GenSigStartValue" SG_ 578 ADCM_Line_2_A0 1023;
BA_ "GenSigStartValue" SG_ 578 ADCM_Line_2_A1 1023;
BA_ "GenSigStartValue" SG_ 578 ADCM_Line_2_A2 1023;
BA_ "GenSigStartValue" SG_ 578 ADCM_Line_2_A3 32786;
BA_ "GenMsgCycleTime" BO_ 580 100;
BA_ "GenSigStartValue" SG_ 580 ADCM_Line_3_A0 1023;
BA_ "GenSigStartValue" SG_ 580 ADCM_Line_3_A1 1023;
BA_ "GenSigStartValue" SG_ 580 ADCM_Line_3_A2 1023;
BA_ "GenSigStartValue" SG_ 580 ADCM_Line_3_A3 32786;
BA_ "GenSigStartValue" SG_ 580 ADCM_Line_4_A0 1023;
BA_ "GenSigStartValue" SG_ 580 ADCM_Line_4_A1 1023;
BA_ "GenSigStartValue" SG_ 580 ADCM_Line_4_A2 1023;
BA_ "GenSigStartValue" SG_ 580 ADCM_Line_4_A3 32786;
BA_ "GenMsgCycleTime" BO_ 582 100;
BA_ "GenMsgCycleTime" BO_ 405 20;
BA_ "GenMsgCycleTime" BO_ 584 100;
BA_ "GenMsgCycleTime" BO_ 586 100;
BA_ "GenSigStartValue" SG_ 586 APA_L1SlotEdge1LateralPosition 32767;
BA_ "GenSigStartValue" SG_ 586 APA_L1SlotEdge1LongitudinalPosition 32767;
BA_ "GenSigStartValue" SG_ 586 APA_L1SlotEdge2LateralPosition 32767;
BA_ "GenSigStartValue" SG_ 586 APA_L1SlotEdge2LongitudinalPosition 32767;
BA_ "GenSigStartValue" SG_ 586 APA_L1SlotEdge3LateralPosition_Reserved 32767;
BA_ "GenSigStartValue" SG_ 586 APA_L1SlotEdge3LongitudinalPosition_Reserved 32767;
BA_ "GenSigStartValue" SG_ 586 APA_L1SlotEdge4LateralPosition_Reserved 32767;
BA_ "GenSigStartValue" SG_ 586 APA_L1SlotEdge4LongitudinalPosition_Reserved 32767;
BA_ "GenSigStartValue" SG_ 586 APA_L2SlotEdge1LateralPosition 32767;
BA_ "GenSigStartValue" SG_ 586 APA_L2SlotEdge1LongitudinalPosition 32767;
BA_ "GenSigStartValue" SG_ 586 APA_L2SlotEdge2LateralPosition 32767;
BA_ "GenSigStartValue" SG_ 586 APA_L2SlotEdge2LongitudinalPosition 32767;
BA_ "GenSigStartValue" SG_ 586 APA_L2SlotEdge3LateralPosition_Reserved 32767;
BA_ "GenSigStartValue" SG_ 586 APA_L2SlotEdge3LongitudinalPosition_Reserved 32767;
BA_ "GenSigStartValue" SG_ 586 APA_L2SlotEdge4LateralPosition_Reserved 32767;
BA_ "GenSigStartValue" SG_ 586 APA_L2SlotEdge4LongitudinalPosition_Reserved 32767;
BA_ "GenMsgCycleTime" BO_ 588 100;
BA_ "GenSigStartValue" SG_ 588 APA_L3SlotEdge1LateralPosition 32767;
BA_ "GenSigStartValue" SG_ 588 APA_L3SlotEdge1LongitudinalPosition 32767;
BA_ "GenSigStartValue" SG_ 588 APA_L3SlotEdge2LateralPosition 32767;
BA_ "GenSigStartValue" SG_ 588 APA_L3SlotEdge2LongitudinalPosition 32767;
BA_ "GenSigStartValue" SG_ 588 APA_L3SlotEdge3LateralPosition_Reserved 32767;
BA_ "GenSigStartValue" SG_ 588 APA_L3SlotEdge3LongitudinalPosition_Reserved 32767;
BA_ "GenSigStartValue" SG_ 588 APA_L3SlotEdge4LateralPosition_Reserved 32767;
BA_ "GenSigStartValue" SG_ 588 APA_L3SlotEdge4LongitudinalPosition_Reserved 32767;
BA_ "GenSigStartValue" SG_ 588 APA_R1SlotEdge1LateralPosition 32767;
BA_ "GenSigStartValue" SG_ 588 APA_R1SlotEdge1LongitudinalPosition 32767;
BA_ "GenSigStartValue" SG_ 588 APA_R1SlotEdge2LateralPosition 32767;
BA_ "GenSigStartValue" SG_ 588 APA_R1SlotEdge2LongitudinalPosition 32767;
BA_ "GenSigStartValue" SG_ 588 APA_R1SlotEdge3LateralPosition_Reserved 32767;
BA_ "GenSigStartValue" SG_ 588 APA_R1SlotEdge3LongitudinalPosition_Reserved 32767;
BA_ "GenSigStartValue" SG_ 588 APA_R1SlotEdge4LateralPosition_Reserved 32767;
BA_ "GenSigStartValue" SG_ 588 APA_R1SlotEdge4LongitudinalPosition_Reserved 32767;
BA_ "GenMsgCycleTime" BO_ 590 100;
BA_ "GenSigStartValue" SG_ 590 APA_R2SlotEdge1LateralPosition 32767;
BA_ "GenSigStartValue" SG_ 590 APA_R2SlotEdge1LongitudinalPosition 32767;
BA_ "GenSigStartValue" SG_ 590 APA_R2SlotEdge2LateralPosition 32767;
BA_ "GenSigStartValue" SG_ 590 APA_R2SlotEdge2LongitudinalPosition 32767;
BA_ "GenSigStartValue" SG_ 590 APA_R2SlotEdge3LateralPosition_Reserved 32767;
BA_ "GenSigStartValue" SG_ 590 APA_R2SlotEdge3LongitudinalPosition_Reserved 32767;
BA_ "GenSigStartValue" SG_ 590 APA_R2SlotEdge4LateralPosition_Reserved 32767;
BA_ "GenSigStartValue" SG_ 590 APA_R2SlotEdge4LongitudinalPosition_Reserved 32767;
BA_ "GenSigStartValue" SG_ 590 APA_R3SlotEdge1LateralPosition 32767;
BA_ "GenSigStartValue" SG_ 590 APA_R3SlotEdge1LongitudinalPosition 32767;
BA_ "GenSigStartValue" SG_ 590 APA_R3SlotEdge2LateralPosition 32767;
BA_ "GenSigStartValue" SG_ 590 APA_R3SlotEdge2LongitudinalPosition 32767;
BA_ "GenSigStartValue" SG_ 590 APA_R3SlotEdge3LateralPosition_Reserved 32767;
BA_ "GenSigStartValue" SG_ 590 APA_R3SlotEdge3LongitudinalPosition_Reserved 32767;
BA_ "GenSigStartValue" SG_ 590 APA_R3SlotEdge4LateralPosition_Reserved 32767;
BA_ "GenSigStartValue" SG_ 590 APA_R3SlotEdge4LongitudinalPosition_Reserved 32767;
BA_ "GenMsgCycleTime" BO_ 596 100;
BA_ "GenSigStartValue" SG_ 596 DSM_HeadPositionX 32787;
BA_ "GenSigStartValue" SG_ 596 DSM_HeadPositionY 32787;
BA_ "GenSigStartValue" SG_ 596 DSM_HeadPositionZ 32787;
BA_ "GenSigStartValue" SG_ 596 DSM_HeadAngleX 32258;
BA_ "GenSigStartValue" SG_ 596 DSM_HeadAngleY 32258;
BA_ "GenMsgSendType" BO_ 385 3;
BA_ "GenMsgCycleTime" BO_ 385 20;
BA_ "GenSigSendType" SG_ 385 ACU_FrontCrashOutput_St 2;
BA_ "GenSigSendType" SG_ 385 ACU_DriverSideCrashOutput_St 2;
BA_ "GenSigSendType" SG_ 385 ACU_PassengerSideCrashOutput_St 2;
BA_ "GenSigSendType" SG_ 385 ACU_RearSideCrashOutput_St 2;
BA_ "GenSigStartValue" SG_ 385 ACU_WarnLampSt 1;
BA_ "GenSigStartValue" SG_ 385 ACU_PassengerAirbagSt 1;
BA_ "GenSigStartValue" SG_ 385 ACU_DriverSBR_St 1;
BA_ "GenSigStartValue" SG_ 385 ACU_PassengerSBR_St 1;
BA_ "GenSigStartValue" SG_ 385 ACU_SRLSBR_St 1;
BA_ "GenSigStartValue" SG_ 385 ACU_SRRSBR_St 1;
BA_ "GenMsgCycleTime" BO_ 386 20;
BA_ "GenSigStartValue" SG_ 386 ACU_LongitudeAcceleration 30000;
BA_ "GenSigStartValue" SG_ 386 ACU_LateralAcceleration 30000;
BA_ "GenMsgCycleTime" BO_ 417 20;
BA_ "GenSigStartValue" SG_ 417 ESC_ESCError 1;
BA_ "GenSigStartValue" SG_ 417 ESC_ABSError 1;
BA_ "GenSigStartValue" SG_ 417 ESC_EBDError 1;
BA_ "GenSigStartValue" SG_ 417 ESC_EPB_St 1;
BA_ "GenSigStartValue" SG_ 417 ESC_EPBSwitch_St 1;
BA_ "GenMsgCycleTime" BO_ 199 10;
BA_ "GenSigStartValue" SG_ 199 ESC_WorkMode 15;
BA_ "GenMsgCycleTime" BO_ 190 10;
BA_ "GenSigStartValue" SG_ 190 EB_OutputRodDriver 320;
BA_ "GenMsgCycleTime" BO_ 428 20;
BA_ "GenMsgCycleTime" BO_ 429 20;
BA_ "GenSigStartValue" SG_ 429 EPS_Failure_St 3;
BA_ "GenMsgCycleTime" BO_ 184 10;
BA_ "GenSigStartValue" SG_ 184 RWS_Travel 23000;
BA_ "GenMsgCycleTime" BO_ 425 20;
BA_ "GenSigStartValue" SG_ 425 AIRS_WorkMode 7;
BA_ "GenSigStartValue" SG_ 425 AIRS_ModeChangeEnable 1;
BA_ "GenSigStartValue" SG_ 425 AIRS_CDCWorkMode 7;
BA_ "GenSigStartValue" SG_ 425 AIRS_CDCModeChangeEnable 1;
BA_ "GenSigStartValue" SG_ 425 AIRS_EasyloadAvailability 1;
BA_ "GenSigStartValue" SG_ 425 AIRS_VehicleSpeedDependentLevelSwitchAvaliability 1;
BA_ "GenSigStartValue" SG_ 425 AIRS_LiftModeAvailability 1;
BA_ "GenSigStartValue" SG_ 425 AirS_OffRoadAvaliability 1;
BA_ "GenSigStartValue" SG_ 425 AIRS_TargetHeightIndication 7;
BA_ "GenSigStartValue" SG_ 425 AIRS_Height_FL 127;
BA_ "GenSigStartValue" SG_ 425 AIRS_Height_FR 127;
BA_ "GenSigStartValue" SG_ 425 AIRS_Height_RL 127;
BA_ "GenSigStartValue" SG_ 425 AIRS_Height_RR 127;
VAL_ 763 TBOX_V2XOutofControl_Distance 255 "Invalid" ;
VAL_ 763 TBOX_V2XOutofControl_St 3 "Reserved" 2 "Yes" 1 "No" 0 "No Command" ;
VAL_ 763 TBOX_V2XOutofControl_AlarmLevel 3 "Imminent" 2 "Advisory" 1 "Inform" 0 "No Command" ;
VAL_ 763 TBOX_V2XOutofControl_Angle 1023 "Invalid" ;
VAL_ 763 TBOX_V2XBlindSpotorLaneChangeWarn_Type 15 "Reserved" 14 "Reserved" 13 "Reserved" 12 "Reserved" 11 "Reserved" 10 "Reserved" 9 "Reserved" 8 "Reserved" 7 "Reserved" 6 "Reserved" 5 "Reserved" 4 "Reserved" 3 "Reserved" 2 "Lane Change Warning" 1 "Blind Spot Warning" 0 "No Command" ;
VAL_ 763 TBOX_V2XBlindSpotorLaneChangeWarn_St 3 "Reserved" 2 "Yes" 1 "No" 0 "No Command" ;
VAL_ 763 TBOX_V2XBlindSpotorLaneChangeWarn_AlarmLevel 3 "Imminent" 2 "Advisory" 1 "Inform" 0 "No Command" ;
VAL_ 763 TBOX_V2XBlindSpotorLaneChangeWarn_Distance 255 "Invalid" ;
VAL_ 763 TBOX_V2XBlindSpotorLaneChangeWarn_Direction 15 "Reserved" 14 "Reserved" 13 "Reserved" 12 "Reserved" 11 "Reserved" 10 "Reserved" 9 "Reserved" 8 "Reserved" 7 "Reserved" 6 "Reserved" 5 "Reserved" 4 "Far Rear Right" 3 "Far Rear Left" 2 "Near Rear Right" 1 "Near Rear Left" 0 "No Command" ;
VAL_ 763 TBOX_V2XEmergencyVehicleWarn_Distance 255 "Invalid" ;
VAL_ 763 TBOX_V2XEmergencyVehicleWarn_St 3 "Reserved" 2 "Yes" 1 "No" 0 "No Command" ;
VAL_ 763 TBOX_V2XEmergencyVehicleWarn_AlarmLevel 3 "Imminent" 2 "Advisory" 1 "Inform" 0 "No Command" ;
VAL_ 763 TBOX_V2XEmergencyVehicleWarn_Type 7 "Invalid" 6 "Reserved" 5 "Reserved" 4 "School Bus" 3 "Police Car" 2 "Ambulance" 1 "Fire vehicle" 0 "No Command" ;
VAL_ 763 TBOX_V2XEmergencyVehicleWarn_Angle 1023 "Invalid" ;
VAL_ 764 TBOX_V2XVulnerableTrafficParticipantsWarn_Distance 255 "Invalid" ;
VAL_ 764 TBOX_V2XVulnerableTrafficParticipantsWarn_St 3 "Reserved" 2 "Yes" 1 "No" 0 "No Command" ;
VAL_ 764 TBOX_V2XVulnerableTrafficParticipantsWarn_AlarmLevel 3 "Imminent" 2 "Advisory" 1 "Inform" 0 "No Command" ;
VAL_ 764 TBOX_V2XVulnerableTrafficParticipantsWarn_Participant 7 "Invalid" 6 "Reserved" 5 "Reserved" 4 "Reserved" 3 "Reserved" 2 "Non-motorized" 1 "Pedestrian" 0 "No Command" ;
VAL_ 764 TBOX_V2XVulnerableTrafficParticipantsWarn_Angle 1023 "Invalid" ;
VAL_ 764 TBOX_V2XInVehicleSignage_Direction 15 "Reserved" 14 "Reserved" 13 "Reserved" 12 "Reserved" 11 "Reserved" 10 "Reserved" 9 "Reserved" 8 "Reserved" 7 "Reserved" 6 "Reserved" 5 "Reserved" 4 "Reserved" 3 "Reserved" 2 "Reserved" 1 "Front" 0 "No Command" ;
VAL_ 764 TBOX_V2XInVehicleSignage_Type 15 "Reserved" 14 "Reserved" 13 "Reserved" 12 "Reserved" 11 "Reserved" 10 "Reserved" 9 "Reserved" 8 "Reserved" 7 "Reserved" 6 "Reserved" 5 "Reserved" 4 "Reserved" 3 "Reserved" 2 "Road Narrows" 1 "Construction Signage" 0 "No Command" ;
VAL_ 764 TBOX_V2XInVehicleSignage_Distance 255 "Invalid" ;
VAL_ 764 TBOX_V2XInVehicleSignage_St 3 "Reserved" 2 "Yes" 1 "No" 0 "No Command" ;
VAL_ 764 TBOX_V2XInVehicleSignage_AlarmLevel 3 "Imminent" 2 "Advisory" 1 "Inform" 0 "No Command" ;
VAL_ 764 TBOX_V2XRoadHazardWarn_St 3 "Reserved" 2 "Yes" 1 "No" 0 "No Command" ;
VAL_ 764 TBOX_V2XRoadHazardWarn_AlarmLevel 3 "Imminent" 2 "Advisory" 1 "Inform" 0 "No Command" ;
VAL_ 764 TBOX_V2XRoadHazardWarn_Distance 255 "Invalid" ;
VAL_ 764 TBOX_V2XRoadHazardWarn_Direction 15 "Reserved" 14 "Reserved" 13 "Reserved" 12 "Reserved" 11 "Reserved" 10 "Reserved" 9 "Reserved" 8 "Reserved" 7 "Reserved" 6 "Reserved" 5 "Reserved" 4 "Reserved" 3 "Front Right" 2 "Front Left" 1 "Front" 0 "No Command" ;
VAL_ 764 TBOX_V2XRoadHazardWarn_DangerTypes 15 "Reserved" 14 "Reserved" 13 "Reserved" 12 "Reserved" 11 "Reserved" 10 "Reserved" 9 "Reserved" 8 "Reserved" 7 "Reserved" 6 "Reserved" 5 "Rockfall" 4 "Slippery Roads" 3 "Deep Pits" 2 "Deep Water" 1 "Sharp Turn" 0 "No Command" ;
VAL_ 764 TBOX_V2XGreenWaveSpeedGuidance_Distance 255 "Invalid" ;
VAL_ 764 TBOX_V2XGreenWaveSpeedGuidance_Countdown 255 "Invalid" ;
VAL_ 764 TBOX_V2XGreenWaveSpeedGuidance_MinSpeed 255 "Invalid" ;
VAL_ 764 TBOX_V2XGreenWaveSpeedGuidance_MaxSpeed 255 "Invalid" ;
VAL_ 764 TBOX_V2XGreenWaveSpeedGuidance_TrafficLightPoint 15 "Reserved" 14 "Reserved" 13 "Reserved" 12 "Reserved" 11 "Reserved" 10 "Reserved" 9 "Reserved" 8 "Reserved" 7 "Reserved" 6 "Reserved" 5 "Reserved" 4 "Turn Around" 3 "Turn Right" 2 "Go Straight" 1 "Turn Left" 0 "No Command" ;
VAL_ 764 TBOX_V2XGreenWaveSpeedGuidance_TrafficLightSt 7 "Invalid" 6 "Reserved" 5 "Reserved" 4 "Error" 3 "Yellow" 2 "Green" 1 "Red" 0 "No Command" ;
VAL_ 764 TBOX_V2XGreenWaveSpeedGuidance_St 3 "Reserved" 2 "Yes" 1 "No" 0 "No Command" ;
VAL_ 765 TBOX_V2XRealtimeTrafficInformation_St 3 "Reserved" 2 "Yes" 1 "No" 0 "No Command" ;
VAL_ 765 TBOX_V2XRealtimeTrafficInformation_Direction 15 "Reserved" 14 "Reserved" 13 "Reserved" 12 "Reserved" 11 "Reserved" 10 "Reserved" 9 "Reserved" 8 "Reserved" 7 "Reserved" 6 "Reserved" 5 "Reserved" 4 "Reserved" 3 "Reserved" 2 "Reserved" 1 "Front" 0 "No Command" ;
VAL_ 765 TBOX_V2XRealtimeTrafficInformation_AlarmLevel 3 "Imminent" 2 "Advisory" 1 "Inform" 0 "No Command" ;
VAL_ 765 TBOX_V2XRealtimeTrafficInformation_Distance 255 "Invalid" ;
VAL_ 765 TBOX_V2XRealtimeTrafficInformation_Type 15 "Reserved" 14 "Reserved" 13 "Reserved" 12 "Reserved" 11 "Reserved" 10 "Reserved" 9 "Reserved" 8 "Reserved" 7 "Reserved" 6 "Reserved" 5 "Reserved" 4 "Reserved" 3 "Accident" 2 "Road Congestion" 1 "Smooth Traffic" 0 "No Command" ;
VAL_ 765 TBOX_V2XRealtimeTrafficInformation_Severity 15 "Reserved" 14 "Reserved" 13 "Reserved" 12 "Reserved" 11 "Reserved" 10 "Reserved" 9 "Reserved" 8 "Reserved" 7 "Reserved" 6 "Reserved" 5 "Reserved" 4 "Serious" 3 "Moderate" 2 "Mild" 1 "Smooth Traffic" 0 "No Command" ;
VAL_ 765 TBOX_V2XRushRedLightWarn_Distance 255 "Invalid" ;
VAL_ 765 TBOX_V2XRushRedLightWarn_St 3 "Reserved" 2 "Yes" 1 "No" 0 "No Command" ;
VAL_ 765 TBOX_V2XRushRedLightWarn_AlarmLevel 3 "Imminent" 2 "Advisory" 1 "Inform" 0 "No Command" ;
VAL_ 765 TBOX_V2XSpeedLimitWarn_St 3 "Reserved" 2 "Yes" 1 "No" 0 "No Command" ;
VAL_ 765 TBOX_V2XSpeedLimitWarn_AlarmLevel 3 "Imminent" 2 "Advisory" 1 "Inform" 0 "No Command" ;
VAL_ 765 TBOX_V2XSpeedLimitWarn_Speed 255 "Invalid" ;
VAL_ 765 TBOX_V2X_St 3 "Reserved" 2 "Reserved" 1 "Enable" 0 "Disable" ;
VAL_ 503 ADCM_LKS_TakeoverReq 1 "Active" 0 "Inactive" ;
VAL_ 503 ADCM_LKS_St 7 "Reserved" 6 "Reserved" 5 "Reserved" 4 "LKS failure" 3 "LKS active" 2 "LKS standby" 1 "LKS initial" 0 "LKS Off" ;
VAL_ 503 ADCM_LKS_Type_Set 3 "Steering and Warning" 2 "Warning" 1 "Steering" 0 "Not selected" ;
VAL_ 503 ADCM_LKS_Left_Active_St 7 "Reserved" 6 "Reserved" 5 "LKS_Freezed" 4 "LKS_Suppressed" 3 "LKS_Intervening" 2 "LKS_Warning" 1 "Lane_Tracking" 0 "Inactive" ;
VAL_ 503 ADCM_LKS_Right_Active_St 7 "Reserved" 6 "Reserved" 5 "LKS_Freezed" 4 "LKS_Suppressed" 3 "LKS_Intervening" 2 "LKS_Warning" 1 "Lane_Tracking" 0 "Inactive" ;
VAL_ 503 ADCM_LKS_Sensitivity_Set 3 "High" 2 "Middle" 1 "Low" 0 "Reserved" ;
VAL_ 503 ADCM_ELK_St 7 "Reserved" 6 "Reserved" 5 "Reserved" 4 "ELK failure" 3 "ELK active" 2 "ELK standby" 1 "ELK Initial" 0 "ELK Off" ;
VAL_ 503 ADCM_ELK_Left_Active_St 7 "Reserved" 6 "Reserved" 5 "ELK_Freezed" 4 "ELK_Suppressed" 3 "ELK_Overtaking" 2 "ELK_Oncoming" 1 "ELK_Road_Edge" 0 "Inctive" ;
VAL_ 503 ADCM_ELK_Right_Active_St 7 "Reserved" 6 "Reserved" 5 "ELK_Freezed" 4 "ELK_Suppressed" 3 "ELK_Overtaking" 2 "ELK_Oncoming" 1 "ELK_Road_Edge" 0 "Inctive" ;
VAL_ 503 ADCM_RCW_St 7 "Reserved" 6 "Reserved" 5 "Reserved" 4 "Failure" 3 "Active" 2 "Standby" 1 "Initial" 0 "OFF" ;
VAL_ 503 ADCM_RCW_Warn_St 3 "Reserved" 2 "LV2 Warning" 1 "LV1 Warning" 0 "No warning" ;
VAL_ 503 ADCM_LCA_St 7 "Reserved" 6 "Reserved" 5 "Reserved" 4 "Failure" 3 "Active" 2 "Standby" 1 "Initial" 0 "OFF" ;
VAL_ 503 ADCM_LCA_Right_Warn_St 3 "Reserved" 2 "LV2 Warning" 1 "LV1 Warning" 0 "No warning" ;
VAL_ 503 ADCM_LCA_Left_Warn_St 3 "Reserved" 2 "LV2 Warning" 1 "LV1 Warning" 0 "No warning" ;
VAL_ 503 ADCM_RCTA_St 7 "Reserved" 6 "Reserved" 5 "Reserved" 4 "Failure" 3 "Active" 2 "Standby" 1 "Initial" 0 "OFF" ;
VAL_ 503 ADCM_RCTA_Right_Warn_St 3 "Reserved" 2 "LV2 Warning" 1 "LV1 Warning" 0 "No warning" ;
VAL_ 503 ADCM_RCTA_Left_Warn_St 3 "Reserved" 2 "LV2 Warning" 1 "LV1 Warning" 0 "No warning" ;
VAL_ 503 ADCM_AHB_St 7 "Reserved" 6 "Reserved" 5 "Reserved" 4 "Failure" 3 "Active" 2 "Standby" 1 "Initial" 0 "OFF" ;
VAL_ 503 ADCM_AHB_Ctrl_St 3 "Invalid" 2 "High_Beam" 1 "Low_Beam" 0 "Inactive" ;
VAL_ 503 ADCM_ACC_UnavailableReason 15 "Reserved" 14 "Reserved" 13 "Reserved" 12 "Reserved" 11 "Reserved" 10 "Reserved" 9 "Reserved" 8 "Other reason" 7 "Trailer present(Reserved)" 6 "EPB applied" 5 "Incompatible Drive Mode Selected" 4 "Gear not in D" 3 "Door open" 2 "Driver seatbelt unbuckled" 1 "High speed" 0 "No display" ;
VAL_ 503 ADCM_ACC_St 7 "Failure" 6 "Standstill" 5 "Override" 4 "Brake only" 3 "Active control" 2 "Standby" 1 "Passive" 0 "Off" ;
VAL_ 503 ADCM_ACC_Warn_St 7 "Reserved" 6 "Reserved" 5 "Reserved" 4 "Reserved" 3 "Take over warning" 2 "Unable to active" 1 "Cancel Warning" 0 "No warning" ;
VAL_ 503 ADCM_ACC_TimeGap 3 "Reserved" 2 "TimeGap3" 1 "TimeGap2" 0 "TimeGap1" ;
VAL_ 503 ADCM_ACC_TargetSpeed 127 "Invalid" ;
VAL_ 503 ADCM_ACC_GoNotifier 1 "Go notifier alert" 0 "No alert" ;
VAL_ 503 ADCM_ISA_St 7 "Reserved" 6 "Reserved" 5 "Reserved" 4 "Reserved" 3 "Reserved" 2 "Reserved" 1 "ON" 0 "OFF" ;
VAL_ 503 ADCM_ISA_LimitSpeed 27 "130" 26 "125" 25 "120" 24 "115" 23 "110" 22 "105" 21 "100" 20 "95" 19 "90" 18 "85" 17 "80" 16 "75" 15 "70" 14 "65" 13 "60" 12 "55" 11 "50" 10 "45" 9 "40" 8 "35" 7 "30" 6 "25" 5 "20" 4 "15" 3 "10" 2 "5" 1 "Cancelled" 0 "No display" ;
VAL_ 503 ADCM_ISA_Operating_St 7 "Reserved" 6 "Reserved" 5 "Reserved" 4 "TSR failure" 3 "Navigation only mode" 2 "Vision only mode" 1 "Fusion mode" 0 "Off" ;
VAL_ 503 ADCM_ISA_Warn_St 1 "warning" 0 "No warning" ;
VAL_ 503 ADCM_ISA_SpeedLimitype 3 "Reserved" 2 "Interval speed detection" 1 "Camera detection" 0 "Not specific" ;
VAL_ 503 ADCM_ISA_SpeedLimitUnit 3 "Reserved" 2 "Miles/h" 1 "km/h" 0 "Unknown" ;
VAL_ 503 ADCM_ISA_WarningOffset_Set 7 "Reserved" 6 "Reserved" 5 "Reserved" 4 "+10" 3 "+5" 2 "0" 1 "-5" 0 "-10" ;
VAL_ 503 ADCM_ValetMode_AccDisable_St 3 "Reserved" 2 "Reserved" 1 "Enable ACC" 0 "Disable ACC" ;
VAL_ 503 ADCM_FCS_TargetType 15 "Reserved" 14 "Reserved" 13 "Reserved" 12 "Reserved" 11 "Reserved" 10 "Reserved" 9 "Reserved" 8 "Reserved" 7 "Motorbike(TBD)" 6 "Bus(TBD)" 5 "Unknown" 4 "Trunk" 3 "Cyclist" 2 "Pedestrian" 1 "Car" 0 "No display" ;
VAL_ 503 ADCM_FCS_St 7 "Reserved" 6 "Reserved" 5 "Reserved" 4 "Failure" 3 "Active" 2 "Standby" 1 "Initial" 0 "OFF" ;
VAL_ 503 ADCM_FCS_Active_St 7 "Reserved" 6 "Reserved" 5 "FCS_Freezed" 4 "FCS_Suppressed" 3 "FCS_Braking" 2 "FCS_LV2_Warning" 1 "FCS_LV1_Warning" 0 "Inactive" ;
VAL_ 503 ADCM_FCTA_Left_TargetType 15 "Reserved" 14 "Reserved" 13 "Reserved" 12 "Reserved" 11 "Reserved" 10 "Reserved" 9 "Reserved" 8 "Reserved" 7 "Motorbike(TBD)" 6 "Bus(TBD)" 5 "Unknown" 4 "Trunk" 3 "Cyclist（TBD）" 2 "Pedestrian（TBD）" 1 "Car" 0 "No display" ;
VAL_ 503 ADCM_FCTA_Right_TargetType 15 "Reserved" 14 "Reserved" 13 "Reserved" 12 "Reserved" 11 "Reserved" 10 "Reserved" 9 "Reserved" 8 "Reserved" 7 "Motorbike(TBD)" 6 "Bus(TBD)" 5 "Unknown" 4 "Trunk" 3 "Cyclist（TBD）" 2 "Pedestrian（TBD）" 1 "Car" 0 "No display" ;
VAL_ 503 ADCM_FCTA_Left_Active_St 7 "Reserved" 6 "Reserved" 5 "FCTA_Freezed" 4 "FCTA_Suppressed" 3 "FCTA_Braking" 2 "FCTA_LV2_Warning" 1 "FCTA_LV1_Warning" 0 "Inactive" ;
VAL_ 503 ADCM_FCTA_Right_Active_St 7 "Reserved" 6 "Reserved" 5 "FCTA_Freezed" 4 "FCTA_Suppressed" 3 "FCTA_Braking" 2 "FCTA_LV2_Warning" 1 "FCTA_LV1_Warning" 0 "Inactive" ;
VAL_ 503 ADCM_FCTA_St 7 "Reserved" 6 "Reserved" 5 "Reserved" 4 "Failure" 3 "Active" 2 "Standby" 1 "Initial" 0 "OFF" ;
VAL_ 503 ADCM_DetecCloseObjectFunctionRsp 3 "Reserved" 2 "Reserved" 1 "Enable" 0 "Disable" ;
VAL_ 503 ADCM_DOW_St 7 "Reserved" 6 "Reserved" 5 "Reserved" 4 "Failure" 3 "Active" 2 "Standby" 1 "Initial" 0 "OFF" ;
VAL_ 503 ADCM_DOW_FL_Warn_St 3 "Reserved" 2 "LV2 Warning" 1 "LV1 Warning" 0 "No warning" ;
VAL_ 503 ADCM_DOW_RL_Warn_St 3 "Reserved" 2 "LV2 Warning" 1 "LV1 Warning" 0 "No warning" ;
VAL_ 503 ADCM_DOW_FR_Warn_St 3 "Reserved" 2 "LV2 Warning" 1 "LV1 Warning" 0 "No warning" ;
VAL_ 503 ADCM_DOW_RR_Warn_St 3 "Reserved" 2 "LV2 Warning" 1 "LV1 Warning" 0 "No warning" ;
VAL_ 503 ADCM_FRCloseObjectWarn 3 "Reserved" 2 "Reserved" 1 "Warning" 0 "No Warning" ;
VAL_ 503 ADCM_RLCloseObjectWarn 3 "Reserved" 2 "Reserved" 1 "Warning" 0 "No Warning" ;
VAL_ 503 ADCM_RRCloseObjectWarn 3 "Reserved" 2 "Reserved" 1 "Warning" 0 "No Warning" ;
VAL_ 503 ADCM_FLCloseObjectWarn 3 "Reserved" 2 "Reserved" 1 "Warning" 0 "No Warning" ;
VAL_ 505 ADCM_Pilot_Warn_St 15 "Reserved" 14 "Reserved" 13 "Reserved" 12 "Reserved" 11 "Reserved" 10 "Reserved" 9 "Reserved" 8 "Reserved" 7 "Reserved" 6 "Override warning" 5 "Safe stop warning" 4 "Take over warning" 3 "Attention Warning" 2 "Unable to active" 1 "Cancel Warning" 0 "No warning" ;
VAL_ 505 ADCM_Pilot_Type 7 "Reserved" 6 "Reserved" 5 "Reserved" 4 "Reserved" 3 "Reserved" 2 "TJP" 1 "HWA" 0 "Inactive" ;
VAL_ 505 ADCM_Pilot_Available_St 7 "Reserved" 6 "Reserved" 5 "Reserved" 4 "Reserved" 3 "Reserved" 2 "TJP Available" 1 "HWA Available" 0 "Not Available" ;
VAL_ 505 ADCM_PilotLateral_St 7 "Reserved" 6 "Reserved" 5 "Reserved" 4 "Failure" 3 "Override" 2 "Active" 1 "Standby" 0 "Off" ;
VAL_ 505 ADCM_HWA_ILC_Left_St 15 "Reserved" 14 "Reserved" 13 "Reserved" 12 "Reserved" 11 "Reserved" 10 "Reserved" 9 "Reserved" 8 "Failure" 7 "Reserved" 6 "Abort" 5 "Lane Changed" 4 "Lane Changing" 3 "Wait" 2 "Enabled" 1 "Inhibited" 0 "Off" ;
VAL_ 505 ADCM_HWA_ILC_Right_St 15 "Reserved" 14 "Reserved" 13 "Reserved" 12 "Reserved" 11 "Reserved" 10 "Reserved" 9 "Reserved" 8 "Failure" 7 "Reserved" 6 "Abort" 5 "Lane Changed" 4 "Lane Changing" 3 "Wait" 2 "Enabled" 1 "Inhibited" 0 "Off" ;
VAL_ 505 ADCM_HWA_ILC_Set 3 "Reserved" 2 "On" 1 "Off" 0 "Reserved" ;
VAL_ 505 ADCM_HWA_ILC_TurnLampReq 3 "Reserved" 2 "Right request on" 1 "Left request on" 0 "No request" ;
VAL_ 505 ADCM_HWA_ILC_AbortReason 15 "Others" 14 "Reserved" 13 "Unable to active" 12 "System fail" 11 "TJA/ICA not working" 10 "Exceed wait working" 9 "Driver turn ILC off" 8 "Driver turn on hazard lamp" 7 "Driver pull off indicator" 6 "Driver override steering wheel" 5 "Speed over range" 4 "Target lane block" 3 "Road curvature over range" 2 "Outter line not detected" 1 "Inner line interrupt" 0 "No abort" ;
VAL_ 505 ADCM_HWA_ILC_Left_Warn 1 "Warning" 0 "No Warning" ;
VAL_ 505 ADCM_HWA_ILC_Right_Warn 1 "Warning" 0 "No Warning" ;
VAL_ 505 ADCM_HWA_ILC_HandsonReq 1 "Warning" 0 "No Warning" ;
VAL_ 576 ADCM_ACC_TrackTarget0_LateralPosition 1023 "Invalid" ;
VAL_ 576 ADCM_ACC_TrackTarget0_ObjectType 15 "Reserved" 14 "Reserved" 13 "Reserved" 12 "Reserved" 11 "Reserved" 10 "Undentified vehicle(TBD)" 9 "Bicycle" 8 "General on-borad object (TBD)" 7 "Animal(TBD)" 6 "Tree(TBD)" 5 "Pole(TBD)" 4 "Pedestrian" 3 "Truck" 2 "Motorcycle" 1 "Car" 0 "Under detemined" ;
VAL_ 576 ADCM_ACC_TrackTarget0_St 1 "Dectected" 0 "Not dectected" ;
VAL_ 576 ADCM_ACC_TrackTarget0_LongitudinalPosition 255 "Invalid" ;
VAL_ 576 ADCM_ACC_TrackTarget1_LateralPosition 1023 "Invalid" ;
VAL_ 576 ADCM_ACC_TrackTarget1_ObjectType 15 "Reserved" 14 "Reserved" 13 "Reserved" 12 "Reserved" 11 "Reserved" 10 "Undentified vehicle(TBD)" 9 "Bicycle" 8 "General on-borad object (TBD)" 7 "Animal(TBD)" 6 "Tree(TBD)" 5 "Pole(TBD)" 4 "Pedestrian" 3 "Truck" 2 "Motorcycle" 1 "Car" 0 "Under detemined" ;
VAL_ 576 ADCM_ACC_TrackTarget1_St 1 "Dectected" 0 "Not dectected" ;
VAL_ 576 ADCM_ACC_TrackTarget1_LongitudinalPosition 255 "Invalid" ;
VAL_ 576 ADCM_ACC_TrackTarget2_LateralPosition 1023 "Invalid" ;
VAL_ 576 ADCM_ACC_TrackTarget2_ObjectType 15 "Reserved" 14 "Reserved" 13 "Reserved" 12 "Reserved" 11 "Reserved" 10 "Undentified vehicle(TBD)" 9 "Bicycle" 8 "General on-borad object (TBD)" 7 "Animal(TBD)" 6 "Tree(TBD)" 5 "Pole(TBD)" 4 "Pedestrian" 3 "Truck" 2 "Motorcycle" 1 "Car" 0 "Under detemined" ;
VAL_ 576 ADCM_ACC_TrackTarget2_St 1 "Dectected" 0 "Not dectected" ;
VAL_ 576 ADCM_ACC_TrackTarget2_LongitudinalPosition 255 "Invalid" ;
VAL_ 576 ADCM_ACC_TrackTarget3_LateralPosition 1023 "Invalid" ;
VAL_ 576 ADCM_ACC_TrackTarget3_ObjectType 15 "Reserved" 14 "Reserved" 13 "Reserved" 12 "Reserved" 11 "Reserved" 10 "Undentified vehicle(TBD)" 9 "Bicycle" 8 "General on-borad object (TBD)" 7 "Animal(TBD)" 6 "Tree(TBD)" 5 "Pole(TBD)" 4 "Pedestrian" 3 "Truck" 2 "Motorcycle" 1 "Car" 0 "Under detemined" ;
VAL_ 576 ADCM_ACC_TrackTarget3_St 1 "Dectected" 0 "Not dectected" ;
VAL_ 576 ADCM_ACC_TrackTarget3_LongitudinalPosition 255 "Invalid" ;
VAL_ 578 ADCM_Line_1_Display 3 "Warning" 2 "Intervening" 1 "Tracking" 0 "No display" ;
VAL_ 578 ADCM_Line_1_Type 15 "Reserved" 14 "Reserved" 13 "Reserved" 12 "Reserved" 11 "Invalid" 10 "DECEL" 9 "Parking cars" 8 "Cones, poles" 7 "Curb" 6 "Barrier" 5 "Botts" 4 "DLM" 3 "Road edge" 2 "Undecided" 1 "Solid" 0 "Dashed" ;
VAL_ 578 ADCM_Line_1_A0 2047 "Invalid" ;
VAL_ 578 ADCM_Line_1_A1 2047 "Invalid" ;
VAL_ 578 ADCM_Line_1_A2 2047 "Invalid" ;
VAL_ 578 ADCM_Line_2_Display 3 "Warning" 2 "Intervening" 1 "Tracking" 0 "No display" ;
VAL_ 578 ADCM_Line_2_Type 15 "Reserved" 14 "Reserved" 13 "Reserved" 12 "Reserved" 11 "Invalid" 10 "DECEL" 9 "Parking cars" 8 "Cones, poles" 7 "Curb" 6 "Barrier" 5 "Botts" 4 "DLM" 3 "Road edge" 2 "Undecided" 1 "Solid" 0 "Dashed" ;
VAL_ 578 ADCM_Line_2_A0 2047 "Invalid" ;
VAL_ 578 ADCM_Line_2_A1 2047 "Invalid" ;
VAL_ 578 ADCM_Line_2_A2 2047 "Invalid" ;
VAL_ 580 ADCM_Line_3_Display 3 "Reserved" 2 "Reserved" 1 "Display" 0 "No display" ;
VAL_ 580 ADCM_Line_3_Type 15 "Reserved" 14 "Reserved" 13 "Reserved" 12 "Reserved" 11 "Invalid" 10 "DECEL" 9 "Parking cars" 8 "Cones, poles" 7 "Curb" 6 "Barrier" 5 "Botts" 4 "DLM" 3 "Road edge" 2 "Undecided" 1 "Solid" 0 "Dashed" ;
VAL_ 580 ADCM_Line_3_A0 2047 "Invalid" ;
VAL_ 580 ADCM_Line_3_A1 2047 "Invalid" ;
VAL_ 580 ADCM_Line_3_A2 2047 "Invalid" ;
VAL_ 580 ADCM_Line_4_Display 3 "Reserved" 2 "Reserved" 1 "Display" 0 "No display" ;
VAL_ 580 ADCM_Line_4_Type 15 "Reserved" 14 "Reserved" 13 "Reserved" 12 "Reserved" 11 "Invalid" 10 "DECEL" 9 "Parking cars" 8 "Cones, poles" 7 "Curb" 6 "Barrier" 5 "Botts" 4 "DLM" 3 "Road edge" 2 "Undecided" 1 "Solid" 0 "Dashed" ;
VAL_ 580 ADCM_Line_4_A0 2047 "Invalid" ;
VAL_ 580 ADCM_Line_4_A1 2047 "Invalid" ;
VAL_ 580 ADCM_Line_4_A2 2047 "Invalid" ;
VAL_ 582 ADCM_SystemSt 7 "Reserved" 6 "Reserved" 5 "Reserved" 4 "Reserved" 3 "Reserved" 2 "Reserved" 1 "Failure" 0 "Normal" ;
VAL_ 582 ADCM_FMRRSensorBloc_St 1 "Blocked" 0 "Not Blocked" ;
VAL_ 582 ADCM_FCamSensorBloc_St 1 "Blocked" 0 "Not Blocked" ;
VAL_ 582 ADCM_ReserveSensorBloc_St 1 "Blocked" 0 "Not Blocked" ;
VAL_ 582 ADCM_LFSRRSensorBloc_St 1 "Blocked" 0 "Not Blocked" ;
VAL_ 582 ADCM_LRSRRSensorBloc_St 1 "Blocked" 0 "Not Blocked" ;
VAL_ 582 ADCM_RRSRRSensorBloc_St 1 "Blocked" 0 "Not Blocked" ;
VAL_ 582 ADCM_RFSRRSensorBloc_St 1 "Blocked" 0 "Not Blocked" ;
VAL_ 582 ADCM_FMRRSensorCali_St 1 "Calibration Failed" 0 "Calibration Success" ;
VAL_ 582 ADCM_FCamSensorCali_St 1 "Calibration Failed" 0 "Calibration Success" ;
VAL_ 582 ADCM_ReserveSensorCali_St 1 "Calibration Failed" 0 "Calibration Success" ;
VAL_ 582 ADCM_LFSRRSensorCali_St 1 "Calibration Failed" 0 "Calibration Success" ;
VAL_ 582 ADCM_LRSRRSensorCali_St 1 "Calibration Failed" 0 "Calibration Success" ;
VAL_ 582 ADCM_RRSRRSensorCali_St 1 "Calibration Failed" 0 "Calibration Success" ;
VAL_ 582 ADCM_RFSRRSensorCali_St 1 "Calibration Failed" 0 "Calibration Success" ;
VAL_ 582 ADCM_FMRRSensorFail_St 1 "Failure" 0 "No Failure" ;
VAL_ 582 ADCM_FCamSensorFail_St 1 "Failure" 0 "No Failure" ;
VAL_ 582 ADCM_ReserveSensorFail_St 1 "Failure" 0 "No Failure" ;
VAL_ 582 ADCM_LFSRRSensorFail_St 1 "Failure" 0 "No Failure" ;
VAL_ 582 ADCM_LRSRRSensorFail_St 1 "Failure" 0 "No Failure" ;
VAL_ 582 ADCM_RRSRRSensorFail_St 1 "Failure" 0 "No Failure" ;
VAL_ 582 ADCM_RFSRRSensorFail_St 1 "Failure" 0 "No Failure" ;
VAL_ 405 APA_ParkingState 15 "Reserved" 14 "Reserved" 13 "Reserved" 12 "Reserved" 11 "Reserved" 10 "Reserved" 9 "Reserved" 8 "Reserved" 7 "Reserved" 6 "Terminated" 5 "Failure" 4 "Completed" 3 "Guidance active" 2 "Searching" 1 "Standby" 0 "Off" ;
VAL_ 405 APA_ButtonPress_St_Reserved 3 "Reserved" 2 "Reserved" 1 "Pressed" 0 "No pressed" ;
VAL_ 405 APA_QuitReason_Ind 63 "Resrerved" 62 "Resrerved" 61 "Resrerved" 60 "Resrerved" 59 "Resrerved" 58 "Resrerved" 57 "Resrerved" 56 "Resrerved" 55 "Resrerved" 54 "Resrerved" 53 "Resrerved" 52 "Resrerved" 51 "Resrerved" 50 "Resrerved" 49 "Resrerved" 48 "Resrerved" 47 "Resrerved" 46 "Resrerved" 45 "Resrerved" 44 "Resrerved" 43 "Resrerved" 42 "Resrerved" 41 "Resrerved" 40 "Resrerved" 39 "Req_Quit_RWS_Failure" 38 "Req_Quit_Outside rear view mirror fold" 37 "Req_Quit_Remote device in the car" 36 "Req_Quit_Slope out of limit" 35 "Req_Quit_Engine Front Door" 34 "Req_Quit_FCW_and_AEB" 33 "Req_Quit_HWA" 32 "Req_Quit_Surround View" 31 "Req_Quit_Remote_Key Reason" 30 "Req_Quit_Door_Lock" 29 "Req_Quit_Remote Device Reason" 28 "Req_Quit_TBOX_Reason" 27 "Req_Quit_Unsafe_Behavior" 26 "Req_Quit_Phone_LowBattey" 25 "Req_Quit_Phone_Disconnected" 24 "Req_Quit_EPS failure(Reserved)" 23 "Req_Quit_ESP failure(Reserved)" 22 "Req_Quit_VDCM failure(Reserved)" 21 "Req_Quit_External ECU failure" 20 "Req_Quit_PAS_Failure" 19 "Req_Quit_Steering Wheel Intervention" 18 "Req_Quit_External ECU actvie" 17 "Req_Quit_Vehicle Block" 16 "Req_Quit_EPB_Apply(Reserved)" 15 "Req_Quit_Gear Interrupt (wrong gear position)" 14 "Req_Quit_Gear Intervention(driver intervention)(APA)" 13 "Req_Quit_Terminate_Button_Pressed(HMI Cancel or device cancel)" 12 "Req_Quit_Luggage Door Open" 11 "Req_Quit_Driver_Door Open(all Doors)" 10 "Req_Quit_Seat belt unbuckle（APA）" 9 "Req_Quit_TJA" 8 "Req_Quit_ACC" 7 "Req_Quit_Gas pedal" 6 "Req_Quit_Speed high" 5 "Req_Quit_Space limit" 4 "Req_Quit_Trajectory" 3 "Req_Quit_Recover_Interrupt_Times_Overflow" 2 "Req_Quit_Move times overflow" 1 "Req_Quit_Timing overflow" 0 "No Request" ;
VAL_ 405 APA_Recover_Ind 7 "Reserved" 6 "Reserved" 5 "Key out of range" 4 "Phone out of range" 3 "Req_Recover_Found Obstacle In Trajectory" 2 "Req_Recover_Door_Closed (all doors)" 1 "Req_Recover_Press_Interrupt Device Switch" 0 "No Request" ;
VAL_ 405 APA_DriverOperate_Ind 31 "Reserved" 30 "Req_RWS_Keep center" 29 "Req_Open_outside rear view Mirror" 28 "Req_Remote_device_normal range" 27 "Req_Phone_lowbattery" 26 "Req_EPB_Inactive" 25 "Req_Gear_R_N_D(Req_Exit Park signal)" 24 "Req_APA" 22 "Req_POC Direction Select(Reserved)" 21 "Req_Function off（泊车系统关闭）" 20 "Req_Process bar" 19 "Req_Release Brake" 18 "Req_Confirm_Press DM Switch (触发握手 guidance)" 17 "Req_Press Brake Pedal" 16 "Req_Surround_View" 15 "Req_Buckle Seat Belt（请求扣上安全带）" 14 "Req_Close Door (all doors)（请求关上所有车门）" 13 "Req_Close Engine Front Door(Reserved)" 12 "Req_Close Trunk(请求关闭后备箱)" 11 "Req_Leave_Car" 10 "Req EPB_Applied(Req_Gear P and EPB Applied)" 9 "Req_Connect_Phone" 8 "Req_Function Select for A/RPA" 7 "Req_Turn_lever（Reserved)" 6 "Req_PS_ID_Selection" 5 "Req_Stop（请停车)" 4 "Req_SearchingProcess（车位搜索中）" 3 "Req_Slow_Down" 2 "Req_Gear_D" 1 "Req_Function Select" 0 "No Request" ;
VAL_ 405 APA_ActiveSubFun 15 "Reserved" 14 "Reserved" 13 "Reserved" 12 "Reserved" 11 "Reserved" 10 "Park out" 9 "Park In" 8 "Remote parallel  POC" 7 "Remote crossl POC" 6 "Remote parallel Parkin" 5 "Remote cross Parkin" 4 "Automatic parallel park out" 3 "Automatic cross park out" 2 "Automatic Parallel Park in" 1 "Automatic cross park in" 0 "No Active" ;
VAL_ 405 APA_SelectParkSide_Ind 3 "Reserved" 2 "Right" 1 "Left" 0 "None" ;
VAL_ 405 APA_SelectParkTypeInd_Reserved 3 "Reserved" 2 "Parking out" 1 "Parking in" 0 "None" ;
VAL_ 405 APA_Left1stParkSlotType 7 "Reserve" 6 "Reserve" 5 "Reserve" 4 "Reserve" 3 "Reserve" 2 "Cross" 1 "Parallel" 0 "No Park" ;
VAL_ 405 APA_Left2cdParkSlotType 7 "Reserve" 6 "Reserve" 5 "Reserve" 4 "Reserve" 3 "Reserve" 2 "Cross" 1 "Parallel" 0 "No Park" ;
VAL_ 405 APA_APAAvaliable 1 "Avaliable" 0 "Not Avaliable" ;
VAL_ 405 APA_RPAAvaliable 1 "Avaliable" 0 "Not Avaliable" ;
VAL_ 405 APA_Left3rdParkSlotType 7 "Reserve" 6 "Reserve" 5 "Reserve" 4 "Reserve" 3 "Reserve" 2 "Cross" 1 "Parallel" 0 "No Park" ;
VAL_ 405 APA_Right1stParkSlotType 7 "Reserve" 6 "Reserve" 5 "Reserve" 4 "Reserve" 3 "Reserve" 2 "Cross" 1 "Parallel" 0 "No Park" ;
VAL_ 405 APA_Right2cdParkSlotType 7 "Reserve" 6 "Reserve" 5 "Reserve" 4 "Reserve" 3 "Reserve" 2 "Cross" 1 "Parallel" 0 "No Park" ;
VAL_ 405 APA_Right3rdParkSlotType 7 "Reserve" 6 "Reserve" 5 "Reserve" 4 "Reserve" 3 "Reserve" 2 "Cross" 1 "Parallel" 0 "No Park" ;
VAL_ 405 APA_IDCM_SVSIntelligentViewChangeSwitch_St 3 "Reserved" 2 "OFF" 1 "ON" 0 "No commond" ;
VAL_ 405 APA_IDCM_SVSdefaulttopviewSwitch_St 3 "Inhibit" 2 "OFF" 1 "ON" 0 "Reserved" ;
VAL_ 405 APA_IDCM_SVSdefaultnormalviewSwitch_St 3 "Inhibit" 2 "OFF" 1 "ON" 0 "Reserved" ;
VAL_ 405 APA_IDCM_SVSBootAnimationswitch_St 3 "Inhibit" 2 "OFF" 1 "ON" 0 "Reserved" ;
VAL_ 405 APA_SVC_FrontCamera_St 3 "Reserved" 2 "Error" 1 "Blocked" 0 "Normal" ;
VAL_ 405 APA_SVC_LeftCamera_St 3 "Reserved" 2 "Error" 1 "Blocked" 0 "Normal" ;
VAL_ 405 APA_SVC_RightCamera_St 3 "Reserved" 2 "Error" 1 "Blocked" 0 "Normal" ;
VAL_ 405 APA_SVC_RearCamera_St 3 "Reserved" 2 "Error" 1 "Blocked" 0 "Normal" ;
VAL_ 405 APA_SVS_System_St 1 "Available" 0 "Not available" ;
VAL_ 405 APA_SVS_Active_St 1 "Active" 0 "Inactive" ;
VAL_ 405 APA_SVS_SystemUnavailableReson 15 "Reserved" 14 "Reserved" 13 "Reserved" 12 "Reserved" 11 "Reserved" 10 "Reserved" 9 "Reserved" 8 "Reserved" 7 "Reserved" 6 "Reserved" 5 "Reserved" 4 "Reserved" 3 "Reserved" 2 "Reserved" 1 "Error" 0 "No Error" ;
VAL_ 405 APA_IDCM_PASAcousticWarn_St 3 "Inhibit" 2 "OFF" 1 "ON" 0 "Reserved" ;
VAL_ 405 APA_SVS_CurrentView 31 "Reserved" 30 "Reserved" 29 "Reserved" 28 "Reserved" 27 "Reserved" 26 "Reserved" 25 "Reserved" 24 "Reserved" 23 "Reserved" 22 "Reserved" 21 "Reserved" 20 "Reserved" 19 "Top View" 18 "3D_Rear right view" 17 "3D_Rear left view" 16 "3D_Rear view" 15 "3D_Right view" 14 "3D_Left view" 13 "3D_Front right view" 12 "3D_Front left view" 11 "3D_Front View" 10 "2D_Right view" 9 "2D_Left view" 8 "2D_Rear wheel view" 7 "2D_Rear bumper view" 6 "2D_Rear junction view" 5 "2D_Rear view" 4 "2D_Front wheel view" 3 "2D_Front bumper view" 2 "2D_Front junction view" 1 "2D_Front view" 0 "None" ;
VAL_ 405 APA_IDCM_ObjectOverlay_St 3 "Inhibit" 2 "OFF" 1 "ON" 0 "Reserved" ;
VAL_ 405 APA_SVS_BasPlateTex_St 3 "Inhibit" 2 "OFF" 1 "ON" 0 "Reserved" ;
VAL_ 405 APA_IDCM_SVSTrajectoryOverlay_St 3 "Inhibit" 2 "OFF" 1 "ON" 0 "Reserved" ;
VAL_ 405 APA_SVSMODE_FD 3 "Reserved" 2 "3D mode" 1 "Standard mode" 0 "No request" ;
VAL_ 405 APA_FrontPMAEB_St 15 "Reserved" 14 "Reserved" 13 "Reserved" 12 "Reserved" 11 "Reserved" 10 "Reserved" 9 "Reserved" 8 "Error" 7 "Finished without override" 6 "Finished with override" 5 "Standstill" 4 "AEB active" 3 "Prefill" 2 "Ready" 1 "Inactive" 0 "OFF" ;
VAL_ 405 APA_RearPMAEB_St 15 "Reserved" 14 "Reserved" 13 "Reserved" 12 "Reserved" 11 "Reserved" 10 "Reserved" 9 "Reserved" 8 "Error" 7 "Finished without override" 6 "Finished with override" 5 "Standstill" 4 "AEB active" 3 "Prefill" 2 "Ready" 1 "Inactive" 0 "OFF" ;
VAL_ 405 APA_PMAEB_Setting_St 7 "Reserved" 6 "Reserved" 5 "Reserved" 4 "Reserved" 3 "Inhibit" 2 "Off" 1 "On" 0 "Default" ;
VAL_ 584 APA_PAS_SwFdbkIDCMPAS_Reserved 1 "True" 0 "False" ;
VAL_ 584 APA_PAS_WorkingMode 15 "Reserved" 14 "Reserved" 13 "Reserved" 12 "System Inhibited(Reserved)" 11 "Rear failure and Front inactive(Reserved)" 10 "Front failure and Rear inactive(Reserved)" 9 "SystemFailure" 8 "FrontRearActive" 7 "RearActiveAndFrontFailure" 6 "RearActive(Reserved)" 5 "FrontActiveAndRearFailure" 4 "FrontActive(Reserved)" 3 "StandbyAndRearFailure(Reserved)" 2 "StandbyAndFrontFailure(Reserved)" 1 "Standby" 0 "Off" ;
VAL_ 584 APA_PAS_BuzzerWarning 7 "Reserved" 6 "Reserved" 5 "Reserved" 4 "Reserved" 3 "Level3(80<Distance<=150)" 2 "Level2(30<Distance<=80)" 1 "Level1(distance<30)" 0 "No object；" ;
VAL_ 584 APA_DefaultAeraObstacleWarning_Reserved 3 "Reserved" 2 "Reserved" 1 "Warning" 0 "No Warning" ;
VAL_ 584 APA_PASFLDistance 255 "No Obstacle Detected" 254 "Invalid" 253 "Invalid" 252 "Invalid" 251 "Invalid" ;
VAL_ 584 APA_PASFMLDistance 255 "No Obstacle Detected" 254 "Invalid" 253 "Invalid" 252 "Invalid" 251 "Invalid" ;
VAL_ 584 APA_PASFMRDistance 255 "No Obstacle Detected" 254 "Invalid" 253 "Invalid" 252 "Invalid" 251 "Invalid" ;
VAL_ 584 APA_PASFRDistance 255 "No Obstacle Detected" 254 "Invalid" 253 "Invalid" 252 "Invalid" 251 "Invalid" ;
VAL_ 584 APA_PASRLDistance 255 "No Obstacle Detected" 254 "Invalid" 253 "Invalid" 252 "Invalid" 251 "Invalid" ;
VAL_ 584 APA_PASRRDistance 255 "No Obstacle Detected" 254 "Invalid" 253 "Invalid" 252 "Invalid" 251 "Invalid" ;
VAL_ 584 APA_PASRMLDistance 255 "No Obstacle Detected" 254 "Invalid" 253 "Invalid" 252 "Invalid" 251 "Invalid" ;
VAL_ 584 APA_PASRMRDistance 255 "No Obstacle Detected" 254 "Invalid" 253 "Invalid" 252 "Invalid" 251 "Invalid" ;
VAL_ 584 APA_FSideAreaScand 1 "Scaning" 0 "No Scan" ;
VAL_ 584 APA_FMSideAreaScand 1 "Scaning" 0 "No Scan" ;
VAL_ 584 APA_RSideAreaScand 1 "Scaning" 0 "No Scan" ;
VAL_ 584 APA_RMSideAreaScand 1 "Scaning" 0 "No Scan" ;
VAL_ 584 APA_SDW_FLSideDistance 255 "No Obstacle Detected" 254 "Invalid" 253 "Invalid" 252 "Invalid" 251 "Invalid" ;
VAL_ 584 APA_SDW_FRSideDistance 255 "No Obstacle Detected" 254 "Invalid" 253 "Invalid" 252 "Invalid" 251 "Invalid" ;
VAL_ 584 APA_SDW_RLSideDistance 255 "No Obstacle Detected" 254 "Invalid" 253 "Invalid" 252 "Invalid" 251 "Invalid" ;
VAL_ 584 APA_SDW_RRSideDistance 255 "No Obstacle Detected" 254 "Invalid" 253 "Invalid" 252 "Invalid" 251 "Invalid" ;
VAL_ 584 APA_SDW_FMLSideDistance 255 "No Obstacle Detected" 254 "Invalid" 253 "Invalid" 252 "Invalid" 251 "Invalid" ;
VAL_ 584 APA_SDW_FMRSideDistance 255 "No Obstacle Detected" 254 "Invalid" 253 "Invalid" 252 "Invalid" 251 "Invalid" ;
VAL_ 584 APA_SDW_RMLSideDistance 255 "No Obstacle Detected" 254 "Invalid" 253 "Invalid" 252 "Invalid" 251 "Invalid" ;
VAL_ 584 APA_SDW_RMRSideDistance 255 "No Obstacle Detected" 254 "Invalid" 253 "Invalid" 252 "Invalid" 251 "Invalid" ;
VAL_ 586 APA_L1SlotEdge1LateralPosition 65535 "Invalid" ;
VAL_ 586 APA_L1SlotEdge1LongitudinalPosition 65535 "Invalid" ;
VAL_ 586 APA_L1SlotEdge2LateralPosition 65535 "Invalid" ;
VAL_ 586 APA_L1SlotEdge2LongitudinalPosition 65535 "Invalid" ;
VAL_ 586 APA_L1SlotEdge3LateralPosition_Reserved 65535 "Invalid" ;
VAL_ 586 APA_L1SlotEdge3LongitudinalPosition_Reserved 65535 "Invalid" ;
VAL_ 586 APA_L1SlotEdge4LateralPosition_Reserved 65535 "Invalid" ;
VAL_ 586 APA_L1SlotEdge4LongitudinalPosition_Reserved 65535 "Invalid" ;
VAL_ 586 APA_L2SlotEdge1LateralPosition 65535 "Invalid" ;
VAL_ 586 APA_L2SlotEdge1LongitudinalPosition 65535 "Invalid" ;
VAL_ 586 APA_L2SlotEdge2LateralPosition 65535 "Invalid" ;
VAL_ 586 APA_L2SlotEdge2LongitudinalPosition 65535 "Invalid" ;
VAL_ 586 APA_L2SlotEdge3LateralPosition_Reserved 65535 "Invalid" ;
VAL_ 586 APA_L2SlotEdge3LongitudinalPosition_Reserved 65535 "Invalid" ;
VAL_ 586 APA_L2SlotEdge4LateralPosition_Reserved 65535 "Invalid" ;
VAL_ 586 APA_L2SlotEdge4LongitudinalPosition_Reserved 65535 "Invalid" ;
VAL_ 588 APA_L3SlotEdge1LateralPosition 65535 "Invalid" ;
VAL_ 588 APA_L3SlotEdge1LongitudinalPosition 65535 "Invalid" ;
VAL_ 588 APA_L3SlotEdge2LateralPosition 65535 "Invalid" ;
VAL_ 588 APA_L3SlotEdge2LongitudinalPosition 65535 "Invalid" ;
VAL_ 588 APA_L3SlotEdge3LateralPosition_Reserved 65535 "Invalid" ;
VAL_ 588 APA_L3SlotEdge3LongitudinalPosition_Reserved 65535 "Invalid" ;
VAL_ 588 APA_L3SlotEdge4LateralPosition_Reserved 65535 "Invalid" ;
VAL_ 588 APA_L3SlotEdge4LongitudinalPosition_Reserved 65535 "Invalid" ;
VAL_ 588 APA_R1SlotEdge1LateralPosition 65535 "Invalid" ;
VAL_ 588 APA_R1SlotEdge1LongitudinalPosition 65535 "Invalid" ;
VAL_ 588 APA_R1SlotEdge2LateralPosition 65535 "Invalid" ;
VAL_ 588 APA_R1SlotEdge2LongitudinalPosition 65535 "Invalid" ;
VAL_ 588 APA_R1SlotEdge3LateralPosition_Reserved 65535 "Invalid" ;
VAL_ 588 APA_R1SlotEdge3LongitudinalPosition_Reserved 65535 "Invalid" ;
VAL_ 588 APA_R1SlotEdge4LateralPosition_Reserved 65535 "Invalid" ;
VAL_ 588 APA_R1SlotEdge4LongitudinalPosition_Reserved 65535 "Invalid" ;
VAL_ 590 APA_R2SlotEdge1LateralPosition 65535 "Invalid" ;
VAL_ 590 APA_R2SlotEdge1LongitudinalPosition 65535 "Invalid" ;
VAL_ 590 APA_R2SlotEdge2LateralPosition 65535 "Invalid" ;
VAL_ 590 APA_R2SlotEdge2LongitudinalPosition 65535 "Invalid" ;
VAL_ 590 APA_R2SlotEdge3LateralPosition_Reserved 65535 "Invalid" ;
VAL_ 590 APA_R2SlotEdge3LongitudinalPosition_Reserved 65535 "Invalid" ;
VAL_ 590 APA_R2SlotEdge4LateralPosition_Reserved 65535 "Invalid" ;
VAL_ 590 APA_R2SlotEdge4LongitudinalPosition_Reserved 65535 "Invalid" ;
VAL_ 590 APA_R3SlotEdge1LateralPosition 65535 "Invalid" ;
VAL_ 590 APA_R3SlotEdge1LongitudinalPosition 65535 "Invalid" ;
VAL_ 590 APA_R3SlotEdge2LateralPosition 65535 "Invalid" ;
VAL_ 590 APA_R3SlotEdge2LongitudinalPosition 65535 "Invalid" ;
VAL_ 590 APA_R3SlotEdge3LateralPosition_Reserved 65535 "Invalid" ;
VAL_ 590 APA_R3SlotEdge3LongitudinalPosition_Reserved 65535 "Invalid" ;
VAL_ 590 APA_R3SlotEdge4LateralPosition_Reserved 65535 "Invalid" ;
VAL_ 590 APA_R3SlotEdge4LongitudinalPosition_Reserved 65535 "Invalid" ;
VAL_ 596 DSM_DriverWatchRegion 15 "Reserved" 14 "Reserved" 13 "Reserved" 12 "Reserved" 11 "Reserved" 10 "Reserved" 9 "Reserved" 8 "Reserved" 7 "Reserved" 6 "Reserved" 5 "Attention is Center Console" 4 "Attention is Drivers Lap" 3 "Attention is Off Road" 2 "Attention is On Road" 1 "Unknown" 0 "Unavailable" ;
VAL_ 596 DSM_SystemError_St 7 "Reserved" 6 "Reserved" 5 "Reserved" 4 "Reserved" 3 "Reserved" 2 "Driver monitor camera error" 1 "Available" 0 "Unavailable" ;
VAL_ 596 DSM_DriverDetect_St 7 "Reserved" 6 "Reserved" 5 "Reserved" 4 "Reserved" 3 "Head detected" 2 "Head and Eye detected" 1 "Not detected" 0 "Unavailable" ;
VAL_ 596 DSM_FatigueFunction_St 3 "Reserved" 2 "Active" 1 "Standby" 0 "OFF" ;
VAL_ 596 DSM_FatigueWarn_St 7 "Reserved" 6 "Reserved" 5 "Reserved" 4 "Severe State" 3 "Cautionary State" 2 "Attentive State" 1 "Unknow" 0 "Unavailable" ;
VAL_ 596 DSM_L3DriverFatigue_St 7 "Reserved" 6 "Reserved" 5 "Reserved" 4 "Severe State" 3 "Cautionary State" 2 "Attentive State" 1 "Unknow" 0 "Unavailable" ;
VAL_ 596 DSM_L3DriverDistraction_St 7 "Reserved" 6 "Reserved" 5 "Reserved" 4 "Reserved" 3 "Non Distractive" 2 "Distractive" 1 "Unknown" 0 "Unavailable" ;
VAL_ 596 DSM_Response_RecognitionFaceStatus 7 "Reserved" 6 "Reserved" 5 "Reserved" 4 "Reserved" 3 "Recognize fail" 2 "Recognize success" 1 "On recognizing" 0 "Invalid" ;
VAL_ 596 DSM_Response_UserID 10 "User ID A" 9 "User ID 9" 8 "User ID 8" 7 "User ID 7" 6 "User ID 6" 5 "User ID 5" 4 "User ID 4" 3 "User ID 3" 2 "User ID 2" 1 "User ID 1" 0 "Invalid" ;
VAL_ 385 ACU_FrontCrashOutput_St 1 "Crash" 0 "No Crash" ;
VAL_ 385 ACU_DriverSideCrashOutput_St 1 "Crash" 0 "No Crash" ;
VAL_ 385 ACU_PassengerSideCrashOutput_St 1 "Crash" 0 "No Crash" ;
VAL_ 385 ACU_RearSideCrashOutput_St 1 "Crash" 0 "No Crash" ;
VAL_ 385 ACU_WarnLampSt 3 "Not Used" 2 "Flashing" 1 "Lamp ON(default)" 0 "Lamp Off" ;
VAL_ 385 ACU_PassengerAirbagSt 1 "Passenger Airbag OFF" 0 "Passenger Airbag ON(default)" ;
VAL_ 385 ACU_DriverSeatBelt_St 1 "Tied" 0 "Not tied" ;
VAL_ 385 ACU_DriverSeatBelt_Valid 1 "Valid" 0 "Invalid" ;
VAL_ 385 ACU_DriverSBR_St 3 "Not Used" 2 "Flashing" 1 "Lamp ON(default)" 0 "Lamp Off" ;
VAL_ 385 ACU_PassengerSBR_St 3 "Not Used" 2 "Flashing" 1 "Lamp ON(default)" 0 "Lamp Off" ;
VAL_ 385 ACU_SRLSBR_St 3 "Not Used" 2 "Flashing" 1 "Lamp ON(default)" 0 "Lamp Off" ;
VAL_ 385 ACU_SRRSBR_St 3 "Not Used" 2 "Flashing" 1 "Lamp ON(default)" 0 "Lamp Off" ;
VAL_ 385 ACU_SeatBeltSoundReminder_St 1 "Gong ON" 0 "Gong OFF(default)" ;
VAL_ 386 ACU_LongitudeAccelerationSensor_St 1 "Valid" 0 "Invalid" ;
VAL_ 386 ACU_LateralAccelerationSensor_St 1 "Valid" 0 "Invalid" ;
VAL_ 417 ESC_Intervention 1 "Active" 0 "Not active" ;
VAL_ 417 ESC_ESCError 1 "On" 0 "Off" ;
VAL_ 417 ESC_TCSIntervention 1 "Active" 0 "Not active" ;
VAL_ 417 ESC_VDCIntervention 1 "Active" 0 "Not active" ;
VAL_ 417 ESC_ABSIntervention 1 "Active" 0 "Not active" ;
VAL_ 417 ESC_ABSError 1 "On" 0 "Off" ;
VAL_ 417 ESC_EBDIntervention 1 "Active" 0 "Not active" ;
VAL_ 417 ESC_EBDError 1 "On" 0 "Off" ;
VAL_ 417 ESC_BraBoostwarning 3 "invalid" 2 "red" 1 "yellow" 0 "off" ;
VAL_ 417 ESC_VehicleStandstill_St 1 "Standstill" 0 "Not Standstill" ;
VAL_ 417 ESC_VehicleStandstillSt_Valid 1 "Valid" 0 "Invalid" ;
VAL_ 417 ESC_AVHSt 3 "Reserved" 2 "Standby" 1 "Intervention" 0 "Off" ;
VAL_ 417 ESC_AVHAvailable 1 "Available" 0 "Not available" ;
VAL_ 417 ESC_HHCSt 1 "Active" 0 "Not active" ;
VAL_ 417 ESC_HHCAvailable 1 "Available" 0 "Not available" ;
VAL_ 417 ESC_HDCAvailable 1 "Available" 0 "Not available" ;
VAL_ 417 ESC_HDC_St 3 "Reserved" 2 "On active braking" 1 "On not active braking" 0 "OFF" ;
VAL_ 417 ESC_HBB_St 3 "HBB Disabled" 2 "HBB FailedBoostBackup" 1 "HBB FailedBoost" 0 "HBB Normal Mode" ;
VAL_ 417 ESC_HBBActive 1 "Active" 0 "Not active" ;
VAL_ 417 ESC_CDP_St 1 "Active" 0 "Not active" ;
VAL_ 417 ESC_CDPAvailable 1 "Available" 0 "Not available" ;
VAL_ 417 ESC_CruiseControlShutDown 1 "Switch off cruise control" 0 "Not switch off cruise control" ;
VAL_ 417 ESC_PataLamp 1 "TCS Enable" 0 "TCS Disable" ;
VAL_ 417 ESC_BrakeLight_Req 1 "Request" 0 "No Request" ;
VAL_ 417 ESC_EmergencyBrakeLight_Req 1 "Active" 0 "Not active" ;
VAL_ 417 ESC_EPB_St 7 "Invalid" 6 "Reserved" 5 "Reserved" 4 "Releasing（卡钳正处于释放过程中）" 3 "Locking（卡钳正处于夹紧过程中）" 2 "Closed（卡钳处于夹紧状态）" 1 "Released（卡钳处于释放状态）" 0 "Reserved" ;
VAL_ 417 ESC_EPBFunctionLamp 3 "Reserved" 2 "Flash 动态制动" 1 "StaticOn" 0 "OFF" ;
VAL_ 417 ESC_EPBFailLamp 3 "Reserved" 2 "Flash查看hmi（诊断模式）" 1 "StaticOn" 0 "OFF" ;
VAL_ 417 ESC_EPBWarnMessage 3 "Reserved" 2 "Gradient High (坡道过大)" 1 "Brake Force Not Enough (制动力不足)" 0 "NoWarning(无故障)" ;
VAL_ 417 ESC_EPBSwitch_St 3 "Reserved" 2 "Applied" 1 "Released" 0 "Not active" ;
VAL_ 417 ESC_EPBTipInfo 3 "Reserved" 2 "Lock the seat belt then auto release is activated (驾驶员踏下油门踏板，且扭矩足够，且驾驶员安全带未系时提醒)" 1 "Press the brake pedal first. then release the APB button (驾驶员按下EPB释放开关，且未踩制动踏板时提醒)" 0 "NoTip(无提示)" ;
VAL_ 417 ESC_EPBError 1 "Error" 0 "No error" ;
VAL_ 417 ESC_HBAActive 1 "Active" 0 "Inactive" ;
VAL_ 417 ESC_HBAAvailable 1 "Available" 0 "Not available" ;
VAL_ 417 ESC_EPBSwitchSt_Valid 1 "Valid" 0 "Not valid" ;
VAL_ 417 ESC_BrakePedalApplied_OnlyForIV2 1 "brake pedal applied" 0 "brake pedal not applied" ;
VAL_ 417 ESC_BrakePedalApplied_St_OnlyForIV2 3 "Reserved" 2 "Fault" 1 "Normal" 0 "Init" ;
VAL_ 417 ESC_AVH_DriverAbsentWarn 1 "Warning" 0 "No Warning" ;
VAL_ 417 ESC_VehicleSpeed 8191 "Invalid" ;
VAL_ 417 ESC_VehicleSpeed_Valid 1 "Valid" 0 "Invalid" ;
VAL_ 199 ESC_CampingMode_Rsp 1 "Active" 0 "Inactive" ;
VAL_ 199 ESC_CampingModeWarning 1 "Active" 0 "Inactive" ;
VAL_ 199 ESC_WorkMode 15 "Invalid" 14 "Reserved" 13 "Reserved" 12 "Reserved" 11 "Reserved" 10 "Reserved" 9 "Reserved" 8 "Reserved" 7 "Reserved" 6 "Offroad" 5 "Soft sand" 4 "winter" 3 "Rervesed" 2 "Sport" 1 "Comfort" 0 "Standard" ;
VAL_ 199 ESC_ModeChangeEnable 1 "Enable" 0 "Disable" ;
VAL_ 190 EB_OutputRodDriver 4095 "Invalid" ;
VAL_ 190 EB_OutputRodDriver_St 3 "Reserved" 2 "Fault" 1 "Normal" 0 "Init" ;
VAL_ 428 EB_BrakePedalApplied 1 "brake pedal applied" 0 "brake pedal not applied" ;
VAL_ 428 EB_BrakePedalApplied_St 3 "Reserved" 2 "Fault" 1 "Normal" 0 "Init" ;
VAL_ 428 EB_WarningLampCtl_Req 1 "Warning lamp requested" 0 "No request to the warning lamp" ;
VAL_ 428 EB_BrakeMode 7 "Invalid" 3 "Reserved" 2 "hard" 1 "middle" 0 "light" ;
VAL_ 428 EB_ModeChangeEnable 3 "Reserved" 2 "Reserved" 1 "Enable" 0 "Disable" ;
VAL_ 429 EPS_Failure_St 3 "Invalid" 2 "EPS Heavy Level FailureI ndication (Red)" 1 "Light Level Failure Indication (Yellow)" 0 "EPS No Failure (Indicatio off)" ;
VAL_ 429 EPS_WorkMode 7 "Invalid" 6 "Reserved" 5 "Reserved" 4 "Reserved" 3 "Reserved" 2 "Light" 1 "Mid" 0 "Heavy" ;
VAL_ 429 EPS_ModeChangeEnable 1 "Enable" 0 "Disable" ;
VAL_ 429 EPS_HADError_RequestHADState 1 "Invalid" 0 "Valid" ;
VAL_ 429 EPS_HADError_RequestRackPosition 1 "Invalid" 0 "Valid" ;
VAL_ 429 EPS_HADError_ExternalMasterReq 1 "Set" 0 "Not_Set" ;
VAL_ 429 EPS_HADError_ECUState 1 "Error" 0 "Normal" ;
VAL_ 429 EPS_HADError_ErrorFlagFromRemoteECU 1 "Set" 0 "Not_Set" ;
VAL_ 429 EPS_HADError_HADStateMachineMonitorFault 1 "Active" 0 "Inactive" ;
VAL_ 429 EPS_HADOff_RackPositionSync 1 "Error" 0 "Normal" ;
VAL_ 429 EPS_HADOff_VehicleSpeedLimitation 1 "Active" 0 "Inactive" ;
VAL_ 429 EPS_HADOff_ErrorFromRemote 1 "Active" 0 "Inactive" ;
VAL_ 429 EPS_HADOff_EmergencyTakeOver 1 "Active" 0 "Inactive" ;
VAL_ 429 EPS_HADOff_SafetyDriver_TBT 1 "Active" 0 "Inactive" ;
VAL_ 429 EPS_HADOff_SafetyDriver_RackSpeed 1 "Active" 0 "Inactive" ;
VAL_ 429 EPS_HADOff_IPCStatus 1 "Error" 0 "Normal" ;
VAL_ 429 EPS_HADOff_StayInInitialState 1 "Error" 0 "Normal" ;
VAL_ 429 EPS_HADOff_TorqueReduction 1 "Active" 0 "Inactive" ;
VAL_ 429 EPS_HADOff_WaterSensor 1 "Error" 0 "Normal" ;
VAL_ 429 EPS_HADOff_MinVehicleSpeed 1 "Invalid" 0 "Valid" ;
VAL_ 429 EPS_HADOff_GroundConnection 1 "Error" 0 "Normal" ;
VAL_ 429 EPS_HADOff_FunctionCoordinator 1 "Active" 0 "Inactive" ;
VAL_ 429 EPS_HADOff_StickSlipWarning 1 "Active" 0 "Inactive" ;
VAL_ 429 EPS_HADOff_TBTStatus 1 "Error" 0 "Normal" ;
VAL_ 429 EPS_HADOff_RPCTorqueValue 1 "Too High" 0 "Normal" ;
VAL_ 429 EPS_HADOff_DoubleDiagnosisState 1 "Error" 0 "Normal" ;
VAL_ 429 EPS_HADOff_FADERMonitor 1 "Error" 0 "Normal" ;
VAL_ 429 EPS_HADOff_SupplyVoltageReduce 1 "Active" 0 "Inactive" ;
VAL_ 184 RWS_Status 3 "RWS Fault (Can not move)" 2 "Degrade(Return to zero)" 1 "Normal" 0 "Initializing" ;
VAL_ 184 RWS_Travel_valid 1 "Init or fault value" 0 "valid value" ;
VAL_ 184 RWS_WarningLamp 3 "reserved" 2 "Red Lamp" 1 "Yellow Lamp" 0 "No" ;
VAL_ 425 AIRS_WorkMode 7 "Invalid" 6 "Reserved" 5 "Reserved" 4 "Reserved" 3 "Reserved" 2 "Speed Dependent Mode 3" 1 "Speed Dependent Mode 2" 0 "Speed Dependent Mode 1" ;
VAL_ 425 AIRS_ModeChangeEnable 1 "Enable" 0 "Disable" ;
VAL_ 425 AIRS_CDCWorkMode 7 "Invalid" 2 "Hard" 1 "Soft" 0 "Standard" ;
VAL_ 425 AIRS_CDCModeChangeEnable 1 "Enable" 0 "Disable" ;
VAL_ 425 AIRS_EasyloadModeIndicated 1 "Active" 0 "Inactive" ;
VAL_ 425 AIRS_EasyloadAvailability 1 "Available" 0 "Not Available" ;
VAL_ 425 AIRS_VehicleSpeedDependentLevelSwitchSt 1 "Off" 0 "On" ;
VAL_ 425 AIRS_VehicleSpeedDependentLevelSwitchAvaliability 1 "Available" 0 "Not Available" ;
VAL_ 425 AIRS_LiftModeAvailability 1 "Available" 0 "Not Available" ;
VAL_ 425 AIRS_LiftModeIndicated 1 "Active" 0 "Inactive" ;
VAL_ 425 AIRS_LevelCalibrationComplete 1 "Level calibration completed" 0 "Level calibration not completed" ;
VAL_ 425 AIRS_ErrorLampRequest 3 "Invalid" 2 "Lamp request level 2 (Red)" 1 "Lamp request level 1 (orange)" 0 "No lamp request" ;
VAL_ 425 AIRS_DampingError 1 "Error" 0 "No error" ;
VAL_ 425 AIRS_ErrorStatus 1 "Error" 0 "No Error" ;
VAL_ 425 AIRS_SystemTemporaryNotAvailable 8 "Level control restriction by door state" 4 "Level control restriction by operation mode" 2 "Actuator temperature restriction active" 1 "Voltage/Energy too low" 0 "Init(no restriction)" ;
VAL_ 425 AIRS_ActionState 64 "action due to automatic level change (Speed dependent leveling)" 32 "action due to level change request by driver" 16 "action due to readjustment" 8 "EasyLoadingActiveSwitching" 4 "Pending" 2 "Lifting" 1 "Lowering" 0 "No action" ;
VAL_ 425 AirS_OffRoadAvaliability 1 "available" 0 "Not available" ;
VAL_ 425 AirS_OffRoadExitCommand 1 "command" 0 "No command" ;
VAL_ 425 AIRS_TargetHeightIndication 7 "Invalid" 6 "Reserved" 5 "Reserved" 4 "Reserved" 3 "Very Low Height" 2 "Low Height" 1 "Normal Height" 0 "High Height" ;
VAL_ 425 AIRS_Height_FL 255 "Invalid" ;
VAL_ 425 AIRS_Height_FR 255 "Invalid" ;
VAL_ 425 AIRS_Height_RL 255 "Invalid" ;
VAL_ 425 AIRS_Height_RR 255 "Invalid" ;
